VERSION "dbc-export 1 2026.26.6.5"

NS_ :

BS_:

BU_: APB APP APS DAS DPB EPAS3S EPASTS ESP GTW IBST IDB PARK RADC RCM RCM2 RCM3 RCU TPMS TRCM USM

BO_ 1470 IDB_alertLog: 8 IDB
 SG_ IDB_alertID M : 0|8@1+ (1,0) [0|255] "" Vector__XXX
 SG_ IDB_alertState : 15|1@1+ (1,0) [0|1] "" Vector__XXX
 SG_ IDB_a014_wheelSpeedSensorFreq m14 : 16|1@1+ (1,0) [0|1] "" Vector__XXX
 SG_ IDB_a014_wheelSpeedSensorPhase m14 : 17|1@1+ (1,0) [0|1] "" Vector__XXX
 SG_ IDB_a014_wheelSpeedSensorMisinst m14 : 18|1@1+ (1,0) [0|1] "" Vector__XXX
 SG_ IDB_a014_wheelSpeedSensorWrongEx m14 : 19|1@1+ (1,0) [0|1] "" Vector__XXX
 SG_ IDB_a014_wheelSpeedSensorSpeedJu m14 : 20|1@1+ (1,0) [0|1] "" Vector__XXX
 SG_ IDB_a014_wheelSpeedSensorSp_0001 m14 : 21|1@1+ (1,0) [0|1] "" Vector__XXX
 SG_ IDB_a014_wheelSpeedSensorAirGap m14 : 22|1@1+ (1,0) [0|1] "" Vector__XXX
 SG_ IDB_a014_wheelSpeedSensorBIST m14 : 23|1@1+ (1,0) [0|1] "" Vector__XXX
 SG_ IDB_a014_wheelSpeedSensorLeakage m14 : 24|1@1+ (1,0) [0|1] "" Vector__XXX
 SG_ IDB_a014_wheelSpeedSensorOverTem m14 : 25|1@1+ (1,0) [0|1] "" Vector__XXX
 SG_ IDB_a014_wheelSpeedSensorSh_0001 m14 : 26|1@1+ (1,0) [0|1] "" Vector__XXX
 SG_ IDB_a014_wheelSpeedSensorShortTo m14 : 27|1@1+ (1,0) [0|1] "" Vector__XXX
 SG_ IDB_a014_wheelSpeedSensorOpen m14 : 28|1@1+ (1,0) [0|1] "" Vector__XXX
 SG_ IDB_a015_wheelSpeedSensorFreq m15 : 16|1@1+ (1,0) [0|1] "" Vector__XXX
 SG_ IDB_a015_wheelSpeedSensorPhase m15 : 17|1@1+ (1,0) [0|1] "" Vector__XXX
 SG_ IDB_a015_wheelSpeedSensorMisinst m15 : 18|1@1+ (1,0) [0|1] "" Vector__XXX
 SG_ IDB_a015_wheelSpeedSensorWrongEx m15 : 19|1@1+ (1,0) [0|1] "" Vector__XXX
 SG_ IDB_a015_wheelSpeedSensorSpeedJu m15 : 20|1@1+ (1,0) [0|1] "" Vector__XXX
 SG_ IDB_a015_wheelSpeedSensorSp_0001 m15 : 21|1@1+ (1,0) [0|1] "" Vector__XXX
 SG_ IDB_a015_wheelSpeedSensorAirGap m15 : 22|1@1+ (1,0) [0|1] "" Vector__XXX
 SG_ IDB_a015_wheelSpeedSensorBIST m15 : 23|1@1+ (1,0) [0|1] "" Vector__XXX
 SG_ IDB_a015_wheelSpeedSensorLeakage m15 : 24|1@1+ (1,0) [0|1] "" Vector__XXX
 SG_ IDB_a015_wheelSpeedSensorOverTem m15 : 25|1@1+ (1,0) [0|1] "" Vector__XXX
 SG_ IDB_a015_wheelSpeedSensorSh_0001 m15 : 26|1@1+ (1,0) [0|1] "" Vector__XXX
 SG_ IDB_a015_wheelSpeedSensorShortTo m15 : 27|1@1+ (1,0) [0|1] "" Vector__XXX
 SG_ IDB_a015_wheelSpeedSensorOpen m15 : 28|1@1+ (1,0) [0|1] "" Vector__XXX
 SG_ IDB_a016_wheelSpeedSensorFreq m16 : 16|1@1+ (1,0) [0|1] "" Vector__XXX
 SG_ IDB_a016_wheelSpeedSensorPhase m16 : 17|1@1+ (1,0) [0|1] "" Vector__XXX
 SG_ IDB_a016_wheelSpeedSensorMisinst m16 : 18|1@1+ (1,0) [0|1] "" Vector__XXX
 SG_ IDB_a016_wheelSpeedSensorWrongEx m16 : 19|1@1+ (1,0) [0|1] "" Vector__XXX
 SG_ IDB_a016_wheelSpeedSensorSpeedJu m16 : 20|1@1+ (1,0) [0|1] "" Vector__XXX
 SG_ IDB_a016_wheelSpeedSensorSp_0001 m16 : 21|1@1+ (1,0) [0|1] "" Vector__XXX
 SG_ IDB_a016_wheelSpeedSensorAirGap m16 : 22|1@1+ (1,0) [0|1] "" Vector__XXX
 SG_ IDB_a016_wheelSpeedSensorBIST m16 : 23|1@1+ (1,0) [0|1] "" Vector__XXX
 SG_ IDB_a016_wheelSpeedSensorLeakage m16 : 24|1@1+ (1,0) [0|1] "" Vector__XXX
 SG_ IDB_a016_wheelSpeedSensorOverTem m16 : 25|1@1+ (1,0) [0|1] "" Vector__XXX
 SG_ IDB_a016_wheelSpeedSensorSh_0001 m16 : 26|1@1+ (1,0) [0|1] "" Vector__XXX
 SG_ IDB_a016_wheelSpeedSensorShortTo m16 : 27|1@1+ (1,0) [0|1] "" Vector__XXX
 SG_ IDB_a016_wheelSpeedSensorOpen m16 : 28|1@1+ (1,0) [0|1] "" Vector__XXX
 SG_ IDB_a017_wheelSpeedSensorFreq m17 : 16|1@1+ (1,0) [0|1] "" Vector__XXX
 SG_ IDB_a017_wheelSpeedSensorPhase m17 : 17|1@1+ (1,0) [0|1] "" Vector__XXX
 SG_ IDB_a017_wheelSpeedSensorMisinst m17 : 18|1@1+ (1,0) [0|1] "" Vector__XXX
 SG_ IDB_a017_wheelSpeedSensorWrongEx m17 : 19|1@1+ (1,0) [0|1] "" Vector__XXX
 SG_ IDB_a017_wheelSpeedSensorSpeedJu m17 : 20|1@1+ (1,0) [0|1] "" Vector__XXX
 SG_ IDB_a017_wheelSpeedSensorSp_0001 m17 : 21|1@1+ (1,0) [0|1] "" Vector__XXX
 SG_ IDB_a017_wheelSpeedSensorAirGap m17 : 22|1@1+ (1,0) [0|1] "" Vector__XXX
 SG_ IDB_a017_wheelSpeedSensorBIST m17 : 23|1@1+ (1,0) [0|1] "" Vector__XXX
 SG_ IDB_a017_wheelSpeedSensorLeakage m17 : 24|1@1+ (1,0) [0|1] "" Vector__XXX
 SG_ IDB_a017_wheelSpeedSensorOverTem m17 : 25|1@1+ (1,0) [0|1] "" Vector__XXX
 SG_ IDB_a017_wheelSpeedSensorSh_0001 m17 : 26|1@1+ (1,0) [0|1] "" Vector__XXX
 SG_ IDB_a017_wheelSpeedSensorShortTo m17 : 27|1@1+ (1,0) [0|1] "" Vector__XXX
 SG_ IDB_a017_wheelSpeedSensorOpen m17 : 28|1@1+ (1,0) [0|1] "" Vector__XXX
 SG_ IDB_a020_canSignalValidity m20 : 16|1@1+ (1,0) [0|1] "" Vector__XXX
 SG_ IDB_a020_signalValueCrosscheck m20 : 17|1@1+ (1,0) [0|1] "" Vector__XXX
 SG_ IDB_a030_primaryExternalCircuitL m30 : 16|1@1+ (1,0) [0|1] "" Vector__XXX
 SG_ IDB_a030_secondaryExternalCircui m30 : 17|1@1+ (1,0) [0|1] "" Vector__XXX
 SG_ IDB_a030_primaryChamberInternalL m30 : 18|1@1+ (1,0) [0|1] "" Vector__XXX
 SG_ IDB_a030_syncModeInternalLeakage m30 : 19|1@1+ (1,0) [0|1] "" Vector__XXX
 SG_ IDB_a030_secondaryChamberInterna m30 : 20|1@1+ (1,0) [0|1] "" Vector__XXX
 SG_ IDB_a030_masterCylinderInternalL m30 : 21|1@1+ (1,0) [0|1] "" Vector__XXX
 SG_ IDB_a060_validityOnChassisBus m60 : 16|1@1+ (1,0) [0|1] "" Vector__XXX
 SG_ IDB_a060_validityOnPartyBus m60 : 17|1@1+ (1,0) [0|1] "" Vector__XXX
 SG_ IDB_a061_validityOnChassisBus m61 : 16|1@1+ (1,0) [0|1] "" Vector__XXX
 SG_ IDB_a061_validityOnPartyBus m61 : 17|1@1+ (1,0) [0|1] "" Vector__XXX
 SG_ IDB_a063_validityOnChassisBus m63 : 16|1@1+ (1,0) [0|1] "" Vector__XXX
 SG_ IDB_a063_validityOnPartyBus m63 : 17|1@1+ (1,0) [0|1] "" Vector__XXX
 SG_ IDB_a064_validityOnChassisBus m64 : 16|1@1+ (1,0) [0|1] "" Vector__XXX
 SG_ IDB_a064_validityOnPartyBus m64 : 17|1@1+ (1,0) [0|1] "" Vector__XXX
 SG_ IDB_a065_validityOnChassisBus m65 : 16|1@1+ (1,0) [0|1] "" Vector__XXX
 SG_ IDB_a065_validityOnPartyBus m65 : 17|1@1+ (1,0) [0|1] "" Vector__XXX
 SG_ IDB_a106_qualifierValidity m106 : 16|1@1+ (1,0) [0|1] "" Vector__XXX
 SG_ IDB_a106_signalNotAvailable m106 : 17|1@1+ (1,0) [0|1] "" Vector__XXX
 SG_ IDB_a107_qualifierValidity m107 : 16|1@1+ (1,0) [0|1] "" Vector__XXX
 SG_ IDB_a107_signalNotAvailable m107 : 17|1@1+ (1,0) [0|1] "" Vector__XXX
 SG_ IDB_a112_qualifierValidity m112 : 16|1@1+ (1,0) [0|1] "" Vector__XXX
 SG_ IDB_a112_signalNotAvailable m112 : 17|1@1+ (1,0) [0|1] "" Vector__XXX
 SG_ IDB_a113_qualifierValidity m113 : 16|1@1+ (1,0) [0|1] "" Vector__XXX
 SG_ IDB_a113_signalNotAvailable m113 : 17|1@1+ (1,0) [0|1] "" Vector__XXX
 SG_ IDB_a114_qualifierValidity m114 : 16|1@1+ (1,0) [0|1] "" Vector__XXX
 SG_ IDB_a114_signalNotAvailable m114 : 17|1@1+ (1,0) [0|1] "" Vector__XXX
 SG_ IDB_a126_PMebrCmdStateValidity m126 : 16|1@1+ (1,0) [0|1] "" Vector__XXX
 SG_ IDB_a126_PMstate2Validity m126 : 17|1@1+ (1,0) [0|1] "" Vector__XXX
 SG_ IDB_a126_PMstate2Missing m126 : 18|1@1+ (1,0) [0|1] "" Vector__XXX
 SG_ IDB_a126_DIchassisControlValidit m126 : 19|1@1+ (1,0) [0|1] "" Vector__XXX
 SG_ IDB_a126_DIchassisControlMissing m126 : 20|1@1+ (1,0) [0|1] "" Vector__XXX
 SG_ IDB_a126_DIrequestActiveValidity m126 : 21|1@1+ (1,0) [0|1] "" Vector__XXX
 SG_ IDB_a129_validityOnChassisBus m129 : 16|1@1+ (1,0) [0|1] "" Vector__XXX
 SG_ IDB_a129_validityOnPartyBus m129 : 17|1@1+ (1,0) [0|1] "" Vector__XXX
 SG_ IDB_a130_PMbrakePedalCmdQFValidi m130 : 16|1@1+ (1,0) [0|1] "" Vector__XXX
 SG_ IDB_a130_PMstate2Validity m130 : 17|1@1+ (1,0) [0|1] "" Vector__XXX
 SG_ IDB_a130_PMstate2Missing m130 : 18|1@1+ (1,0) [0|1] "" Vector__XXX
 SG_ IDB_a130_DIbrakeCommandValidity m130 : 19|1@1+ (1,0) [0|1] "" Vector__XXX
 SG_ IDB_a130_DIbrakeCommandMissing m130 : 20|1@1+ (1,0) [0|1] "" Vector__XXX
 SG_ IDB_a130_DIbrakeTorqueCommandFul m130 : 21|1@1+ (1,0) [0|1] "" Vector__XXX
 SG_ IDB_a130_DIbrakeTorqueComma_0001 m130 : 22|1@1+ (1,0) [0|1] "" Vector__XXX
 SG_ IDB_a132_validityOnChassisBus m132 : 16|1@1+ (1,0) [0|1] "" Vector__XXX
 SG_ IDB_a132_validityOnPartyBus m132 : 17|1@1+ (1,0) [0|1] "" Vector__XXX

BO_ 983 IDB_alertMatrix: 8 IDB
 SG_ IDB_matrixIndex M : 0|4@1+ (1,0) [0|15] "" Vector__XXX
 SG_ IDB_a001_mcuGenericFault m0 : 4|1@1+ (1,0) [0|1] "" Vector__XXX
 SG_ IDB_a002_supplyOvervoltage m0 : 5|1@1+ (1,0) [0|1] "" Vector__XXX
 SG_ IDB_a003_supplyHardOvervoltage m0 : 6|1@1+ (1,0) [0|1] "" Vector__XXX
 SG_ IDB_a004_supplyUndervoltage m0 : 7|1@1+ (1,0) [0|1] "" Vector__XXX
 SG_ IDB_a005_supplyMidUndervoltage m0 : 8|1@1+ (1,0) [0|1] "" Vector__XXX
 SG_ IDB_a006_supplyHardUndervoltage m0 : 9|1@1+ (1,0) [0|1] "" Vector__XXX
 SG_ IDB_a007_wakeLineOpen m0 : 10|1@1+ (1,0) [0|1] "" Vector__XXX
 SG_ IDB_a008_motorPowerOpen m0 : 11|1@1+ (1,0) [0|1] "" Vector__XXX
 SG_ IDB_a009_asicBoostFault m0 : 12|1@1+ (1,0) [0|1] "" Vector__XXX
 SG_ IDB_a010_asicGenericFault m0 : 13|1@1+ (1,0) [0|1] "" Vector__XXX
 SG_ IDB_a011_solenoidValveFault m0 : 14|1@1+ (1,0) [0|1] "" Vector__XXX
 SG_ IDB_a012_motorGenericFault m0 : 15|1@1+ (1,0) [0|1] "" Vector__XXX
 SG_ IDB_a013_motorPosSensorFault m0 : 16|1@1+ (1,0) [0|1] "" Vector__XXX
 SG_ IDB_a014_FrLWSSFault m0 : 17|1@1+ (1,0) [0|1] "" Vector__XXX
 SG_ IDB_a015_FrRWSSFault m0 : 18|1@1+ (1,0) [0|1] "" Vector__XXX
 SG_ IDB_a016_ReLWSSFault m0 : 19|1@1+ (1,0) [0|1] "" Vector__XXX
 SG_ IDB_a017_ReRWSSFault m0 : 20|1@1+ (1,0) [0|1] "" Vector__XXX
 SG_ IDB_a018_WSSGenericFault m0 : 21|1@1+ (1,0) [0|1] "" Vector__XXX
 SG_ IDB_a019_pedalSensorFault m0 : 22|1@1+ (1,0) [0|1] "" Vector__XXX
 SG_ IDB_a020_RCUpedalTravelMismatch m0 : 23|1@1+ (1,0) [0|1] "" Vector__XXX
 SG_ IDB_a021_pedalSensorNotCal m0 : 24|1@1+ (1,0) [0|1] "" Vector__XXX
 SG_ IDB_a022_brakeFluidLow m0 : 25|1@1+ (1,0) [0|1] "" Vector__XXX
 SG_ IDB_a023_steeringImplausible m0 : 26|1@1+ (1,0) [0|1] "" Vector__XXX
 SG_ IDB_a024_yawImplausible m0 : 27|1@1+ (1,0) [0|1] "" Vector__XXX
 SG_ IDB_a025_ayImplausible m0 : 28|1@1+ (1,0) [0|1] "" Vector__XXX
 SG_ IDB_a026_axImplausible m0 : 29|1@1+ (1,0) [0|1] "" Vector__XXX
 SG_ IDB_a027_circuitPresSensorFault m0 : 30|1@1+ (1,0) [0|1] "" Vector__XXX
 SG_ IDB_a028_simPresSensorFault m0 : 31|1@1+ (1,0) [0|1] "" Vector__XXX
 SG_ IDB_a029_pressureSensNotCal m0 : 32|1@1+ (1,0) [0|1] "" Vector__XXX
 SG_ IDB_a030_fluidLeakDetected m0 : 33|1@1+ (1,0) [0|1] "" Vector__XXX
 SG_ IDB_a031_solenoidValveStuck m0 : 34|1@1+ (1,0) [0|1] "" Vector__XXX
 SG_ IDB_a032_motorSoftOverheat m0 : 35|1@1+ (1,0) [0|1] "" Vector__XXX
 SG_ IDB_a033_motorHardOverheat m0 : 36|1@1+ (1,0) [0|1] "" Vector__XXX
 SG_ IDB_a034_motorPositionSetFault m0 : 37|1@1+ (1,0) [0|1] "" Vector__XXX
 SG_ IDB_a035_motorStuck m0 : 38|1@1+ (1,0) [0|1] "" Vector__XXX
 SG_ IDB_a036_partyBusOff m0 : 39|1@1+ (1,0) [0|1] "" Vector__XXX
 SG_ IDB_a037_chassisBusOff m0 : 40|1@1+ (1,0) [0|1] "" Vector__XXX
 SG_ IDB_a038_motorInitFault m0 : 41|1@1+ (1,0) [0|1] "" Vector__XXX
 SG_ IDB_a039_absActive m0 : 42|1@1+ (1,0) [0|1] "" Vector__XXX
 SG_ IDB_a040_ebdActive m0 : 43|1@1+ (1,0) [0|1] "" Vector__XXX
 SG_ IDB_a041_vdcActive m0 : 44|1@1+ (1,0) [0|1] "" Vector__XXX
 SG_ IDB_a042_btcActive m0 : 45|1@1+ (1,0) [0|1] "" Vector__XXX
 SG_ IDB_a043_cbcActive m0 : 46|1@1+ (1,0) [0|1] "" Vector__XXX
 SG_ IDB_a044_standstillSkidDetected m0 : 47|1@1+ (1,0) [0|1] "" Vector__XXX
 SG_ IDB_a045_panicBrakeAssistActive m0 : 48|1@1+ (1,0) [0|1] "" Vector__XXX
 SG_ IDB_a046_fadeCompensationActive m0 : 49|1@1+ (1,0) [0|1] "" Vector__XXX
 SG_ IDB_a047_brakeDiscWipeActive m0 : 50|1@1+ (1,0) [0|1] "" Vector__XXX
 SG_ IDB_a048_scmActive m0 : 51|1@1+ (1,0) [0|1] "" Vector__XXX
 SG_ IDB_a049_cdpActive m0 : 52|1@1+ (1,0) [0|1] "" Vector__XXX
 SG_ IDB_a050_absFaulted m0 : 53|1@1+ (1,0) [0|1] "" Vector__XXX
 SG_ IDB_a051_ebdFaulted m0 : 54|1@1+ (1,0) [0|1] "" Vector__XXX
 SG_ IDB_a052_vdcFaulted m0 : 55|1@1+ (1,0) [0|1] "" Vector__XXX
 SG_ IDB_a053_DItorquePathFaulted m0 : 56|1@1+ (1,0) [0|1] "" Vector__XXX
 SG_ IDB_a054_skidDetectionFaulted m0 : 57|1@1+ (1,0) [0|1] "" Vector__XXX
 SG_ IDB_a055_panicBrakeAssistFaulted m0 : 58|1@1+ (1,0) [0|1] "" Vector__XXX
 SG_ IDB_a056_fadeCompensationFaulted m0 : 59|1@1+ (1,0) [0|1] "" Vector__XXX
 SG_ IDB_a057_bdwRequestInvalid m0 : 60|1@1+ (1,0) [0|1] "" Vector__XXX
 SG_ IDB_a058_scmFaulted m0 : 61|1@1+ (1,0) [0|1] "" Vector__XXX
 SG_ IDB_a059_cdpFaulted m0 : 62|1@1+ (1,0) [0|1] "" Vector__XXX
 SG_ IDB_a060_RCUstatusDLC m0 : 63|1@1+ (1,0) [0|1] "" Vector__XXX
 SG_ IDB_a061_RCUstatusChecksum m1 : 4|1@1+ (1,0) [0|1] "" Vector__XXX
 SG_ IDB_a062_RCUstatusCounter m1 : 5|1@1+ (1,0) [0|1] "" Vector__XXX
 SG_ IDB_a063_RCUactuationDLC m1 : 6|1@1+ (1,0) [0|1] "" Vector__XXX
 SG_ IDB_a064_RCUactuationChecksum m1 : 7|1@1+ (1,0) [0|1] "" Vector__XXX
 SG_ IDB_a065_RCUactuationCounter m1 : 8|1@1+ (1,0) [0|1] "" Vector__XXX
 SG_ IDB_a066_DIFtorqueDLC m1 : 9|1@1+ (1,0) [0|1] "" Vector__XXX
 SG_ IDB_a067_DIFtorqueChecksum m1 : 10|1@1+ (1,0) [0|1] "" Vector__XXX
 SG_ IDB_a068_DIFtorqueCounter m1 : 11|1@1+ (1,0) [0|1] "" Vector__XXX
 SG_ IDB_a069_DIchassisControlDLC m1 : 12|1@1+ (1,0) [0|1] "" Vector__XXX
 SG_ IDB_a070_DIchassisControlChecksu m1 : 13|1@1+ (1,0) [0|1] "" Vector__XXX
 SG_ IDB_a071_DIchassisControlCounter m1 : 14|1@1+ (1,0) [0|1] "" Vector__XXX
 SG_ IDB_a072_DIsystemStatusDLC m1 : 15|1@1+ (1,0) [0|1] "" Vector__XXX
 SG_ IDB_a073_DIsystemStatusChecksum m1 : 16|1@1+ (1,0) [0|1] "" Vector__XXX
 SG_ IDB_a074_DIsystemStatusCounter m1 : 17|1@1+ (1,0) [0|1] "" Vector__XXX
 SG_ IDB_a075_DIRtorqueDLC m1 : 18|1@1+ (1,0) [0|1] "" Vector__XXX
 SG_ IDB_a076_DIRtorqueChecksum m1 : 19|1@1+ (1,0) [0|1] "" Vector__XXX
 SG_ IDB_a077_DIRtorqueCounter m1 : 20|1@1+ (1,0) [0|1] "" Vector__XXX
 SG_ IDB_a078_DIvdcLeftDLC m1 : 21|1@1+ (1,0) [0|1] "" Vector__XXX
 SG_ IDB_a079_DIvdcLeftChecksum m1 : 22|1@1+ (1,0) [0|1] "" Vector__XXX
 SG_ IDB_a080_DIvdcLeftCounter m1 : 23|1@1+ (1,0) [0|1] "" Vector__XXX
 SG_ IDB_a081_DIvdcRightDLC m1 : 24|1@1+ (1,0) [0|1] "" Vector__XXX
 SG_ IDB_a082_DIvdcRightChecksum m1 : 25|1@1+ (1,0) [0|1] "" Vector__XXX
 SG_ IDB_a083_DIvdcRightCounter m1 : 26|1@1+ (1,0) [0|1] "" Vector__XXX
 SG_ IDB_a084_EPAS3PsysStatusDLC m1 : 27|1@1+ (1,0) [0|1] "" Vector__XXX
 SG_ IDB_a085_EPAS3PsysStatusChecksum m1 : 28|1@1+ (1,0) [0|1] "" Vector__XXX
 SG_ IDB_a086_EPAS3PsysStatusCounter m1 : 29|1@1+ (1,0) [0|1] "" Vector__XXX
 SG_ IDB_a087_PMstate2DLC m1 : 30|1@1+ (1,0) [0|1] "" Vector__XXX
 SG_ IDB_a088_PMstate2Checksum m1 : 31|1@1+ (1,0) [0|1] "" Vector__XXX
 SG_ IDB_a089_PMstate2Counter m1 : 32|1@1+ (1,0) [0|1] "" Vector__XXX
 SG_ IDB_a090_RCMinertial1DLC m1 : 33|1@1+ (1,0) [0|1] "" Vector__XXX
 SG_ IDB_a091_RCMinertial1Checksum m1 : 34|1@1+ (1,0) [0|1] "" Vector__XXX
 SG_ IDB_a092_RCMinertial1Counter m1 : 35|1@1+ (1,0) [0|1] "" Vector__XXX
 SG_ IDB_a093_RCMinertial2DLC m1 : 36|1@1+ (1,0) [0|1] "" Vector__XXX
 SG_ IDB_a094_RCMinertial2Checksum m1 : 37|1@1+ (1,0) [0|1] "" Vector__XXX
 SG_ IDB_a095_RCMinertial2Counter m1 : 38|1@1+ (1,0) [0|1] "" Vector__XXX
 SG_ IDB_a096_VCFRONTLVPowerStateDLC m1 : 39|1@1+ (1,0) [0|1] "" Vector__XXX
 SG_ IDB_a097_VCFRONTLVPwrStChecksum m1 : 40|1@1+ (1,0) [0|1] "" Vector__XXX
 SG_ IDB_a098_VCFRONTLVPwrStCounter m1 : 41|1@1+ (1,0) [0|1] "" Vector__XXX
 SG_ IDB_a099_RCMcollisionDLC m1 : 42|1@1+ (1,0) [0|1] "" Vector__XXX
 SG_ IDB_a100_RCMcollisionChecksum m1 : 43|1@1+ (1,0) [0|1] "" Vector__XXX
 SG_ IDB_a101_RCMcollisionCounter m1 : 44|1@1+ (1,0) [0|1] "" Vector__XXX
 SG_ IDB_a102_bdwRequestActiveInvalid m1 : 45|1@1+ (1,0) [0|1] "" Vector__XXX
 SG_ IDB_a103_DIfullTorquePathFaulted m1 : 46|1@1+ (1,0) [0|1] "" Vector__XXX
 SG_ IDB_a104_DIaccelPosInvalid m1 : 47|1@1+ (1,0) [0|1] "" Vector__XXX
 SG_ IDB_a105_DIgearInvalid m1 : 48|1@1+ (1,0) [0|1] "" Vector__XXX
 SG_ IDB_a106_DIFtorqueInvalid m1 : 49|1@1+ (1,0) [0|1] "" Vector__XXX
 SG_ IDB_a107_DIRtorqueInvalid m1 : 50|1@1+ (1,0) [0|1] "" Vector__XXX
 SG_ IDB_a108_EPBstatusDLC m1 : 51|1@1+ (1,0) [0|1] "" Vector__XXX
 SG_ IDB_a109_BDWsignalInvalid m1 : 52|1@1+ (1,0) [0|1] "" Vector__XXX
 SG_ IDB_a110_EPBstatusCounter m1 : 53|1@1+ (1,0) [0|1] "" Vector__XXX
 SG_ IDB_a111_EPBstatusChecksum m1 : 54|1@1+ (1,0) [0|1] "" Vector__XXX
 SG_ IDB_a112_yawRateInvalid m1 : 55|1@1+ (1,0) [0|1] "" Vector__XXX
 SG_ IDB_a113_latAccelInvalid m1 : 56|1@1+ (1,0) [0|1] "" Vector__XXX
 SG_ IDB_a114_longAccelInvalid m1 : 57|1@1+ (1,0) [0|1] "" Vector__XXX
 SG_ IDB_a115_VCFRONTespLvStInvalid m1 : 58|1@1+ (1,0) [0|1] "" Vector__XXX
 SG_ IDB_a116_VCFRONTsensorsDLC m1 : 59|1@1+ (1,0) [0|1] "" Vector__XXX
 SG_ IDB_a117_VCLEFTepbmStatusDLC m1 : 60|1@1+ (1,0) [0|1] "" Vector__XXX
 SG_ IDB_a118_VCLEFTepbmStatusCounter m1 : 61|1@1+ (1,0) [0|1] "" Vector__XXX
 SG_ IDB_a119_VCLEFTepbmStatusChecksu m1 : 62|1@1+ (1,0) [0|1] "" Vector__XXX
 SG_ IDB_a120_EPAS3Pinvalid m1 : 63|1@1+ (1,0) [0|1] "" Vector__XXX
 SG_ IDB_a121_dynoModeActive m2 : 4|1@1+ (1,0) [0|1] "" Vector__XXX
 SG_ IDB_a122_DIFtorqueCommandInvalid m2 : 5|1@1+ (1,0) [0|1] "" Vector__XXX
 SG_ IDB_a123_DIRtorqueCommandInvalid m2 : 6|1@1+ (1,0) [0|1] "" Vector__XXX
 SG_ IDB_a124_VCFRONTtempInvalid m2 : 7|1@1+ (1,0) [0|1] "" Vector__XXX
 SG_ IDB_a125_PMvdcCmdStateInvalid m2 : 8|1@1+ (1,0) [0|1] "" Vector__XXX
 SG_ IDB_a126_DItorqueRequestInvalid m2 : 9|1@1+ (1,0) [0|1] "" Vector__XXX
 SG_ IDB_a127_brakeFluidLevelInvalid m2 : 10|1@1+ (1,0) [0|1] "" Vector__XXX
 SG_ IDB_a128_largeAirVolume m2 : 11|1@1+ (1,0) [0|1] "" Vector__XXX
 SG_ IDB_a129_RCUinputRodStrokeInvali m2 : 12|1@1+ (1,0) [0|1] "" Vector__XXX
 SG_ IDB_a130_DIfullTorqueRequestInva m2 : 13|1@1+ (1,0) [0|1] "" Vector__XXX
 SG_ IDB_a131_cbcFaulted m2 : 14|1@1+ (1,0) [0|1] "" Vector__XXX
 SG_ IDB_a132_RCUinputRodStrokeQFInva m2 : 15|1@1+ (1,0) [0|1] "" Vector__XXX
 SG_ IDB_a133_DIbrakeCommandDLC m2 : 16|1@1+ (1,0) [0|1] "" Vector__XXX
 SG_ IDB_a134_DIbrakeCommandCounter m2 : 17|1@1+ (1,0) [0|1] "" Vector__XXX
 SG_ IDB_a135_DIbrakeCommandChecksum m2 : 18|1@1+ (1,0) [0|1] "" Vector__XXX
 SG_ IDB_a136_RCUptsCalMissing m2 : 19|1@1+ (1,0) [0|1] "" Vector__XXX
 SG_ IDB_a137_VCLEFTcdpRequestInvalid m2 : 20|1@1+ (1,0) [0|1] "" Vector__XXX
 SG_ IDB_a138_DIbrakeTorqueCommandAnd m2 : 21|1@1+ (1,0) [0|1] "" Vector__XXX
 SG_ IDB_a139_DIbrakeTorqueCommandFul m2 : 22|1@1+ (1,0) [0|1] "" Vector__XXX
 SG_ IDB_a140_PMbrakePedalCmdQFInvali m2 : 23|1@1+ (1,0) [0|1] "" Vector__XXX
 SG_ IDB_a141_DIbrakeTorqueCommandFul m2 : 24|1@1+ (1,0) [0|1] "" Vector__XXX
 SG_ IDB_a142_PMebrCmdStateInvalid m2 : 25|1@1+ (1,0) [0|1] "" Vector__XXX
 SG_ IDB_a143_factoryModeActive m2 : 26|1@1+ (1,0) [0|1] "" Vector__XXX
 SG_ IDB_a144_hydraulicPushthroughAct m2 : 27|1@1+ (1,0) [0|1] "" Vector__XXX
 SG_ IDB_a145_DASredundantBrakingCont m2 : 28|1@1+ (1,0) [0|1] "" Vector__XXX
 SG_ IDB_a146_DASredundantBrakingCont m2 : 29|1@1+ (1,0) [0|1] "" Vector__XXX
 SG_ IDB_a147_DASredundantBrakingCont m2 : 30|1@1+ (1,0) [0|1] "" Vector__XXX
 SG_ IDB_a148_DASbrakeTorqueCommandIn m2 : 31|1@1+ (1,0) [0|1] "" Vector__XXX
 SG_ IDB_a149_DASmiaBrakeTorqueComman m2 : 32|1@1+ (1,0) [0|1] "" Vector__XXX
 SG_ IDB_a150_DIlocStatus2DLC m2 : 33|1@1+ (1,0) [0|1] "" Vector__XXX
 SG_ IDB_a151_DIlocStatus2Counter m2 : 34|1@1+ (1,0) [0|1] "" Vector__XXX
 SG_ IDB_a152_DIlocStatus2Checksum m2 : 35|1@1+ (1,0) [0|1] "" Vector__XXX
 SG_ IDB_a155_PMlocStateDLC m2 : 38|1@1+ (1,0) [0|1] "" Vector__XXX
 SG_ IDB_a156_PMlocStateChecksum m2 : 39|1@1+ (1,0) [0|1] "" Vector__XXX
 SG_ IDB_a157_PMlocStateCounter m2 : 40|1@1+ (1,0) [0|1] "" Vector__XXX

BO_ 828 IDB_info: 8 IDB
 SG_ IDB_infoIndex M : 0|8@1+ (1,0) [0|255] "" Vector__XXX
 SG_ IDB_infoPcbaID m11 : 16|8@1+ (1,0) [0|255] "" Vector__XXX
 SG_ IDB_infoAssemblyID m11 : 24|8@1+ (1,0) [0|255] "" Vector__XXX
 SG_ IDB_infoUsageID m11 : 32|16@1+ (1,0) [0|65535] "" Vector__XXX
 SG_ IDB_infoSubUsageID m11 : 48|16@1+ (1,0) [0|65535] "" Vector__XXX

BO_ 1486 PARK_alertLog: 8 PARK
 SG_ PARK_alertID M : 0|7@1+ (1,0) [0|127] "" Vector__XXX
 SG_ PARK_alertState : 15|1@1+ (1,0) [0|1] "" Vector__XXX
 SG_ PARK_sw001_sensorTemperature m1 : 16|16@1+ (0.1,-40) [-40|6513.5] "deg" Vector__XXX
 SG_ PARK_sw002_membraneDisconct m2 : 16|1@1+ (1,0) [0|1] "" Vector__XXX
 SG_ PARK_sw002_dampResistorFail m2 : 17|1@1+ (1,0) [0|1] "" Vector__XXX
 SG_ PARK_sw002_resonanceDrift m2 : 18|1@1+ (1,0) [0|1] "" Vector__XXX
 SG_ PARK_sw002_sensorCRC m2 : 19|1@1+ (1,0) [0|1] "" Vector__XXX
 SG_ PARK_sw002_recieveFailure m2 : 20|1@1+ (1,0) [0|1] "" Vector__XXX
 SG_ PARK_sw002_diagnosticTransferErr m2 : 21|1@1+ (1,0) [0|1] "" Vector__XXX
 SG_ PARK_sw003_linError m3 : 16|1@1+ (1,0) [0|1] "" Vector__XXX
 SG_ PARK_sw003_linBusError m3 : 17|1@1+ (1,0) [0|1] "" Vector__XXX
 SG_ PARK_sw003_linFrameCountError m3 : 18|1@1+ (1,0) [0|1] "" Vector__XXX
 SG_ PARK_sw004_reverbPeriod m4 : 16|16@1+ (1,0) [0|65535] "microseconds" Vector__XXX
 SG_ PARK_sw004_reverbTime m4 : 32|16@1+ (1,0) [0|65535] "microseconds" Vector__XXX
 SG_ PARK_sw004_highAttenTime m4 : 48|1@1+ (1,0) [0|1] "" Vector__XXX
 SG_ PARK_sw004_closeConstEcho m4 : 49|1@1+ (1,0) [0|1] "" Vector__XXX
 SG_ PARK_sw004_lowAttenTime m4 : 50|1@1+ (1,0) [0|1] "" Vector__XXX
 SG_ PARK_sw004_attenTimeJitter m4 : 51|1@1+ (1,0) [0|1] "" Vector__XXX
 SG_ PARK_sw004_reverbFreqJitter m4 : 52|1@1+ (1,0) [0|1] "" Vector__XXX
 SG_ PARK_sw006_sensorTemperature m6 : 16|16@1+ (0.1,-40) [-40|6513.5] "deg" Vector__XXX
 SG_ PARK_sw007_membraneDisconct m7 : 16|1@1+ (1,0) [0|1] "" Vector__XXX
 SG_ PARK_sw007_dampResistorFail m7 : 17|1@1+ (1,0) [0|1] "" Vector__XXX
 SG_ PARK_sw007_resonanceDrift m7 : 18|1@1+ (1,0) [0|1] "" Vector__XXX
 SG_ PARK_sw007_sensorCRC m7 : 19|1@1+ (1,0) [0|1] "" Vector__XXX
 SG_ PARK_sw007_recieveFailure m7 : 20|1@1+ (1,0) [0|1] "" Vector__XXX
 SG_ PARK_sw007_diagnosticTransferErr m7 : 21|1@1+ (1,0) [0|1] "" Vector__XXX
 SG_ PARK_sw008_linError m8 : 16|1@1+ (1,0) [0|1] "" Vector__XXX
 SG_ PARK_sw008_linBusError m8 : 17|1@1+ (1,0) [0|1] "" Vector__XXX
 SG_ PARK_sw008_linFrameCountError m8 : 18|1@1+ (1,0) [0|1] "" Vector__XXX
 SG_ PARK_sw009_reverbPeriod m9 : 16|16@1+ (1,0) [0|65535] "microseconds" Vector__XXX
 SG_ PARK_sw009_reverbTime m9 : 32|16@1+ (1,0) [0|65535] "microseconds" Vector__XXX
 SG_ PARK_sw009_highAttenTime m9 : 48|1@1+ (1,0) [0|1] "" Vector__XXX
 SG_ PARK_sw009_closeConstEcho m9 : 49|1@1+ (1,0) [0|1] "" Vector__XXX
 SG_ PARK_sw009_lowAttenTime m9 : 50|1@1+ (1,0) [0|1] "" Vector__XXX
 SG_ PARK_sw009_attenTimeJitter m9 : 51|1@1+ (1,0) [0|1] "" Vector__XXX
 SG_ PARK_sw009_reverbFreqJitter m9 : 52|1@1+ (1,0) [0|1] "" Vector__XXX
 SG_ PARK_sw011_sensorTemperature m11 : 16|16@1+ (0.1,-40) [-40|6513.5] "deg" Vector__XXX
 SG_ PARK_sw012_membraneDisconct m12 : 16|1@1+ (1,0) [0|1] "" Vector__XXX
 SG_ PARK_sw012_dampResistorFail m12 : 17|1@1+ (1,0) [0|1] "" Vector__XXX
 SG_ PARK_sw012_resonanceDrift m12 : 18|1@1+ (1,0) [0|1] "" Vector__XXX
 SG_ PARK_sw012_sensorCRC m12 : 19|1@1+ (1,0) [0|1] "" Vector__XXX
 SG_ PARK_sw012_recieveFailure m12 : 20|1@1+ (1,0) [0|1] "" Vector__XXX
 SG_ PARK_sw012_diagnosticTransferErr m12 : 21|1@1+ (1,0) [0|1] "" Vector__XXX
 SG_ PARK_sw013_linError m13 : 16|1@1+ (1,0) [0|1] "" Vector__XXX
 SG_ PARK_sw013_linBusError m13 : 17|1@1+ (1,0) [0|1] "" Vector__XXX
 SG_ PARK_sw013_linFrameCountError m13 : 18|1@1+ (1,0) [0|1] "" Vector__XXX
 SG_ PARK_sw014_reverbPeriod m14 : 16|16@1+ (1,0) [0|65535] "microseconds" Vector__XXX
 SG_ PARK_sw014_reverbTime m14 : 32|16@1+ (1,0) [0|65535] "microseconds" Vector__XXX
 SG_ PARK_sw014_highAttenTime m14 : 48|1@1+ (1,0) [0|1] "" Vector__XXX
 SG_ PARK_sw014_closeConstEcho m14 : 49|1@1+ (1,0) [0|1] "" Vector__XXX
 SG_ PARK_sw014_lowAttenTime m14 : 50|1@1+ (1,0) [0|1] "" Vector__XXX
 SG_ PARK_sw014_attenTimeJitter m14 : 51|1@1+ (1,0) [0|1] "" Vector__XXX
 SG_ PARK_sw014_reverbFreqJitter m14 : 52|1@1+ (1,0) [0|1] "" Vector__XXX
 SG_ PARK_sw016_sensorTemperature m16 : 16|16@1+ (0.1,-40) [-40|6513.5] "deg" Vector__XXX
 SG_ PARK_sw017_membraneDisconct m17 : 16|1@1+ (1,0) [0|1] "" Vector__XXX
 SG_ PARK_sw017_dampResistorFail m17 : 17|1@1+ (1,0) [0|1] "" Vector__XXX
 SG_ PARK_sw017_resonanceDrift m17 : 18|1@1+ (1,0) [0|1] "" Vector__XXX
 SG_ PARK_sw017_sensorCRC m17 : 19|1@1+ (1,0) [0|1] "" Vector__XXX
 SG_ PARK_sw017_recieveFailure m17 : 20|1@1+ (1,0) [0|1] "" Vector__XXX
 SG_ PARK_sw017_diagnosticTransferErr m17 : 21|1@1+ (1,0) [0|1] "" Vector__XXX
 SG_ PARK_sw018_linError m18 : 16|1@1+ (1,0) [0|1] "" Vector__XXX
 SG_ PARK_sw018_linBusError m18 : 17|1@1+ (1,0) [0|1] "" Vector__XXX
 SG_ PARK_sw018_linFrameCountError m18 : 18|1@1+ (1,0) [0|1] "" Vector__XXX
 SG_ PARK_sw019_reverbPeriod m19 : 16|16@1+ (1,0) [0|65535] "microseconds" Vector__XXX
 SG_ PARK_sw019_reverbTime m19 : 32|16@1+ (1,0) [0|65535] "microseconds" Vector__XXX
 SG_ PARK_sw019_highAttenTime m19 : 48|1@1+ (1,0) [0|1] "" Vector__XXX
 SG_ PARK_sw019_closeConstEcho m19 : 49|1@1+ (1,0) [0|1] "" Vector__XXX
 SG_ PARK_sw019_lowAttenTime m19 : 50|1@1+ (1,0) [0|1] "" Vector__XXX
 SG_ PARK_sw019_attenTimeJitter m19 : 51|1@1+ (1,0) [0|1] "" Vector__XXX
 SG_ PARK_sw019_reverbFreqJitter m19 : 52|1@1+ (1,0) [0|1] "" Vector__XXX
 SG_ PARK_sw021_sensorTemperature m21 : 16|16@1+ (0.1,-40) [-40|6513.5] "deg" Vector__XXX
 SG_ PARK_sw022_membraneDisconct m22 : 16|1@1+ (1,0) [0|1] "" Vector__XXX
 SG_ PARK_sw022_dampResistorFail m22 : 17|1@1+ (1,0) [0|1] "" Vector__XXX
 SG_ PARK_sw022_resonanceDrift m22 : 18|1@1+ (1,0) [0|1] "" Vector__XXX
 SG_ PARK_sw022_sensorCRC m22 : 19|1@1+ (1,0) [0|1] "" Vector__XXX
 SG_ PARK_sw022_recieveFailure m22 : 20|1@1+ (1,0) [0|1] "" Vector__XXX
 SG_ PARK_sw022_diagnosticTransferErr m22 : 21|1@1+ (1,0) [0|1] "" Vector__XXX
 SG_ PARK_sw023_linError m23 : 16|1@1+ (1,0) [0|1] "" Vector__XXX
 SG_ PARK_sw023_linBusError m23 : 17|1@1+ (1,0) [0|1] "" Vector__XXX
 SG_ PARK_sw023_linFrameCountError m23 : 18|1@1+ (1,0) [0|1] "" Vector__XXX
 SG_ PARK_sw024_reverbPeriod m24 : 16|16@1+ (1,0) [0|65535] "microseconds" Vector__XXX
 SG_ PARK_sw024_reverbTime m24 : 32|16@1+ (1,0) [0|65535] "microseconds" Vector__XXX
 SG_ PARK_sw024_highAttenTime m24 : 48|1@1+ (1,0) [0|1] "" Vector__XXX
 SG_ PARK_sw024_closeConstEcho m24 : 49|1@1+ (1,0) [0|1] "" Vector__XXX
 SG_ PARK_sw024_lowAttenTime m24 : 50|1@1+ (1,0) [0|1] "" Vector__XXX
 SG_ PARK_sw024_attenTimeJitter m24 : 51|1@1+ (1,0) [0|1] "" Vector__XXX
 SG_ PARK_sw024_reverbFreqJitter m24 : 52|1@1+ (1,0) [0|1] "" Vector__XXX
 SG_ PARK_sw026_sensorTemperature m26 : 16|16@1+ (0.1,-40) [-40|6513.5] "deg" Vector__XXX
 SG_ PARK_sw027_membraneDisconct m27 : 16|1@1+ (1,0) [0|1] "" Vector__XXX
 SG_ PARK_sw027_dampResistorFail m27 : 17|1@1+ (1,0) [0|1] "" Vector__XXX
 SG_ PARK_sw027_resonanceDrift m27 : 18|1@1+ (1,0) [0|1] "" Vector__XXX
 SG_ PARK_sw027_sensorCRC m27 : 19|1@1+ (1,0) [0|1] "" Vector__XXX
 SG_ PARK_sw027_recieveFailure m27 : 20|1@1+ (1,0) [0|1] "" Vector__XXX
 SG_ PARK_sw027_diagnosticTransferErr m27 : 21|1@1+ (1,0) [0|1] "" Vector__XXX
 SG_ PARK_sw028_linError m28 : 16|1@1+ (1,0) [0|1] "" Vector__XXX
 SG_ PARK_sw028_linBusError m28 : 17|1@1+ (1,0) [0|1] "" Vector__XXX
 SG_ PARK_sw028_linFrameCountError m28 : 18|1@1+ (1,0) [0|1] "" Vector__XXX
 SG_ PARK_sw029_reverbPeriod m29 : 16|16@1+ (1,0) [0|65535] "microseconds" Vector__XXX
 SG_ PARK_sw029_reverbTime m29 : 32|16@1+ (1,0) [0|65535] "microseconds" Vector__XXX
 SG_ PARK_sw029_highAttenTime m29 : 48|1@1+ (1,0) [0|1] "" Vector__XXX
 SG_ PARK_sw029_closeConstEcho m29 : 49|1@1+ (1,0) [0|1] "" Vector__XXX
 SG_ PARK_sw029_lowAttenTime m29 : 50|1@1+ (1,0) [0|1] "" Vector__XXX
 SG_ PARK_sw029_attenTimeJitter m29 : 51|1@1+ (1,0) [0|1] "" Vector__XXX
 SG_ PARK_sw029_reverbFreqJitter m29 : 52|1@1+ (1,0) [0|1] "" Vector__XXX
 SG_ PARK_sw031_sensorTemperature m31 : 16|16@1+ (0.1,-40) [-40|6513.5] "deg" Vector__XXX
 SG_ PARK_sw032_membraneDisconct m32 : 16|1@1+ (1,0) [0|1] "" Vector__XXX
 SG_ PARK_sw032_dampResistorFail m32 : 17|1@1+ (1,0) [0|1] "" Vector__XXX
 SG_ PARK_sw032_resonanceDrift m32 : 18|1@1+ (1,0) [0|1] "" Vector__XXX
 SG_ PARK_sw032_sensorCRC m32 : 19|1@1+ (1,0) [0|1] "" Vector__XXX
 SG_ PARK_sw032_recieveFailure m32 : 20|1@1+ (1,0) [0|1] "" Vector__XXX
 SG_ PARK_sw032_diagnosticTransferErr m32 : 21|1@1+ (1,0) [0|1] "" Vector__XXX
 SG_ PARK_sw033_linError m33 : 16|1@1+ (1,0) [0|1] "" Vector__XXX
 SG_ PARK_sw033_linBusError m33 : 17|1@1+ (1,0) [0|1] "" Vector__XXX
 SG_ PARK_sw033_linFrameCountError m33 : 18|1@1+ (1,0) [0|1] "" Vector__XXX
 SG_ PARK_sw034_reverbPeriod m34 : 16|16@1+ (1,0) [0|65535] "microseconds" Vector__XXX
 SG_ PARK_sw034_reverbTime m34 : 32|16@1+ (1,0) [0|65535] "microseconds" Vector__XXX
 SG_ PARK_sw034_highAttenTime m34 : 48|1@1+ (1,0) [0|1] "" Vector__XXX
 SG_ PARK_sw034_closeConstEcho m34 : 49|1@1+ (1,0) [0|1] "" Vector__XXX
 SG_ PARK_sw034_lowAttenTime m34 : 50|1@1+ (1,0) [0|1] "" Vector__XXX
 SG_ PARK_sw034_attenTimeJitter m34 : 51|1@1+ (1,0) [0|1] "" Vector__XXX
 SG_ PARK_sw034_reverbFreqJitter m34 : 52|1@1+ (1,0) [0|1] "" Vector__XXX
 SG_ PARK_sw036_sensorTemperature m36 : 16|16@1+ (0.1,-40) [-40|6513.5] "deg" Vector__XXX
 SG_ PARK_sw037_membraneDisconct m37 : 16|1@1+ (1,0) [0|1] "" Vector__XXX
 SG_ PARK_sw037_dampResistorFail m37 : 17|1@1+ (1,0) [0|1] "" Vector__XXX
 SG_ PARK_sw037_resonanceDrift m37 : 18|1@1+ (1,0) [0|1] "" Vector__XXX
 SG_ PARK_sw037_sensorCRC m37 : 19|1@1+ (1,0) [0|1] "" Vector__XXX
 SG_ PARK_sw037_recieveFailure m37 : 20|1@1+ (1,0) [0|1] "" Vector__XXX
 SG_ PARK_sw037_diagnosticTransferErr m37 : 21|1@1+ (1,0) [0|1] "" Vector__XXX
 SG_ PARK_sw038_linError m38 : 16|1@1+ (1,0) [0|1] "" Vector__XXX
 SG_ PARK_sw038_linBusError m38 : 17|1@1+ (1,0) [0|1] "" Vector__XXX
 SG_ PARK_sw038_linFrameCountError m38 : 18|1@1+ (1,0) [0|1] "" Vector__XXX
 SG_ PARK_sw039_reverbPeriod m39 : 16|16@1+ (1,0) [0|65535] "microseconds" Vector__XXX
 SG_ PARK_sw039_reverbTime m39 : 32|16@1+ (1,0) [0|65535] "microseconds" Vector__XXX
 SG_ PARK_sw039_highAttenTime m39 : 48|1@1+ (1,0) [0|1] "" Vector__XXX
 SG_ PARK_sw039_closeConstEcho m39 : 49|1@1+ (1,0) [0|1] "" Vector__XXX
 SG_ PARK_sw039_lowAttenTime m39 : 50|1@1+ (1,0) [0|1] "" Vector__XXX
 SG_ PARK_sw039_attenTimeJitter m39 : 51|1@1+ (1,0) [0|1] "" Vector__XXX
 SG_ PARK_sw039_reverbFreqJitter m39 : 52|1@1+ (1,0) [0|1] "" Vector__XXX
 SG_ PARK_sw041_sensorTemperature m41 : 16|16@1+ (0.1,-40) [-40|6513.5] "deg" Vector__XXX
 SG_ PARK_sw042_membraneDisconct m42 : 16|1@1+ (1,0) [0|1] "" Vector__XXX
 SG_ PARK_sw042_dampResistorFail m42 : 17|1@1+ (1,0) [0|1] "" Vector__XXX
 SG_ PARK_sw042_resonanceDrift m42 : 18|1@1+ (1,0) [0|1] "" Vector__XXX
 SG_ PARK_sw042_sensorCRC m42 : 19|1@1+ (1,0) [0|1] "" Vector__XXX
 SG_ PARK_sw042_recieveFailure m42 : 20|1@1+ (1,0) [0|1] "" Vector__XXX
 SG_ PARK_sw042_diagnosticTransferErr m42 : 21|1@1+ (1,0) [0|1] "" Vector__XXX
 SG_ PARK_sw043_linError m43 : 16|1@1+ (1,0) [0|1] "" Vector__XXX
 SG_ PARK_sw043_linBusError m43 : 17|1@1+ (1,0) [0|1] "" Vector__XXX
 SG_ PARK_sw043_linFrameCountError m43 : 18|1@1+ (1,0) [0|1] "" Vector__XXX
 SG_ PARK_sw044_reverbPeriod m44 : 16|16@1+ (1,0) [0|65535] "microseconds" Vector__XXX
 SG_ PARK_sw044_reverbTime m44 : 32|16@1+ (1,0) [0|65535] "microseconds" Vector__XXX
 SG_ PARK_sw044_highAttenTime m44 : 48|1@1+ (1,0) [0|1] "" Vector__XXX
 SG_ PARK_sw044_closeConstEcho m44 : 49|1@1+ (1,0) [0|1] "" Vector__XXX
 SG_ PARK_sw044_lowAttenTime m44 : 50|1@1+ (1,0) [0|1] "" Vector__XXX
 SG_ PARK_sw044_attenTimeJitter m44 : 51|1@1+ (1,0) [0|1] "" Vector__XXX
 SG_ PARK_sw044_reverbFreqJitter m44 : 52|1@1+ (1,0) [0|1] "" Vector__XXX
 SG_ PARK_sw046_sensorTemperature m46 : 16|16@1+ (0.1,-40) [-40|6513.5] "deg" Vector__XXX
 SG_ PARK_sw047_membraneDisconct m47 : 16|1@1+ (1,0) [0|1] "" Vector__XXX
 SG_ PARK_sw047_dampResistorFail m47 : 17|1@1+ (1,0) [0|1] "" Vector__XXX
 SG_ PARK_sw047_resonanceDrift m47 : 18|1@1+ (1,0) [0|1] "" Vector__XXX
 SG_ PARK_sw047_sensorCRC m47 : 19|1@1+ (1,0) [0|1] "" Vector__XXX
 SG_ PARK_sw047_recieveFailure m47 : 20|1@1+ (1,0) [0|1] "" Vector__XXX
 SG_ PARK_sw047_diagnosticTransferErr m47 : 21|1@1+ (1,0) [0|1] "" Vector__XXX
 SG_ PARK_sw048_linError m48 : 16|1@1+ (1,0) [0|1] "" Vector__XXX
 SG_ PARK_sw048_linBusError m48 : 17|1@1+ (1,0) [0|1] "" Vector__XXX
 SG_ PARK_sw048_linFrameCountError m48 : 18|1@1+ (1,0) [0|1] "" Vector__XXX
 SG_ PARK_sw049_reverbPeriod m49 : 16|16@1+ (1,0) [0|65535] "microseconds" Vector__XXX
 SG_ PARK_sw049_reverbTime m49 : 32|16@1+ (1,0) [0|65535] "microseconds" Vector__XXX
 SG_ PARK_sw049_highAttenTime m49 : 48|1@1+ (1,0) [0|1] "" Vector__XXX
 SG_ PARK_sw049_closeConstEcho m49 : 49|1@1+ (1,0) [0|1] "" Vector__XXX
 SG_ PARK_sw049_lowAttenTime m49 : 50|1@1+ (1,0) [0|1] "" Vector__XXX
 SG_ PARK_sw049_attenTimeJitter m49 : 51|1@1+ (1,0) [0|1] "" Vector__XXX
 SG_ PARK_sw049_reverbFreqJitter m49 : 52|1@1+ (1,0) [0|1] "" Vector__XXX
 SG_ PARK_sw051_sensorTemperature m51 : 16|16@1+ (0.1,-40) [-40|6513.5] "deg" Vector__XXX
 SG_ PARK_sw052_membraneDisconct m52 : 16|1@1+ (1,0) [0|1] "" Vector__XXX
 SG_ PARK_sw052_dampResistorFail m52 : 17|1@1+ (1,0) [0|1] "" Vector__XXX
 SG_ PARK_sw052_resonanceDrift m52 : 18|1@1+ (1,0) [0|1] "" Vector__XXX
 SG_ PARK_sw052_sensorCRC m52 : 19|1@1+ (1,0) [0|1] "" Vector__XXX
 SG_ PARK_sw052_recieveFailure m52 : 20|1@1+ (1,0) [0|1] "" Vector__XXX
 SG_ PARK_sw052_diagnosticTransferErr m52 : 21|1@1+ (1,0) [0|1] "" Vector__XXX
 SG_ PARK_sw053_linError m53 : 16|1@1+ (1,0) [0|1] "" Vector__XXX
 SG_ PARK_sw053_linBusError m53 : 17|1@1+ (1,0) [0|1] "" Vector__XXX
 SG_ PARK_sw053_linFrameCountError m53 : 18|1@1+ (1,0) [0|1] "" Vector__XXX
 SG_ PARK_sw054_reverbPeriod m54 : 16|16@1+ (1,0) [0|65535] "microseconds" Vector__XXX
 SG_ PARK_sw054_reverbTime m54 : 32|16@1+ (1,0) [0|65535] "microseconds" Vector__XXX
 SG_ PARK_sw054_highAttenTime m54 : 48|1@1+ (1,0) [0|1] "" Vector__XXX
 SG_ PARK_sw054_closeConstEcho m54 : 49|1@1+ (1,0) [0|1] "" Vector__XXX
 SG_ PARK_sw054_lowAttenTime m54 : 50|1@1+ (1,0) [0|1] "" Vector__XXX
 SG_ PARK_sw054_attenTimeJitter m54 : 51|1@1+ (1,0) [0|1] "" Vector__XXX
 SG_ PARK_sw054_reverbFreqJitter m54 : 52|1@1+ (1,0) [0|1] "" Vector__XXX
 SG_ PARK_sw056_sensorTemperature m56 : 16|16@1+ (0.1,-40) [-40|6513.5] "deg" Vector__XXX
 SG_ PARK_sw057_membraneDisconct m57 : 16|1@1+ (1,0) [0|1] "" Vector__XXX
 SG_ PARK_sw057_dampResistorFail m57 : 17|1@1+ (1,0) [0|1] "" Vector__XXX
 SG_ PARK_sw057_resonanceDrift m57 : 18|1@1+ (1,0) [0|1] "" Vector__XXX
 SG_ PARK_sw057_sensorCRC m57 : 19|1@1+ (1,0) [0|1] "" Vector__XXX
 SG_ PARK_sw057_recieveFailure m57 : 20|1@1+ (1,0) [0|1] "" Vector__XXX
 SG_ PARK_sw057_diagnosticTransferErr m57 : 21|1@1+ (1,0) [0|1] "" Vector__XXX
 SG_ PARK_sw058_linError m58 : 16|1@1+ (1,0) [0|1] "" Vector__XXX
 SG_ PARK_sw058_linBusError m58 : 17|1@1+ (1,0) [0|1] "" Vector__XXX
 SG_ PARK_sw058_linFrameCountError m58 : 18|1@1+ (1,0) [0|1] "" Vector__XXX
 SG_ PARK_sw059_reverbPeriod m59 : 16|16@1+ (1,0) [0|65535] "microseconds" Vector__XXX
 SG_ PARK_sw059_reverbTime m59 : 32|16@1+ (1,0) [0|65535] "microseconds" Vector__XXX
 SG_ PARK_sw059_highAttenTime m59 : 48|1@1+ (1,0) [0|1] "" Vector__XXX
 SG_ PARK_sw059_closeConstEcho m59 : 49|1@1+ (1,0) [0|1] "" Vector__XXX
 SG_ PARK_sw059_lowAttenTime m59 : 50|1@1+ (1,0) [0|1] "" Vector__XXX
 SG_ PARK_sw059_attenTimeJitter m59 : 51|1@1+ (1,0) [0|1] "" Vector__XXX
 SG_ PARK_sw059_reverbFreqJitter m59 : 52|1@1+ (1,0) [0|1] "" Vector__XXX
 SG_ PARK_sw061_voltage m61 : 16|16@1+ (0.1,0) [0|6553.5] "volts" Vector__XXX
 SG_ PARK_sw063_voltage m63 : 16|16@1+ (0.1,0) [0|6553.5] "volts" Vector__XXX
 SG_ PARK_sw064_faultCode m64 : 16|8@1+ (1,0) [0|255] "" Vector__XXX
 SG_ PARK_sw065_expectedCRC m65 : 16|16@1+ (1,0) [0|65535] "" Vector__XXX
 SG_ PARK_sw065_calculatedCRC m65 : 32|16@1+ (1,0) [0|65535] "" Vector__XXX
 SG_ PARK_sw066_placeHolder m66 : 16|1@1+ (1,0) [0|1] "" Vector__XXX
 SG_ PARK_sw068_placeHolder m68 : 16|1@1+ (1,0) [0|1] "" Vector__XXX
 SG_ PARK_sw069_messageID m69 : 16|16@1+ (1,0) [0|65535] "" Vector__XXX
 SG_ PARK_sw070_messageID m70 : 16|16@1+ (1,0) [0|65535] "" Vector__XXX
 SG_ PARK_sw071_messageID m71 : 16|16@1+ (1,0) [0|65535] "" Vector__XXX
 SG_ PARK_sw072_messageID m72 : 16|16@1+ (1,0) [0|65535] "" Vector__XXX
 SG_ PARK_sw073_messageID m73 : 16|16@1+ (1,0) [0|65535] "" Vector__XXX
 SG_ PARK_sw074_messageID m74 : 16|16@1+ (1,0) [0|65535] "" Vector__XXX
 SG_ PARK_sw075_messageID m75 : 16|16@1+ (1,0) [0|65535] "" Vector__XXX
 SG_ PARK_sw076_messageID m76 : 16|16@1+ (1,0) [0|65535] "" Vector__XXX
 SG_ PARK_sw077_errorExp m77 : 16|8@1+ (1,0) [0|255] "" Vector__XXX
 SG_ PARK_sw077_errorRx m77 : 24|8@1+ (1,0) [0|255] "" Vector__XXX
 SG_ PARK_sw077_messageID m77 : 32|12@1+ (1,0) [0|4095] "" Vector__XXX
 SG_ PARK_sw077_errorType m77 : 44|3@1+ (1,0) [0|7] "" Vector__XXX
 SG_ PARK_sw078_errorExp m78 : 16|8@1+ (1,0) [0|255] "" Vector__XXX
 SG_ PARK_sw078_errorRx m78 : 24|8@1+ (1,0) [0|255] "" Vector__XXX
 SG_ PARK_sw078_messageID m78 : 32|12@1+ (1,0) [0|4095] "" Vector__XXX
 SG_ PARK_sw078_errorType m78 : 44|3@1+ (1,0) [0|7] "" Vector__XXX
 SG_ PARK_sw079_errorExp m79 : 16|8@1+ (1,0) [0|255] "" Vector__XXX
 SG_ PARK_sw079_errorRx m79 : 24|8@1+ (1,0) [0|255] "" Vector__XXX
 SG_ PARK_sw079_messageID m79 : 32|12@1+ (1,0) [0|4095] "" Vector__XXX
 SG_ PARK_sw079_errorType m79 : 44|3@1+ (1,0) [0|7] "" Vector__XXX
 SG_ PARK_sw080_errorExp m80 : 16|8@1+ (1,0) [0|255] "" Vector__XXX
 SG_ PARK_sw080_errorRx m80 : 24|8@1+ (1,0) [0|255] "" Vector__XXX
 SG_ PARK_sw080_messageID m80 : 32|12@1+ (1,0) [0|4095] "" Vector__XXX
 SG_ PARK_sw080_errorType m80 : 44|3@1+ (1,0) [0|7] "" Vector__XXX
 SG_ PARK_sw081_errorExp m81 : 16|8@1+ (1,0) [0|255] "" Vector__XXX
 SG_ PARK_sw081_errorRx m81 : 24|8@1+ (1,0) [0|255] "" Vector__XXX
 SG_ PARK_sw081_messageID m81 : 32|12@1+ (1,0) [0|4095] "" Vector__XXX
 SG_ PARK_sw081_errorType m81 : 44|3@1+ (1,0) [0|7] "" Vector__XXX
 SG_ PARK_sw082_errorExp m82 : 16|8@1+ (1,0) [0|255] "" Vector__XXX
 SG_ PARK_sw082_errorRx m82 : 24|8@1+ (1,0) [0|255] "" Vector__XXX
 SG_ PARK_sw082_messageID m82 : 32|12@1+ (1,0) [0|4095] "" Vector__XXX
 SG_ PARK_sw082_errorType m82 : 44|3@1+ (1,0) [0|7] "" Vector__XXX
 SG_ PARK_sw083_errorExp m83 : 16|8@1+ (1,0) [0|255] "" Vector__XXX
 SG_ PARK_sw083_errorRx m83 : 24|8@1+ (1,0) [0|255] "" Vector__XXX
 SG_ PARK_sw083_messageID m83 : 32|12@1+ (1,0) [0|4095] "" Vector__XXX
 SG_ PARK_sw083_errorType m83 : 44|3@1+ (1,0) [0|7] "" Vector__XXX
 SG_ PARK_sw084_errorExp m84 : 16|8@1+ (1,0) [0|255] "" Vector__XXX
 SG_ PARK_sw084_errorRx m84 : 24|8@1+ (1,0) [0|255] "" Vector__XXX
 SG_ PARK_sw084_messageID m84 : 32|12@1+ (1,0) [0|4095] "" Vector__XXX
 SG_ PARK_sw084_errorType m84 : 44|3@1+ (1,0) [0|7] "" Vector__XXX
 SG_ PARK_sw086_writeRetryCounter m86 : 16|8@1+ (1,0) [0|255] "" Vector__XXX
 SG_ PARK_sw086_readRetryCounter m86 : 24|8@1+ (1,0) [0|255] "" Vector__XXX
 SG_ PARK_sw086_currentErrorCode m86 : 32|8@1+ (1,0) [0|255] "" Vector__XXX
 SG_ PARK_sw087_s1_sensorType m87 : 16|2@1+ (1,0) [0|2] "" Vector__XXX
 SG_ PARK_sw087_s2_sensorType m87 : 18|2@1+ (1,0) [0|2] "" Vector__XXX
 SG_ PARK_sw087_s3_sensorType m87 : 20|2@1+ (1,0) [0|2] "" Vector__XXX
 SG_ PARK_sw087_s4_sensorType m87 : 22|2@1+ (1,0) [0|2] "" Vector__XXX
 SG_ PARK_sw087_s5_sensorType m87 : 24|2@1+ (1,0) [0|2] "" Vector__XXX
 SG_ PARK_sw087_s6_sensorType m87 : 26|2@1+ (1,0) [0|2] "" Vector__XXX
 SG_ PARK_sw087_s7_sensorType m87 : 28|2@1+ (1,0) [0|2] "" Vector__XXX
 SG_ PARK_sw087_s8_sensorType m87 : 30|2@1+ (1,0) [0|2] "" Vector__XXX
 SG_ PARK_sw087_s9_sensorType m87 : 32|2@1+ (1,0) [0|2] "" Vector__XXX
 SG_ PARK_sw087_s10_sensorType m87 : 34|2@1+ (1,0) [0|2] "" Vector__XXX
 SG_ PARK_sw087_s11_sensorType m87 : 36|2@1+ (1,0) [0|2] "" Vector__XXX
 SG_ PARK_sw087_s12_sensorType m87 : 38|2@1+ (1,0) [0|2] "" Vector__XXX

BO_ 806 PARK_info: 8 PARK
 SG_ PARK_infoIndex M : 0|8@1+ (1,0) [0|255] "" Vector__XXX
 SG_ PARK_infoBuildType m10 : 8|8@1+ (1,0) [0|255] "" Vector__XXX
 SG_ PARK_infoComponentID m10 : 48|16@1+ (1,0) [0|65535] "" Vector__XXX
 SG_ PARK_infoPcbaID m11 : 16|8@1+ (1,0) [0|255] "" Vector__XXX
 SG_ PARK_infoAssemblyID m11 : 24|8@1+ (1,0) [0|255] "" Vector__XXX
 SG_ PARK_infoUsageID m11 : 32|16@1+ (1,0) [0|65535] "" Vector__XXX
 SG_ PARK_infoApplicationCRC m13 : 32|32@1+ (1,0) [0|4294967295] "" Vector__XXX
 SG_ PARK_infoBootUdsProtoVersion m20 : 8|8@1+ (1,0) [0|255] "" Vector__XXX
 SG_ PARK_infoBootloaderCRC m20 : 32|32@1+ (1,0) [0|4294967295] "" Vector__XXX

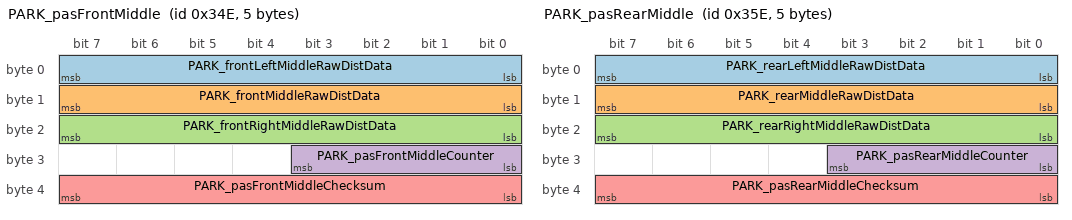
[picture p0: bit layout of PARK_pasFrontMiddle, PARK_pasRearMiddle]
BO_ 846 PARK_pasFrontMiddle: 5 PARK
 SG_ PARK_frontLeftMiddleRawDistData : 0|8@1+ (1,0) [0|254] "cm" Vector__XXX
 SG_ PARK_frontMiddleRawDistData : 8|8@1+ (1,0) [0|254] "cm" Vector__XXX
 SG_ PARK_frontRightMiddleRawDistData : 16|8@1+ (1,0) [0|254] "cm" Vector__XXX
 SG_ PARK_pasFrontMiddleCounter : 24|4@1+ (1,0) [0|15] "" Vector__XXX
 SG_ PARK_pasFrontMiddleChecksum : 32|8@1+ (1,0) [0|255] "" Vector__XXX

BO_ 862 PARK_pasRearMiddle: 5 PARK
 SG_ PARK_rearLeftMiddleRawDistData : 0|8@1+ (1,0) [0|254] "cm" Vector__XXX
 SG_ PARK_rearMiddleRawDistData : 8|8@1+ (1,0) [0|254] "cm" Vector__XXX
 SG_ PARK_rearRightMiddleRawDistData : 16|8@1+ (1,0) [0|254] "cm" Vector__XXX
 SG_ PARK_pasRearMiddleCounter : 24|4@1+ (1,0) [0|15] "" Vector__XXX
 SG_ PARK_pasRearMiddleChecksum : 32|8@1+ (1,0) [0|255] "" Vector__XXX

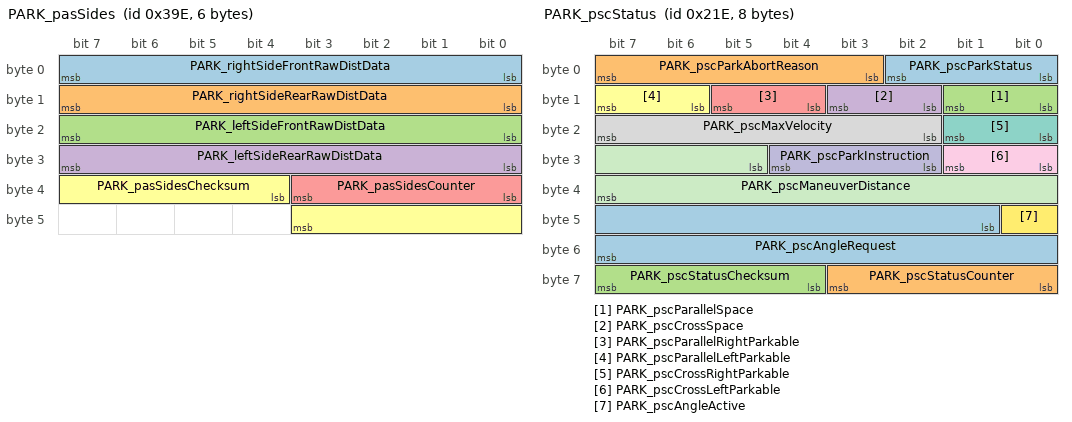
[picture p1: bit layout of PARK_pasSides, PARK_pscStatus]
BO_ 926 PARK_pasSides: 6 PARK
 SG_ PARK_rightSideFrontRawDistData : 0|8@1+ (1,0) [0|254] "cm" Vector__XXX
 SG_ PARK_rightSideRearRawDistData : 8|8@1+ (1,0) [0|254] "cm" Vector__XXX
 SG_ PARK_leftSideFrontRawDistData : 16|8@1+ (1,0) [0|254] "cm" Vector__XXX
 SG_ PARK_leftSideRearRawDistData : 24|8@1+ (1,0) [0|254] "cm" Vector__XXX
 SG_ PARK_pasSidesCounter : 32|4@1+ (1,0) [0|15] "" Vector__XXX
 SG_ PARK_pasSidesChecksum : 36|8@1+ (1,0) [0|255] "" Vector__XXX

BO_ 606 PARK_pscEnvSlot: 8 PARK
 SG_ PARK_pscEnvSlotType M : 0|2@1+ (1,0) [0|3] "" Vector__XXX
 SG_ PARK_pscLeftParallelObj1X m0 : 3|11@1+ (2,-2048) [-2048|2044] "cm" Vector__XXX
 SG_ PARK_pscLeftParallelObj1Y m0 : 14|11@1+ (2,-2048) [-2048|2044] "cm" Vector__XXX
 SG_ PARK_pscLeftParallelObj1Alpha m0 : 25|7@1+ (2,-128) [-128|124] "deg" Vector__XXX
 SG_ PARK_pscLeftParallelObj2Y m0 : 35|11@1+ (2,-2048) [-2048|2044] "cm" Vector__XXX
 SG_ PARK_pscLeftParallelObj2X m0 : 46|11@1+ (2,-2048) [-2048|2044] "cm" Vector__XXX
 SG_ PARK_pscLeftParallelObj2Alpha m0 : 57|7@1+ (2,-128) [-128|124] "deg" Vector__XXX
 SG_ PARK_pscLeftCrossObj1X m1 : 3|11@1+ (2,-2048) [-2048|2044] "cm" Vector__XXX
 SG_ PARK_pscLeftCrossObj1Y m1 : 14|11@1+ (2,-2048) [-2048|2044] "cm" Vector__XXX
 SG_ PARK_pscLeftCrossObj1Alpha m1 : 25|7@1+ (2,-128) [-128|124] "deg" Vector__XXX
 SG_ PARK_pscLeftCrossObj2Y m1 : 35|11@1+ (2,-2048) [-2048|2044] "cm" Vector__XXX
 SG_ PARK_pscLeftCrossObj2X m1 : 46|11@1+ (2,-2048) [-2048|2044] "cm" Vector__XXX
 SG_ PARK_pscLeftCrossObj2Alpha m1 : 57|7@1+ (2,-128) [-128|124] "deg" Vector__XXX
 SG_ PARK_pscRightParallelObj1X m2 : 3|11@1+ (2,-2048) [-2048|2044] "cm" Vector__XXX
 SG_ PARK_pscRightParallelObj1Y m2 : 14|11@1+ (2,-2048) [-2048|2044] "cm" Vector__XXX
 SG_ PARK_pscRightParallelObj1Alpha m2 : 25|7@1+ (2,-128) [-128|124] "deg" Vector__XXX
 SG_ PARK_pscRightParallelObj2Y m2 : 35|11@1+ (2,-2048) [-2048|2044] "cm" Vector__XXX
 SG_ PARK_pscRightParallelObj2X m2 : 46|11@1+ (2,-2048) [-2048|2044] "cm" Vector__XXX
 SG_ PARK_pscRightParallelObj2Alpha m2 : 57|7@1+ (2,-128) [-128|124] "deg" Vector__XXX
 SG_ PARK_pscRightCrossObj1X m3 : 3|11@1+ (2,-2048) [-2048|2044] "cm" Vector__XXX
 SG_ PARK_pscRightCrossObj1Y m3 : 14|11@1+ (2,-2048) [-2048|2044] "cm" Vector__XXX
 SG_ PARK_pscRightCrossObj1Alpha m3 : 25|7@1+ (2,-128) [-128|124] "deg" Vector__XXX
 SG_ PARK_pscRightCrossObj2Y m3 : 35|11@1+ (2,-2048) [-2048|2044] "cm" Vector__XXX
 SG_ PARK_pscRightCrossObj2X m3 : 46|11@1+ (2,-2048) [-2048|2044] "cm" Vector__XXX
 SG_ PARK_pscRightCrossObj2Alpha m3 : 57|7@1+ (2,-128) [-128|124] "deg" Vector__XXX

BO_ 542 PARK_pscStatus: 8 PARK
 SG_ PARK_pscParkStatus : 0|3@1+ (1,0) [0|6] "" Vector__XXX
 SG_ PARK_pscParkAbortReason : 3|5@1+ (1,0) [0|30] "" Vector__XXX
 SG_ PARK_pscParallelSpace : 8|2@1+ (1,0) [0|3] "" Vector__XXX
 SG_ PARK_pscCrossSpace : 10|2@1+ (1,0) [0|3] "" Vector__XXX
 SG_ PARK_pscParallelRightParkable : 12|2@1+ (1,0) [0|2] "" Vector__XXX
 SG_ PARK_pscParallelLeftParkable : 14|2@1+ (1,0) [0|2] "" Vector__XXX
 SG_ PARK_pscCrossRightParkable : 16|2@1+ (1,0) [0|2] "" Vector__XXX
 SG_ PARK_pscMaxVelocity : 18|6@1+ (0.1,0) [0|6.2] "kph" Vector__XXX
 SG_ PARK_pscCrossLeftParkable : 24|2@1+ (1,0) [0|2] "" Vector__XXX
 SG_ PARK_pscParkInstruction : 26|3@1+ (1,0) [0|6] "" Vector__XXX
 SG_ PARK_pscManeuverDistance : 29|11@1+ (1,0) [0|2046] "cm" Vector__XXX
 SG_ PARK_pscAngleActive : 40|1@1+ (1,0) [0|1] "" Vector__XXX
 SG_ PARK_pscAngleRequest : 41|15@1+ (0.1,-1638.4) [-1638.4|1638.3] "deg" Vector__XXX
 SG_ PARK_pscStatusCounter : 56|4@1+ (1,0) [0|15] "" Vector__XXX
 SG_ PARK_pscStatusChecksum : 60|4@1+ (1,0) [0|15] "" Vector__XXX

BO_ 590 PARK_pscVehSlot: 8 PARK
 SG_ PARK_pscVehSlotType M : 0|2@1+ (1,0) [0|3] "" Vector__XXX
 SG_ PARK_pscLeftParallelVehX m0 : 5|11@1+ (2,-2048) [-2048|2044] "cm" Vector__XXX
 SG_ PARK_pscLeftParallelVehY m0 : 16|11@1+ (2,-2048) [-2048|2044] "cm" Vector__XXX
 SG_ PARK_pscLeftParallelPsi m0 : 32|13@1+ (0.0009765625,0) [0|7.998046875] "radians" Vector__XXX
 SG_ PARK_pscLeftParallelSizeX m0 : 48|8@1+ (4,0) [0|1016] "cm" Vector__XXX
 SG_ PARK_pscLeftParallelSizeY m0 : 56|8@1+ (4,0) [0|1016] "cm" Vector__XXX
 SG_ PARK_pscLeftCrossVehX m1 : 5|11@1+ (2,-2048) [-2048|2044] "cm" Vector__XXX
 SG_ PARK_pscLeftCrossVehY m1 : 16|11@1+ (2,-2048) [-2048|2044] "cm" Vector__XXX
 SG_ PARK_pscLeftCrossPsi m1 : 32|13@1+ (0.0009765625,0) [0|7.998046875] "radians" Vector__XXX
 SG_ PARK_pscLeftCrossSizeX m1 : 48|8@1+ (4,0) [0|1016] "cm" Vector__XXX
 SG_ PARK_pscLeftCrossSizeY m1 : 56|8@1+ (4,0) [0|1016] "cm" Vector__XXX
 SG_ PARK_pscRightParallelVehX m2 : 5|11@1+ (2,-2048) [-2048|2044] "cm" Vector__XXX
 SG_ PARK_pscRightParallelVehY m2 : 16|11@1+ (2,-2048) [-2048|2044] "cm" Vector__XXX
 SG_ PARK_pscRightParallelPsi m2 : 32|13@1+ (0.0009765625,0) [0|7.998046875] "radians" Vector__XXX
 SG_ PARK_pscRightParallelSizeX m2 : 48|8@1+ (4,0) [0|1016] "cm" Vector__XXX
 SG_ PARK_pscRightParallelSizeY m2 : 56|8@1+ (4,0) [0|1016] "cm" Vector__XXX
 SG_ PARK_pscRightCrossVehX m3 : 5|11@1+ (2,-2048) [-2048|2044] "cm" Vector__XXX
 SG_ PARK_pscRightCrossVehY m3 : 16|11@1+ (2,-2048) [-2048|2044] "cm" Vector__XXX
 SG_ PARK_pscRightCrossPsi m3 : 32|13@1+ (0.0009765625,0) [0|7.998046875] "radians" Vector__XXX
 SG_ PARK_pscRightCrossSizeX m3 : 48|8@1+ (4,0) [0|1016] "cm" Vector__XXX
 SG_ PARK_pscRightCrossSizeY m3 : 56|8@1+ (4,0) [0|1016] "cm" Vector__XXX

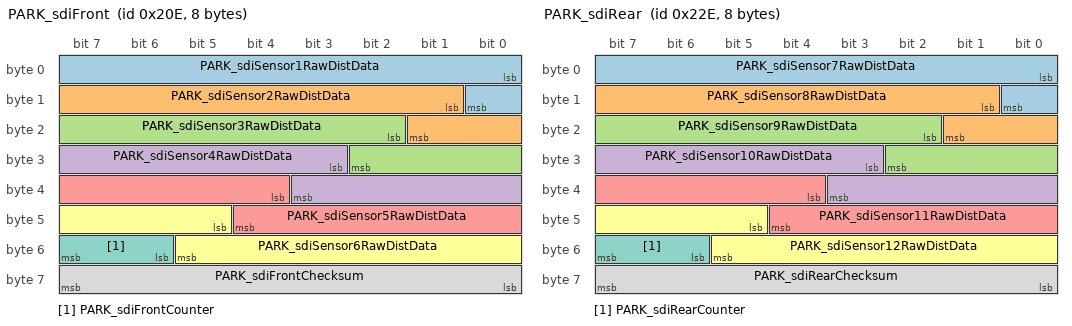
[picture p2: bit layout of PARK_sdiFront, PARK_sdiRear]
BO_ 526 PARK_sdiFront: 8 PARK
 SG_ PARK_sdiSensor1RawDistData : 0|9@1+ (1,0) [0|510] "cm" Vector__XXX
 SG_ PARK_sdiSensor2RawDistData : 9|9@1+ (1,0) [0|510] "cm" Vector__XXX
 SG_ PARK_sdiSensor3RawDistData : 18|9@1+ (1,0) [0|510] "cm" Vector__XXX
 SG_ PARK_sdiSensor4RawDistData : 27|9@1+ (1,0) [0|510] "cm" Vector__XXX
 SG_ PARK_sdiSensor5RawDistData : 36|9@1+ (1,0) [0|510] "cm" Vector__XXX
 SG_ PARK_sdiSensor6RawDistData : 45|9@1+ (1,0) [0|510] "cm" Vector__XXX
 SG_ PARK_sdiFrontCounter : 54|2@1+ (1,0) [0|3] "" Vector__XXX
 SG_ PARK_sdiFrontChecksum : 56|8@1+ (1,0) [0|255] "" Vector__XXX

BO_ 558 PARK_sdiRear: 8 PARK
 SG_ PARK_sdiSensor7RawDistData : 0|9@1+ (1,0) [0|510] "cm" Vector__XXX
 SG_ PARK_sdiSensor8RawDistData : 9|9@1+ (1,0) [0|510] "cm" Vector__XXX
 SG_ PARK_sdiSensor9RawDistData : 18|9@1+ (1,0) [0|510] "cm" Vector__XXX
 SG_ PARK_sdiSensor10RawDistData : 27|9@1+ (1,0) [0|510] "cm" Vector__XXX
 SG_ PARK_sdiSensor11RawDistData : 36|9@1+ (1,0) [0|510] "cm" Vector__XXX
 SG_ PARK_sdiSensor12RawDistData : 45|9@1+ (1,0) [0|510] "cm" Vector__XXX
 SG_ PARK_sdiRearCounter : 54|2@1+ (1,0) [0|3] "" Vector__XXX
 SG_ PARK_sdiRearChecksum : 56|8@1+ (1,0) [0|255] "" Vector__XXX

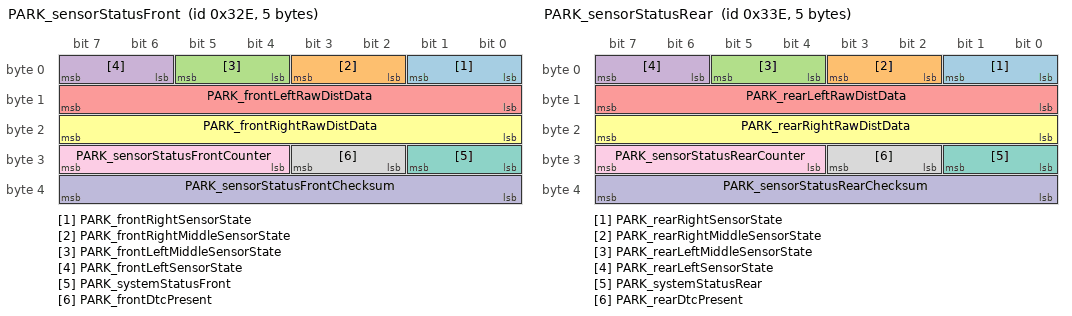
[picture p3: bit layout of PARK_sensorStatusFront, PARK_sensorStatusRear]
BO_ 814 PARK_sensorStatusFront: 5 PARK
 SG_ PARK_frontRightSensorState : 0|2@1+ (1,0) [0|2] "" Vector__XXX
 SG_ PARK_frontRightMiddleSensorState : 2|2@1+ (1,0) [0|2] "" Vector__XXX
 SG_ PARK_frontLeftMiddleSensorState : 4|2@1+ (1,0) [0|2] "" Vector__XXX
 SG_ PARK_frontLeftSensorState : 6|2@1+ (1,0) [0|2] "" Vector__XXX
 SG_ PARK_frontLeftRawDistData : 8|8@1+ (1,0) [0|254] "cm" Vector__XXX
 SG_ PARK_frontRightRawDistData : 16|8@1+ (1,0) [0|254] "cm" Vector__XXX
 SG_ PARK_systemStatusFront : 24|2@1+ (1,0) [0|2] "" Vector__XXX
 SG_ PARK_frontDtcPresent : 26|2@1+ (1,0) [0|2] "" Vector__XXX
 SG_ PARK_sensorStatusFrontCounter : 28|4@1+ (1,0) [0|15] "" Vector__XXX
 SG_ PARK_sensorStatusFrontChecksum : 32|8@1+ (1,0) [0|255] "" Vector__XXX

BO_ 830 PARK_sensorStatusRear: 5 PARK
 SG_ PARK_rearRightSensorState : 0|2@1+ (1,0) [0|2] "" Vector__XXX
 SG_ PARK_rearRightMiddleSensorState : 2|2@1+ (1,0) [0|2] "" Vector__XXX
 SG_ PARK_rearLeftMiddleSensorState : 4|2@1+ (1,0) [0|2] "" Vector__XXX
 SG_ PARK_rearLeftSensorState : 6|2@1+ (1,0) [0|2] "" Vector__XXX
 SG_ PARK_rearLeftRawDistData : 8|8@1+ (1,0) [0|254] "cm" Vector__XXX
 SG_ PARK_rearRightRawDistData : 16|8@1+ (1,0) [0|254] "cm" Vector__XXX
 SG_ PARK_systemStatusRear : 24|2@1+ (1,0) [0|2] "" Vector__XXX
 SG_ PARK_rearDtcPresent : 26|2@1+ (1,0) [0|2] "" Vector__XXX
 SG_ PARK_sensorStatusRearCounter : 28|4@1+ (1,0) [0|15] "" Vector__XXX
 SG_ PARK_sensorStatusRearChecksum : 32|8@1+ (1,0) [0|255] "" Vector__XXX

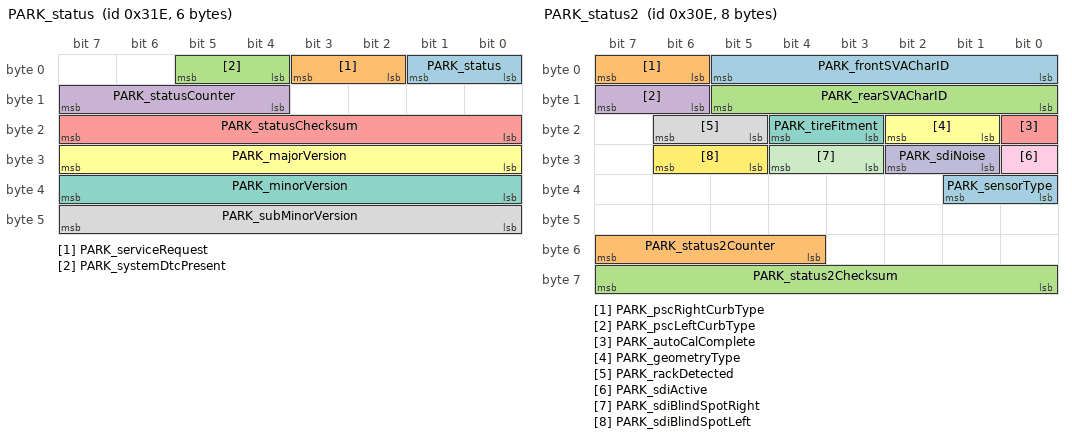
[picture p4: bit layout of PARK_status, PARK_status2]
BO_ 798 PARK_status: 6 PARK
 SG_ PARK_status : 0|2@1+ (1,0) [0|2] "" Vector__XXX
 SG_ PARK_serviceRequest : 2|2@1+ (1,0) [0|2] "" Vector__XXX
 SG_ PARK_systemDtcPresent : 4|2@1+ (1,0) [0|2] "" Vector__XXX
 SG_ PARK_statusCounter : 12|4@1+ (1,0) [0|15] "" Vector__XXX
 SG_ PARK_statusChecksum : 16|8@1+ (1,0) [0|255] "" Vector__XXX
 SG_ PARK_majorVersion : 24|8@1+ (1,0) [0|254] "" Vector__XXX
 SG_ PARK_minorVersion : 32|8@1+ (1,0) [0|254] "" Vector__XXX
 SG_ PARK_subMinorVersion : 40|8@1+ (1,0) [0|254] "" Vector__XXX

BO_ 782 PARK_status2: 8 PARK
 SG_ PARK_frontSVACharID : 0|6@1+ (1,0) [0|63] "" Vector__XXX
 SG_ PARK_pscRightCurbType : 6|2@1+ (1,0) [0|3] "" Vector__XXX
 SG_ PARK_rearSVACharID : 8|6@1+ (1,0) [0|63] "" Vector__XXX
 SG_ PARK_pscLeftCurbType : 14|2@1+ (1,0) [0|3] "" Vector__XXX
 SG_ PARK_autoCalComplete : 16|1@1+ (1,0) [0|1] "" Vector__XXX
 SG_ PARK_geometryType : 17|2@1+ (1,0) [0|3] "" Vector__XXX
 SG_ PARK_tireFitment : 19|2@1+ (1,0) [0|2] "" Vector__XXX
 SG_ PARK_rackDetected : 21|2@1+ (1,0) [0|2] "" Vector__XXX
 SG_ PARK_sdiActive : 24|1@1+ (1,0) [0|1] "" Vector__XXX
 SG_ PARK_sdiNoise : 25|2@1+ (1,0) [0|2] "" Vector__XXX
 SG_ PARK_sdiBlindSpotRight : 27|2@1+ (1,0) [0|2] "" Vector__XXX
 SG_ PARK_sdiBlindSpotLeft : 29|2@1+ (1,0) [0|2] "" Vector__XXX
 SG_ PARK_sensorType : 32|2@1+ (1,0) [0|2] "" Vector__XXX
 SG_ PARK_status2Counter : 52|4@1+ (1,0) [0|15] "" Vector__XXX
 SG_ PARK_status2Checksum : 56|8@1+ (1,0) [0|255] "" Vector__XXX

BO_ 1630 PARK_udsResponse: 8 PARK
 SG_ PARK_udsResponseData : 0|64@1+ (1,0) [0|1.84467440737e+19] "" Vector__XXX

BO_ 894 PARK_warningMatrix: 8 PARK
 SG_ PARK_matrixIndex M : 0|4@1+ (1,0) [0|15] "" Vector__XXX
 SG_ PARK_a001_s1_overTemp m0 : 4|1@1+ (1,0) [0|1] "" Vector__XXX
 SG_ PARK_a002_s1_internalFail m0 : 5|1@1+ (1,0) [0|1] "" Vector__XXX
 SG_ PARK_a003_s1_linCommError m0 : 6|1@1+ (1,0) [0|1] "" Vector__XXX
 SG_ PARK_a004_s1_blocked m0 : 7|1@1+ (1,0) [0|1] "" Vector__XXX
 SG_ PARK_a005_s1_crossTalk m0 : 8|1@1+ (1,0) [0|1] "" Vector__XXX
 SG_ PARK_a006_s2_overTemp m0 : 9|1@1+ (1,0) [0|1] "" Vector__XXX
 SG_ PARK_a007_s2_internalFail m0 : 10|1@1+ (1,0) [0|1] "" Vector__XXX
 SG_ PARK_a008_s2_linCommError m0 : 11|1@1+ (1,0) [0|1] "" Vector__XXX
 SG_ PARK_a009_s2_blocked m0 : 12|1@1+ (1,0) [0|1] "" Vector__XXX
 SG_ PARK_a010_s2_crossTalk m0 : 13|1@1+ (1,0) [0|1] "" Vector__XXX
 SG_ PARK_a011_s3_overTemp m0 : 14|1@1+ (1,0) [0|1] "" Vector__XXX
 SG_ PARK_a012_s3_internalFail m0 : 15|1@1+ (1,0) [0|1] "" Vector__XXX
 SG_ PARK_a013_s3_linCommError m0 : 16|1@1+ (1,0) [0|1] "" Vector__XXX
 SG_ PARK_a014_s3_blocked m0 : 17|1@1+ (1,0) [0|1] "" Vector__XXX
 SG_ PARK_a015_s3_crossTalk m0 : 18|1@1+ (1,0) [0|1] "" Vector__XXX
 SG_ PARK_a016_s4_overTemp m0 : 19|1@1+ (1,0) [0|1] "" Vector__XXX
 SG_ PARK_a017_s4_internalFail m0 : 20|1@1+ (1,0) [0|1] "" Vector__XXX
 SG_ PARK_a018_s4_linCommError m0 : 21|1@1+ (1,0) [0|1] "" Vector__XXX
 SG_ PARK_a019_s4_blocked m0 : 22|1@1+ (1,0) [0|1] "" Vector__XXX
 SG_ PARK_a020_s4_crossTalk m0 : 23|1@1+ (1,0) [0|1] "" Vector__XXX
 SG_ PARK_a021_s5_overTemp m0 : 24|1@1+ (1,0) [0|1] "" Vector__XXX
 SG_ PARK_a022_s5_internalFail m0 : 25|1@1+ (1,0) [0|1] "" Vector__XXX
 SG_ PARK_a023_s5_linCommError m0 : 26|1@1+ (1,0) [0|1] "" Vector__XXX
 SG_ PARK_a024_s5_blocked m0 : 27|1@1+ (1,0) [0|1] "" Vector__XXX
 SG_ PARK_a025_s5_crossTalk m0 : 28|1@1+ (1,0) [0|1] "" Vector__XXX
 SG_ PARK_a026_s6_overTemp m0 : 29|1@1+ (1,0) [0|1] "" Vector__XXX
 SG_ PARK_a027_s6_internalFail m0 : 30|1@1+ (1,0) [0|1] "" Vector__XXX
 SG_ PARK_a028_s6_linCommError m0 : 31|1@1+ (1,0) [0|1] "" Vector__XXX
 SG_ PARK_a029_s6_blocked m0 : 32|1@1+ (1,0) [0|1] "" Vector__XXX
 SG_ PARK_a030_s6_crossTalk m0 : 33|1@1+ (1,0) [0|1] "" Vector__XXX
 SG_ PARK_a031_s7_overTemp m0 : 34|1@1+ (1,0) [0|1] "" Vector__XXX
 SG_ PARK_a032_s7_internalFail m0 : 35|1@1+ (1,0) [0|1] "" Vector__XXX
 SG_ PARK_a033_s7_linCommError m0 : 36|1@1+ (1,0) [0|1] "" Vector__XXX
 SG_ PARK_a034_s7_blocked m0 : 37|1@1+ (1,0) [0|1] "" Vector__XXX
 SG_ PARK_a035_s7_crossTalk m0 : 38|1@1+ (1,0) [0|1] "" Vector__XXX
 SG_ PARK_a036_s8_overTemp m0 : 39|1@1+ (1,0) [0|1] "" Vector__XXX
 SG_ PARK_a037_s8_internalFail m0 : 40|1@1+ (1,0) [0|1] "" Vector__XXX
 SG_ PARK_a038_s8_linCommError m0 : 41|1@1+ (1,0) [0|1] "" Vector__XXX
 SG_ PARK_a039_s8_blocked m0 : 42|1@1+ (1,0) [0|1] "" Vector__XXX
 SG_ PARK_a040_s8_crossTalk m0 : 43|1@1+ (1,0) [0|1] "" Vector__XXX
 SG_ PARK_a041_s9_overTemp m0 : 44|1@1+ (1,0) [0|1] "" Vector__XXX
 SG_ PARK_a042_s9_internalFail m0 : 45|1@1+ (1,0) [0|1] "" Vector__XXX
 SG_ PARK_a043_s9_linCommError m0 : 46|1@1+ (1,0) [0|1] "" Vector__XXX
 SG_ PARK_a044_s9_blocked m0 : 47|1@1+ (1,0) [0|1] "" Vector__XXX
 SG_ PARK_a045_s9_crossTalk m0 : 48|1@1+ (1,0) [0|1] "" Vector__XXX
 SG_ PARK_a046_s10_overTemp m0 : 49|1@1+ (1,0) [0|1] "" Vector__XXX
 SG_ PARK_a047_s10_internalFail m0 : 50|1@1+ (1,0) [0|1] "" Vector__XXX
 SG_ PARK_a048_s10_linCommError m0 : 51|1@1+ (1,0) [0|1] "" Vector__XXX
 SG_ PARK_a049_s10_blocked m0 : 52|1@1+ (1,0) [0|1] "" Vector__XXX
 SG_ PARK_a050_s10_crossTalk m0 : 53|1@1+ (1,0) [0|1] "" Vector__XXX
 SG_ PARK_a051_s11_overTemp m0 : 54|1@1+ (1,0) [0|1] "" Vector__XXX
 SG_ PARK_a052_s11_internalFail m0 : 55|1@1+ (1,0) [0|1] "" Vector__XXX
 SG_ PARK_a053_s11_linCommError m0 : 56|1@1+ (1,0) [0|1] "" Vector__XXX
 SG_ PARK_a054_s11_blocked m0 : 57|1@1+ (1,0) [0|1] "" Vector__XXX
 SG_ PARK_a055_s11_crossTalk m0 : 58|1@1+ (1,0) [0|1] "" Vector__XXX
 SG_ PARK_a056_s12_overTemp m0 : 59|1@1+ (1,0) [0|1] "" Vector__XXX
 SG_ PARK_a057_s12_internalFail m0 : 60|1@1+ (1,0) [0|1] "" Vector__XXX
 SG_ PARK_a058_s12_linCommError m0 : 61|1@1+ (1,0) [0|1] "" Vector__XXX
 SG_ PARK_a059_s12_blocked m0 : 62|1@1+ (1,0) [0|1] "" Vector__XXX
 SG_ PARK_a060_s12_crossTalk m0 : 63|1@1+ (1,0) [0|1] "" Vector__XXX
 SG_ PARK_a061_ecuUnderVoltage m1 : 4|1@1+ (1,0) [0|1] "" Vector__XXX
 SG_ PARK_a062_ecuOverVoltage m1 : 5|1@1+ (1,0) [0|1] "" Vector__XXX
 SG_ PARK_a063_sensorVoltage m1 : 6|1@1+ (1,0) [0|1] "" Vector__XXX
 SG_ PARK_a064_ecuFault m1 : 7|1@1+ (1,0) [0|1] "" Vector__XXX
 SG_ PARK_a065_crcFault m1 : 8|1@1+ (1,0) [0|1] "" Vector__XXX
 SG_ PARK_a066_calibrationMissing m1 : 9|1@1+ (1,0) [0|1] "" Vector__XXX
 SG_ PARK_a067_privateCANBusOff m1 : 10|1@1+ (1,0) [0|1] "" Vector__XXX
 SG_ PARK_a068_hardwareWatchDog m1 : 11|1@1+ (1,0) [0|1] "" Vector__XXX
 SG_ PARK_a069_dasMia m1 : 12|1@1+ (1,0) [0|1] "" Vector__XXX
 SG_ PARK_a070_sccmMia m1 : 13|1@1+ (1,0) [0|1] "" Vector__XXX
 SG_ PARK_a071_diMia m1 : 14|1@1+ (1,0) [0|1] "" Vector__XXX
 SG_ PARK_a072_epasMia m1 : 15|1@1+ (1,0) [0|1] "" Vector__XXX
 SG_ PARK_a073_epbMia m1 : 16|1@1+ (1,0) [0|1] "" Vector__XXX
 SG_ PARK_a074_espMia m1 : 17|1@1+ (1,0) [0|1] "" Vector__XXX
 SG_ PARK_a075_rcmMia m1 : 18|1@1+ (1,0) [0|1] "" Vector__XXX
 SG_ PARK_a076_vcFrontMia m1 : 19|1@1+ (1,0) [0|1] "" Vector__XXX
 SG_ PARK_a077_dasError m1 : 20|1@1+ (1,0) [0|1] "" Vector__XXX
 SG_ PARK_a078_diError m1 : 21|1@1+ (1,0) [0|1] "" Vector__XXX
 SG_ PARK_a079_epasError m1 : 22|1@1+ (1,0) [0|1] "" Vector__XXX
 SG_ PARK_a080_epbError m1 : 23|1@1+ (1,0) [0|1] "" Vector__XXX
 SG_ PARK_a081_espError m1 : 24|1@1+ (1,0) [0|1] "" Vector__XXX
 SG_ PARK_a082_rcmError m1 : 25|1@1+ (1,0) [0|1] "" Vector__XXX
 SG_ PARK_a083_vcFrontError m1 : 26|1@1+ (1,0) [0|1] "" Vector__XXX
 SG_ PARK_a084_sccmError m1 : 27|1@1+ (1,0) [0|1] "" Vector__XXX
 SG_ PARK_a085_watchdogReset m1 : 28|1@1+ (1,0) [0|1] "" Vector__XXX
 SG_ PARK_a086_nvmFault m1 : 29|1@1+ (1,0) [0|1] "" Vector__XXX
 SG_ PARK_a087_sensorMismatchError m1 : 30|1@1+ (1,0) [0|1] "" Vector__XXX

BO_TX_BU_ 1470 : IDB;
BO_TX_BU_ 983 : IDB;
BO_TX_BU_ 828 : IDB;
BO_TX_BU_ 1486 : PARK;
BO_TX_BU_ 806 : PARK;
BO_TX_BU_ 846 : PARK;
BO_TX_BU_ 862 : PARK;
BO_TX_BU_ 926 : PARK;
BO_TX_BU_ 606 : PARK;
BO_TX_BU_ 542 : PARK;
BO_TX_BU_ 590 : PARK;
BO_TX_BU_ 526 : PARK;
BO_TX_BU_ 558 : PARK;
BO_TX_BU_ 814 : PARK;
BO_TX_BU_ 830 : PARK;
BO_TX_BU_ 798 : PARK;
BO_TX_BU_ 782 : PARK;
BO_TX_BU_ 1630 : PARK;
BO_TX_BU_ 894 : PARK;
CM_ BO_ 1470 "IDB ECU message: alert log; frame length from the layout, not yet observed on a vehicle bus";
CM_ SG_ 1470 IDB_alertID "IDB ECU: alert ID";
CM_ SG_ 1470 IDB_alertState "IDB ECU: alert state";
CM_ SG_ 1470 IDB_a014_wheelSpeedSensorFreq "IDB ECU: a014 wheel speed sensor freq";
CM_ SG_ 1470 IDB_a014_wheelSpeedSensorPhase "IDB ECU: a014 wheel speed sensor phase";
CM_ SG_ 1470 IDB_a014_wheelSpeedSensorMisinst "IDB ECU: a014 wheel speed sensor misinstallation";
CM_ SG_ 1470 IDB_a014_wheelSpeedSensorWrongEx "IDB ECU: a014 wheel speed sensor wrong exciter";
CM_ SG_ 1470 IDB_a014_wheelSpeedSensorSpeedJu "IDB ECU: a014 wheel speed sensor speed jump minus";
CM_ SG_ 1470 IDB_a014_wheelSpeedSensorSp_0001 "IDB ECU: a014 wheel speed sensor speed jump plus";
CM_ SG_ 1470 IDB_a014_wheelSpeedSensorAirGap "IDB ECU: a014 wheel speed sensor air gap";
CM_ SG_ 1470 IDB_a014_wheelSpeedSensorBIST "IDB ECU: a014 wheel speed sensor BIST";
CM_ SG_ 1470 IDB_a014_wheelSpeedSensorLeakage "IDB ECU: a014 wheel speed sensor leakage cur";
CM_ SG_ 1470 IDB_a014_wheelSpeedSensorOverTem "IDB ECU: a014 wheel speed sensor over temp";
CM_ SG_ 1470 IDB_a014_wheelSpeedSensorSh_0001 "IDB ECU: a014 wheel speed sensor short to gnd";
CM_ SG_ 1470 IDB_a014_wheelSpeedSensorShortTo "IDB ECU: a014 wheel speed sensor short to bat";
CM_ SG_ 1470 IDB_a014_wheelSpeedSensorOpen "IDB ECU: a014 wheel speed sensor open";
CM_ SG_ 1470 IDB_a015_wheelSpeedSensorFreq "IDB ECU: a015 wheel speed sensor freq";
CM_ SG_ 1470 IDB_a015_wheelSpeedSensorPhase "IDB ECU: a015 wheel speed sensor phase";
CM_ SG_ 1470 IDB_a015_wheelSpeedSensorMisinst "IDB ECU: a015 wheel speed sensor misinstallation";
CM_ SG_ 1470 IDB_a015_wheelSpeedSensorWrongEx "IDB ECU: a015 wheel speed sensor wrong exciter";
CM_ SG_ 1470 IDB_a015_wheelSpeedSensorSpeedJu "IDB ECU: a015 wheel speed sensor speed jump minus";
CM_ SG_ 1470 IDB_a015_wheelSpeedSensorSp_0001 "IDB ECU: a015 wheel speed sensor speed jump plus";
CM_ SG_ 1470 IDB_a015_wheelSpeedSensorAirGap "IDB ECU: a015 wheel speed sensor air gap";
CM_ SG_ 1470 IDB_a015_wheelSpeedSensorBIST "IDB ECU: a015 wheel speed sensor BIST";
CM_ SG_ 1470 IDB_a015_wheelSpeedSensorLeakage "IDB ECU: a015 wheel speed sensor leakage cur";
CM_ SG_ 1470 IDB_a015_wheelSpeedSensorOverTem "IDB ECU: a015 wheel speed sensor over temp";
CM_ SG_ 1470 IDB_a015_wheelSpeedSensorSh_0001 "IDB ECU: a015 wheel speed sensor short to gnd";
CM_ SG_ 1470 IDB_a015_wheelSpeedSensorShortTo "IDB ECU: a015 wheel speed sensor short to bat";
CM_ SG_ 1470 IDB_a015_wheelSpeedSensorOpen "IDB ECU: a015 wheel speed sensor open";
CM_ SG_ 1470 IDB_a016_wheelSpeedSensorFreq "IDB ECU: a016 wheel speed sensor freq";
CM_ SG_ 1470 IDB_a016_wheelSpeedSensorPhase "IDB ECU: a016 wheel speed sensor phase";
CM_ SG_ 1470 IDB_a016_wheelSpeedSensorMisinst "IDB ECU: a016 wheel speed sensor misinstallation";
CM_ SG_ 1470 IDB_a016_wheelSpeedSensorWrongEx "IDB ECU: a016 wheel speed sensor wrong exciter";
CM_ SG_ 1470 IDB_a016_wheelSpeedSensorSpeedJu "IDB ECU: a016 wheel speed sensor speed jump minus";
CM_ SG_ 1470 IDB_a016_wheelSpeedSensorSp_0001 "IDB ECU: a016 wheel speed sensor speed jump plus";
CM_ SG_ 1470 IDB_a016_wheelSpeedSensorAirGap "IDB ECU: a016 wheel speed sensor air gap";
CM_ SG_ 1470 IDB_a016_wheelSpeedSensorBIST "IDB ECU: a016 wheel speed sensor BIST";
CM_ SG_ 1470 IDB_a016_wheelSpeedSensorLeakage "IDB ECU: a016 wheel speed sensor leakage cur";
CM_ SG_ 1470 IDB_a016_wheelSpeedSensorOverTem "IDB ECU: a016 wheel speed sensor over temp";
CM_ SG_ 1470 IDB_a016_wheelSpeedSensorSh_0001 "IDB ECU: a016 wheel speed sensor short to gnd";
CM_ SG_ 1470 IDB_a016_wheelSpeedSensorShortTo "IDB ECU: a016 wheel speed sensor short to bat";
CM_ SG_ 1470 IDB_a016_wheelSpeedSensorOpen "IDB ECU: a016 wheel speed sensor open";
CM_ SG_ 1470 IDB_a017_wheelSpeedSensorFreq "IDB ECU: a017 wheel speed sensor freq";
CM_ SG_ 1470 IDB_a017_wheelSpeedSensorPhase "IDB ECU: a017 wheel speed sensor phase";
CM_ SG_ 1470 IDB_a017_wheelSpeedSensorMisinst "IDB ECU: a017 wheel speed sensor misinstallation";
CM_ SG_ 1470 IDB_a017_wheelSpeedSensorWrongEx "IDB ECU: a017 wheel speed sensor wrong exciter";
CM_ SG_ 1470 IDB_a017_wheelSpeedSensorSpeedJu "IDB ECU: a017 wheel speed sensor speed jump minus";
CM_ SG_ 1470 IDB_a017_wheelSpeedSensorSp_0001 "IDB ECU: a017 wheel speed sensor speed jump plus";
CM_ SG_ 1470 IDB_a017_wheelSpeedSensorAirGap "IDB ECU: a017 wheel speed sensor air gap";
CM_ SG_ 1470 IDB_a017_wheelSpeedSensorBIST "IDB ECU: a017 wheel speed sensor BIST";
CM_ SG_ 1470 IDB_a017_wheelSpeedSensorLeakage "IDB ECU: a017 wheel speed sensor leakage cur";
CM_ SG_ 1470 IDB_a017_wheelSpeedSensorOverTem "IDB ECU: a017 wheel speed sensor over temp";
CM_ SG_ 1470 IDB_a017_wheelSpeedSensorSh_0001 "IDB ECU: a017 wheel speed sensor short to gnd";
CM_ SG_ 1470 IDB_a017_wheelSpeedSensorShortTo "IDB ECU: a017 wheel speed sensor short to bat";
CM_ SG_ 1470 IDB_a017_wheelSpeedSensorOpen "IDB ECU: a017 wheel speed sensor open";
CM_ SG_ 1470 IDB_a020_canSignalValidity "IDB ECU: a020 can signal validity";
CM_ SG_ 1470 IDB_a020_signalValueCrosscheck "IDB ECU: a020 signal value crosscheck";
CM_ SG_ 1470 IDB_a030_primaryExternalCircuitL "IDB ECU: a030 primary external circuit leakage";
CM_ SG_ 1470 IDB_a030_secondaryExternalCircui "IDB ECU: a030 secondary external circuit leakage";
CM_ SG_ 1470 IDB_a030_primaryChamberInternalL "IDB ECU: a030 primary chamber internal leakage";
CM_ SG_ 1470 IDB_a030_syncModeInternalLeakage "IDB ECU: a030 sync mode internal leakage";
CM_ SG_ 1470 IDB_a030_secondaryChamberInterna "IDB ECU: a030 secondary chamber internal leakage";
CM_ SG_ 1470 IDB_a030_masterCylinderInternalL "IDB ECU: a030 master cylinder internal leakage";
CM_ SG_ 1470 IDB_a060_validityOnChassisBus "IDB ECU: a060 validity on chassis bus";
CM_ SG_ 1470 IDB_a060_validityOnPartyBus "IDB ECU: a060 validity on party bus";
CM_ SG_ 1470 IDB_a061_validityOnChassisBus "IDB ECU: a061 validity on chassis bus";
CM_ SG_ 1470 IDB_a061_validityOnPartyBus "IDB ECU: a061 validity on party bus";
CM_ SG_ 1470 IDB_a063_validityOnChassisBus "IDB ECU: a063 validity on chassis bus";
CM_ SG_ 1470 IDB_a063_validityOnPartyBus "IDB ECU: a063 validity on party bus";
CM_ SG_ 1470 IDB_a064_validityOnChassisBus "IDB ECU: a064 validity on chassis bus";
CM_ SG_ 1470 IDB_a064_validityOnPartyBus "IDB ECU: a064 validity on party bus";
CM_ SG_ 1470 IDB_a065_validityOnChassisBus "IDB ECU: a065 validity on chassis bus";
CM_ SG_ 1470 IDB_a065_validityOnPartyBus "IDB ECU: a065 validity on party bus";
CM_ SG_ 1470 IDB_a106_qualifierValidity "IDB ECU: a106 qualifier validity";
CM_ SG_ 1470 IDB_a106_signalNotAvailable "IDB ECU: a106 signal not available";
CM_ SG_ 1470 IDB_a107_qualifierValidity "IDB ECU: a107 qualifier validity";
CM_ SG_ 1470 IDB_a107_signalNotAvailable "IDB ECU: a107 signal not available";
CM_ SG_ 1470 IDB_a112_qualifierValidity "IDB ECU: a112 qualifier validity";
CM_ SG_ 1470 IDB_a112_signalNotAvailable "IDB ECU: a112 signal not available";
CM_ SG_ 1470 IDB_a113_qualifierValidity "IDB ECU: a113 qualifier validity";
CM_ SG_ 1470 IDB_a113_signalNotAvailable "IDB ECU: a113 signal not available";
CM_ SG_ 1470 IDB_a114_qualifierValidity "IDB ECU: a114 qualifier validity";
CM_ SG_ 1470 IDB_a114_signalNotAvailable "IDB ECU: a114 signal not available";
CM_ SG_ 1470 IDB_a126_PMebrCmdStateValidity "IDB ECU: a126 p mebr cmd state validity";
CM_ SG_ 1470 IDB_a126_PMstate2Validity "IDB ECU: a126 p mstate2 validity";
CM_ SG_ 1470 IDB_a126_PMstate2Missing "IDB ECU: a126 p mstate2 missing";
CM_ SG_ 1470 IDB_a126_DIchassisControlValidit "IDB ECU: a126 d ichassis control validity";
CM_ SG_ 1470 IDB_a126_DIchassisControlMissing "IDB ECU: a126 d ichassis control missing";
CM_ SG_ 1470 IDB_a126_DIrequestActiveValidity "IDB ECU: a126 d irequest active validity";
CM_ SG_ 1470 IDB_a129_validityOnChassisBus "IDB ECU: a129 validity on chassis bus";
CM_ SG_ 1470 IDB_a129_validityOnPartyBus "IDB ECU: a129 validity on party bus";
CM_ SG_ 1470 IDB_a130_PMbrakePedalCmdQFValidi "IDB ECU: a130 p mbrake pedal cmd QF validity";
CM_ SG_ 1470 IDB_a130_PMstate2Validity "IDB ECU: a130 p mstate2 validity";
CM_ SG_ 1470 IDB_a130_PMstate2Missing "IDB ECU: a130 p mstate2 missing";
CM_ SG_ 1470 IDB_a130_DIbrakeCommandValidity "IDB ECU: a130 d ibrake command validity";
CM_ SG_ 1470 IDB_a130_DIbrakeCommandMissing "IDB ECU: a130 d ibrake command missing";
CM_ SG_ 1470 IDB_a130_DIbrakeTorqueCommandFul "IDB ECU: a130 d ibrake torque command full SNA";
CM_ SG_ 1470 IDB_a130_DIbrakeTorqueComma_0001 "IDB ECU: a130 d ibrake torque command full too low";
CM_ SG_ 1470 IDB_a132_validityOnChassisBus "IDB ECU: a132 validity on chassis bus";
CM_ SG_ 1470 IDB_a132_validityOnPartyBus "IDB ECU: a132 validity on party bus";
CM_ BO_ 983 "IDB ECU message: alert matrix; frame length from the layout, not yet observed on a vehicle bus";
CM_ SG_ 983 IDB_matrixIndex "IDB ECU: matrix index";
CM_ SG_ 983 IDB_a001_mcuGenericFault "IDB ECU: a001 mcu generic fault";
CM_ SG_ 983 IDB_a002_supplyOvervoltage "IDB ECU: a002 supply overvoltage";
CM_ SG_ 983 IDB_a003_supplyHardOvervoltage "IDB ECU: a003 supply hard overvoltage";
CM_ SG_ 983 IDB_a004_supplyUndervoltage "IDB ECU: a004 supply undervoltage";
CM_ SG_ 983 IDB_a005_supplyMidUndervoltage "IDB ECU: a005 supply mid undervoltage";
CM_ SG_ 983 IDB_a006_supplyHardUndervoltage "IDB ECU: a006 supply hard undervoltage";
CM_ SG_ 983 IDB_a007_wakeLineOpen "IDB ECU: a007 wake line open";
CM_ SG_ 983 IDB_a008_motorPowerOpen "IDB ECU: a008 motor power open";
CM_ SG_ 983 IDB_a009_asicBoostFault "IDB ECU: a009 asic boost fault";
CM_ SG_ 983 IDB_a010_asicGenericFault "IDB ECU: a010 asic generic fault";
CM_ SG_ 983 IDB_a011_solenoidValveFault "IDB ECU: a011 solenoid valve fault";
CM_ SG_ 983 IDB_a012_motorGenericFault "IDB ECU: a012 motor generic fault";
CM_ SG_ 983 IDB_a013_motorPosSensorFault "IDB ECU: a013 motor pos sensor fault";
CM_ SG_ 983 IDB_a014_FrLWSSFault "IDB ECU: a014 fr LWSS fault";
CM_ SG_ 983 IDB_a015_FrRWSSFault "IDB ECU: a015 fr RWSS fault";
CM_ SG_ 983 IDB_a016_ReLWSSFault "IDB ECU: a016 re LWSS fault";
CM_ SG_ 983 IDB_a017_ReRWSSFault "IDB ECU: a017 re RWSS fault";
CM_ SG_ 983 IDB_a018_WSSGenericFault "IDB ECU: a018 WSS generic fault";
CM_ SG_ 983 IDB_a019_pedalSensorFault "IDB ECU: a019 pedal sensor fault";
CM_ SG_ 983 IDB_a020_RCUpedalTravelMismatch "IDB ECU: a020 RC upedal travel mismatch";
CM_ SG_ 983 IDB_a021_pedalSensorNotCal "IDB ECU: a021 pedal sensor not cal";
CM_ SG_ 983 IDB_a022_brakeFluidLow "IDB ECU: a022 brake fluid low";
CM_ SG_ 983 IDB_a023_steeringImplausible "IDB ECU: a023 steering implausible";
CM_ SG_ 983 IDB_a024_yawImplausible "IDB ECU: a024 yaw implausible";
CM_ SG_ 983 IDB_a025_ayImplausible "IDB ECU: a025 ay implausible";
CM_ SG_ 983 IDB_a026_axImplausible "IDB ECU: a026 ax implausible";
CM_ SG_ 983 IDB_a027_circuitPresSensorFault "IDB ECU: a027 circuit pres sensor fault";
CM_ SG_ 983 IDB_a028_simPresSensorFault "IDB ECU: a028 sim pres sensor fault";
CM_ SG_ 983 IDB_a029_pressureSensNotCal "IDB ECU: a029 pressure sens not cal";
CM_ SG_ 983 IDB_a030_fluidLeakDetected "IDB ECU: a030 fluid leak detected";
CM_ SG_ 983 IDB_a031_solenoidValveStuck "IDB ECU: a031 solenoid valve stuck";
CM_ SG_ 983 IDB_a032_motorSoftOverheat "IDB ECU: a032 motor soft overheat";
CM_ SG_ 983 IDB_a033_motorHardOverheat "IDB ECU: a033 motor hard overheat";
CM_ SG_ 983 IDB_a034_motorPositionSetFault "IDB ECU: a034 motor position set fault";
CM_ SG_ 983 IDB_a035_motorStuck "IDB ECU: a035 motor stuck";
CM_ SG_ 983 IDB_a036_partyBusOff "IDB ECU: a036 party bus off";
CM_ SG_ 983 IDB_a037_chassisBusOff "IDB ECU: a037 chassis bus off";
CM_ SG_ 983 IDB_a038_motorInitFault "IDB ECU: a038 motor init fault";
CM_ SG_ 983 IDB_a039_absActive "IDB ECU: a039 abs active";
CM_ SG_ 983 IDB_a040_ebdActive "IDB ECU: a040 ebd active";
CM_ SG_ 983 IDB_a041_vdcActive "IDB ECU: a041 vdc active";
CM_ SG_ 983 IDB_a042_btcActive "IDB ECU: a042 btc active";
CM_ SG_ 983 IDB_a043_cbcActive "IDB ECU: a043 cbc active";
CM_ SG_ 983 IDB_a044_standstillSkidDetected "IDB ECU: a044 standstill skid detected";
CM_ SG_ 983 IDB_a045_panicBrakeAssistActive "IDB ECU: a045 panic brake assist active";
CM_ SG_ 983 IDB_a046_fadeCompensationActive "IDB ECU: a046 fade compensation active";
CM_ SG_ 983 IDB_a047_brakeDiscWipeActive "IDB ECU: a047 brake disc wipe active";
CM_ SG_ 983 IDB_a048_scmActive "IDB ECU: a048 scm active";
CM_ SG_ 983 IDB_a049_cdpActive "IDB ECU: a049 cdp active";
CM_ SG_ 983 IDB_a050_absFaulted "IDB ECU: a050 abs faulted";
CM_ SG_ 983 IDB_a051_ebdFaulted "IDB ECU: a051 ebd faulted";
CM_ SG_ 983 IDB_a052_vdcFaulted "IDB ECU: a052 vdc faulted";
CM_ SG_ 983 IDB_a053_DItorquePathFaulted "IDB ECU: a053 d itorque path faulted";
CM_ SG_ 983 IDB_a054_skidDetectionFaulted "IDB ECU: a054 skid detection faulted";
CM_ SG_ 983 IDB_a055_panicBrakeAssistFaulted "IDB ECU: a055 panic brake assist faulted";
CM_ SG_ 983 IDB_a056_fadeCompensationFaulted "IDB ECU: a056 fade compensation faulted";
CM_ SG_ 983 IDB_a057_bdwRequestInvalid "IDB ECU: a057 bdw request invalid";
CM_ SG_ 983 IDB_a058_scmFaulted "IDB ECU: a058 scm faulted";
CM_ SG_ 983 IDB_a059_cdpFaulted "IDB ECU: a059 cdp faulted";
CM_ SG_ 983 IDB_a060_RCUstatusDLC "IDB ECU: a060 RC ustatus DLC";
CM_ SG_ 983 IDB_a061_RCUstatusChecksum "IDB ECU: a061 RC ustatus checksum";
CM_ SG_ 983 IDB_a062_RCUstatusCounter "IDB ECU: a062 RC ustatus counter";
CM_ SG_ 983 IDB_a063_RCUactuationDLC "IDB ECU: a063 RC uactuation DLC";
CM_ SG_ 983 IDB_a064_RCUactuationChecksum "IDB ECU: a064 RC uactuation checksum";
CM_ SG_ 983 IDB_a065_RCUactuationCounter "IDB ECU: a065 RC uactuation counter";
CM_ SG_ 983 IDB_a066_DIFtorqueDLC "IDB ECU: a066 DI ftorque DLC";
CM_ SG_ 983 IDB_a067_DIFtorqueChecksum "IDB ECU: a067 DI ftorque checksum";
CM_ SG_ 983 IDB_a068_DIFtorqueCounter "IDB ECU: a068 DI ftorque counter";
CM_ SG_ 983 IDB_a069_DIchassisControlDLC "IDB ECU: a069 d ichassis control DLC";
CM_ SG_ 983 IDB_a070_DIchassisControlChecksu "IDB ECU: a070 d ichassis control checksum";
CM_ SG_ 983 IDB_a071_DIchassisControlCounter "IDB ECU: a071 d ichassis control counter";
CM_ SG_ 983 IDB_a072_DIsystemStatusDLC "IDB ECU: a072 d isystem status DLC";
CM_ SG_ 983 IDB_a073_DIsystemStatusChecksum "IDB ECU: a073 d isystem status checksum";
CM_ SG_ 983 IDB_a074_DIsystemStatusCounter "IDB ECU: a074 d isystem status counter";
CM_ SG_ 983 IDB_a075_DIRtorqueDLC "IDB ECU: a075 DI rtorque DLC";
CM_ SG_ 983 IDB_a076_DIRtorqueChecksum "IDB ECU: a076 DI rtorque checksum";
CM_ SG_ 983 IDB_a077_DIRtorqueCounter "IDB ECU: a077 DI rtorque counter";
CM_ SG_ 983 IDB_a078_DIvdcLeftDLC "IDB ECU: a078 d ivdc left DLC";
CM_ SG_ 983 IDB_a079_DIvdcLeftChecksum "IDB ECU: a079 d ivdc left checksum";
CM_ SG_ 983 IDB_a080_DIvdcLeftCounter "IDB ECU: a080 d ivdc left counter";
CM_ SG_ 983 IDB_a081_DIvdcRightDLC "IDB ECU: a081 d ivdc right DLC";
CM_ SG_ 983 IDB_a082_DIvdcRightChecksum "IDB ECU: a082 d ivdc right checksum";
CM_ SG_ 983 IDB_a083_DIvdcRightCounter "IDB ECU: a083 d ivdc right counter";
CM_ SG_ 983 IDB_a084_EPAS3PsysStatusDLC "IDB ECU: a084 EPAS3 psys status DLC";
CM_ SG_ 983 IDB_a085_EPAS3PsysStatusChecksum "IDB ECU: a085 EPAS3 psys status checksum";
CM_ SG_ 983 IDB_a086_EPAS3PsysStatusCounter "IDB ECU: a086 EPAS3 psys status counter";
CM_ SG_ 983 IDB_a087_PMstate2DLC "IDB ECU: a087 p mstate2 DLC";
CM_ SG_ 983 IDB_a088_PMstate2Checksum "IDB ECU: a088 p mstate2 checksum";
CM_ SG_ 983 IDB_a089_PMstate2Counter "IDB ECU: a089 p mstate2 counter";
CM_ SG_ 983 IDB_a090_RCMinertial1DLC "IDB ECU: a090 RC minertial1 DLC";
CM_ SG_ 983 IDB_a091_RCMinertial1Checksum "IDB ECU: a091 RC minertial1 checksum";
CM_ SG_ 983 IDB_a092_RCMinertial1Counter "IDB ECU: a092 RC minertial1 counter";
CM_ SG_ 983 IDB_a093_RCMinertial2DLC "IDB ECU: a093 RC minertial2 DLC";
CM_ SG_ 983 IDB_a094_RCMinertial2Checksum "IDB ECU: a094 RC minertial2 checksum";
CM_ SG_ 983 IDB_a095_RCMinertial2Counter "IDB ECU: a095 RC minertial2 counter";
CM_ SG_ 983 IDB_a096_VCFRONTLVPowerStateDLC "IDB ECU: a096 VCFRONTLV power state DLC";
CM_ SG_ 983 IDB_a097_VCFRONTLVPwrStChecksum "IDB ECU: a097 VCFRONTLV pwr st checksum";
CM_ SG_ 983 IDB_a098_VCFRONTLVPwrStCounter "IDB ECU: a098 VCFRONTLV pwr st counter";
CM_ SG_ 983 IDB_a099_RCMcollisionDLC "IDB ECU: a099 RC mcollision DLC";
CM_ SG_ 983 IDB_a100_RCMcollisionChecksum "IDB ECU: a100 RC mcollision checksum";
CM_ SG_ 983 IDB_a101_RCMcollisionCounter "IDB ECU: a101 RC mcollision counter";
CM_ SG_ 983 IDB_a102_bdwRequestActiveInvalid "IDB ECU: a102 bdw request active invalid";
CM_ SG_ 983 IDB_a103_DIfullTorquePathFaulted "IDB ECU: a103 d ifull torque path faulted";
CM_ SG_ 983 IDB_a104_DIaccelPosInvalid "IDB ECU: a104 d iaccel pos invalid";
CM_ SG_ 983 IDB_a105_DIgearInvalid "IDB ECU: a105 d igear invalid";
CM_ SG_ 983 IDB_a106_DIFtorqueInvalid "IDB ECU: a106 DI ftorque invalid";
CM_ SG_ 983 IDB_a107_DIRtorqueInvalid "IDB ECU: a107 DI rtorque invalid";
CM_ SG_ 983 IDB_a108_EPBstatusDLC "IDB ECU: a108 EP bstatus DLC";
CM_ SG_ 983 IDB_a109_BDWsignalInvalid "IDB ECU: a109 BD wsignal invalid";
CM_ SG_ 983 IDB_a110_EPBstatusCounter "IDB ECU: a110 EP bstatus counter";
CM_ SG_ 983 IDB_a111_EPBstatusChecksum "IDB ECU: a111 EP bstatus checksum";
CM_ SG_ 983 IDB_a112_yawRateInvalid "IDB ECU: a112 yaw rate invalid";
CM_ SG_ 983 IDB_a113_latAccelInvalid "IDB ECU: a113 lat accel invalid";
CM_ SG_ 983 IDB_a114_longAccelInvalid "IDB ECU: a114 long accel invalid";
CM_ SG_ 983 IDB_a115_VCFRONTespLvStInvalid "IDB ECU: a115 VCFRON tesp lv st invalid";
CM_ SG_ 983 IDB_a116_VCFRONTsensorsDLC "IDB ECU: a116 VCFRON tsensors DLC";
CM_ SG_ 983 IDB_a117_VCLEFTepbmStatusDLC "IDB ECU: a117 VCLEF tepbm status DLC";
CM_ SG_ 983 IDB_a118_VCLEFTepbmStatusCounter "IDB ECU: a118 VCLEF tepbm status counter";
CM_ SG_ 983 IDB_a119_VCLEFTepbmStatusChecksu "IDB ECU: a119 VCLEF tepbm status checksum";
CM_ SG_ 983 IDB_a120_EPAS3Pinvalid "IDB ECU: a120 EPAS3 pinvalid";
CM_ SG_ 983 IDB_a121_dynoModeActive "IDB ECU: a121 dyno mode active";
CM_ SG_ 983 IDB_a122_DIFtorqueCommandInvalid "IDB ECU: a122 DI ftorque command invalid";
CM_ SG_ 983 IDB_a123_DIRtorqueCommandInvalid "IDB ECU: a123 DI rtorque command invalid";
CM_ SG_ 983 IDB_a124_VCFRONTtempInvalid "IDB ECU: a124 VCFRON ttemp invalid";
CM_ SG_ 983 IDB_a125_PMvdcCmdStateInvalid "IDB ECU: a125 p mvdc cmd state invalid";
CM_ SG_ 983 IDB_a126_DItorqueRequestInvalid "IDB ECU: a126 d itorque request invalid";
CM_ SG_ 983 IDB_a127_brakeFluidLevelInvalid "IDB ECU: a127 brake fluid level invalid";
CM_ SG_ 983 IDB_a128_largeAirVolume "IDB ECU: a128 large air volume";
CM_ SG_ 983 IDB_a129_RCUinputRodStrokeInvali "IDB ECU: a129 RC uinput rod stroke invalid";
CM_ SG_ 983 IDB_a130_DIfullTorqueRequestInva "IDB ECU: a130 d ifull torque request invalid";
CM_ SG_ 983 IDB_a131_cbcFaulted "IDB ECU: a131 cbc faulted";
CM_ SG_ 983 IDB_a132_RCUinputRodStrokeQFInva "IDB ECU: a132 RC uinput rod stroke QF invalid";
CM_ SG_ 983 IDB_a133_DIbrakeCommandDLC "IDB ECU: a133 d ibrake command DLC";
CM_ SG_ 983 IDB_a134_DIbrakeCommandCounter "IDB ECU: a134 d ibrake command counter";
CM_ SG_ 983 IDB_a135_DIbrakeCommandChecksum "IDB ECU: a135 d ibrake command checksum";
CM_ SG_ 983 IDB_a136_RCUptsCalMissing "IDB ECU: a136 RC upts cal missing";
CM_ SG_ 983 IDB_a137_VCLEFTcdpRequestInvalid "IDB ECU: a137 VCLEF tcdp request invalid";
CM_ SG_ 983 IDB_a138_DIbrakeTorqueCommandAnd "IDB ECU: a138 d ibrake torque command and flag mismatch";
CM_ SG_ 983 IDB_a139_DIbrakeTorqueCommandFul "IDB ECU: a139 d ibrake torque command full SNA";
CM_ SG_ 983 IDB_a140_PMbrakePedalCmdQFInvali "IDB ECU: a140 p mbrake pedal cmd QF invalid";
CM_ SG_ 983 IDB_a141_DIbrakeTorqueCommandFul "IDB ECU: a141 d ibrake torque command full too low";
CM_ SG_ 983 IDB_a142_PMebrCmdStateInvalid "IDB ECU: a142 p mebr cmd state invalid";
CM_ SG_ 983 IDB_a143_factoryModeActive "IDB ECU: a143 factory mode active";
CM_ SG_ 983 IDB_a144_hydraulicPushthroughAct "IDB ECU: a144 hydraulic pushthrough active";
CM_ SG_ 983 IDB_a145_DASredundantBrakingCont "IDB ECU: a145 DA sredundant braking control DLC";
CM_ SG_ 983 IDB_a146_DASredundantBrakingCont "IDB ECU: a146 DA sredundant braking control counter";
CM_ SG_ 983 IDB_a147_DASredundantBrakingCont "IDB ECU: a147 DA sredundant braking control checksum";
CM_ SG_ 983 IDB_a148_DASbrakeTorqueCommandIn "IDB ECU: a148 DA sbrake torque command invalid";
CM_ SG_ 983 IDB_a149_DASmiaBrakeTorqueComman "IDB ECU: a149 DA smia brake torque command invalid";
CM_ SG_ 983 IDB_a150_DIlocStatus2DLC "IDB ECU: a150 d iloc status2 DLC";
CM_ SG_ 983 IDB_a151_DIlocStatus2Counter "IDB ECU: a151 d iloc status2 counter";
CM_ SG_ 983 IDB_a152_DIlocStatus2Checksum "IDB ECU: a152 d iloc status2 checksum";
CM_ SG_ 983 IDB_a155_PMlocStateDLC "IDB ECU: a155 p mloc state DLC";
CM_ SG_ 983 IDB_a156_PMlocStateChecksum "IDB ECU: a156 p mloc state checksum";
CM_ SG_ 983 IDB_a157_PMlocStateCounter "IDB ECU: a157 p mloc state counter";
CM_ BO_ 828 "IDB ECU message: info; frame length from the layout, not yet observed on a vehicle bus";
CM_ SG_ 828 IDB_infoIndex "IDB ECU: info index";
CM_ SG_ 828 IDB_infoPcbaID "IDB ECU: info pcba ID";
CM_ SG_ 828 IDB_infoAssemblyID "IDB ECU: info assembly ID";
CM_ SG_ 828 IDB_infoUsageID "IDB ECU: info usage ID";
CM_ SG_ 828 IDB_infoSubUsageID "IDB ECU: info sub usage ID";
CM_ BO_ 1486 "Parking assist sensors message: alert log; frame length from the layout, not yet observed on a vehicle bus";
CM_ SG_ 1486 PARK_alertID "Parking assist sensors: alert ID";
CM_ SG_ 1486 PARK_alertState "Parking assist sensors: alert state";
CM_ SG_ 1486 PARK_sw001_sensorTemperature "Parking assist sensors: sw001 sensor temperature";
CM_ SG_ 1486 PARK_sw002_membraneDisconct "Parking assist sensors: sw002 membrane disconct";
CM_ SG_ 1486 PARK_sw002_dampResistorFail "Parking assist sensors: sw002 damp resistor fail";
CM_ SG_ 1486 PARK_sw002_resonanceDrift "Parking assist sensors: sw002 resonance drift";
CM_ SG_ 1486 PARK_sw002_sensorCRC "Parking assist sensors: sw002 sensor CRC";
CM_ SG_ 1486 PARK_sw002_recieveFailure "Parking assist sensors: sw002 recieve failure";
CM_ SG_ 1486 PARK_sw002_diagnosticTransferErr "Parking assist sensors: sw002 diagnostic transfer error";
CM_ SG_ 1486 PARK_sw003_linError "Parking assist sensors: sw003 lin error";
CM_ SG_ 1486 PARK_sw003_linBusError "Parking assist sensors: sw003 lin bus error";
CM_ SG_ 1486 PARK_sw003_linFrameCountError "Parking assist sensors: sw003 lin frame count error";
CM_ SG_ 1486 PARK_sw004_reverbPeriod "Parking assist sensors: sw004 reverb period";
CM_ SG_ 1486 PARK_sw004_reverbTime "Parking assist sensors: sw004 reverb time";
CM_ SG_ 1486 PARK_sw004_highAttenTime "Parking assist sensors: sw004 high atten time";
CM_ SG_ 1486 PARK_sw004_closeConstEcho "Parking assist sensors: sw004 close const echo";
CM_ SG_ 1486 PARK_sw004_lowAttenTime "Parking assist sensors: sw004 low atten time";
CM_ SG_ 1486 PARK_sw004_attenTimeJitter "Parking assist sensors: sw004 atten time jitter";
CM_ SG_ 1486 PARK_sw004_reverbFreqJitter "Parking assist sensors: sw004 reverb freq jitter";
CM_ SG_ 1486 PARK_sw006_sensorTemperature "Parking assist sensors: sw006 sensor temperature";
CM_ SG_ 1486 PARK_sw007_membraneDisconct "Parking assist sensors: sw007 membrane disconct";
CM_ SG_ 1486 PARK_sw007_dampResistorFail "Parking assist sensors: sw007 damp resistor fail";
CM_ SG_ 1486 PARK_sw007_resonanceDrift "Parking assist sensors: sw007 resonance drift";
CM_ SG_ 1486 PARK_sw007_sensorCRC "Parking assist sensors: sw007 sensor CRC";
CM_ SG_ 1486 PARK_sw007_recieveFailure "Parking assist sensors: sw007 recieve failure";
CM_ SG_ 1486 PARK_sw007_diagnosticTransferErr "Parking assist sensors: sw007 diagnostic transfer error";
CM_ SG_ 1486 PARK_sw008_linError "Parking assist sensors: sw008 lin error";
CM_ SG_ 1486 PARK_sw008_linBusError "Parking assist sensors: sw008 lin bus error";
CM_ SG_ 1486 PARK_sw008_linFrameCountError "Parking assist sensors: sw008 lin frame count error";
CM_ SG_ 1486 PARK_sw009_reverbPeriod "Parking assist sensors: sw009 reverb period";
CM_ SG_ 1486 PARK_sw009_reverbTime "Parking assist sensors: sw009 reverb time";
CM_ SG_ 1486 PARK_sw009_highAttenTime "Parking assist sensors: sw009 high atten time";
CM_ SG_ 1486 PARK_sw009_closeConstEcho "Parking assist sensors: sw009 close const echo";
CM_ SG_ 1486 PARK_sw009_lowAttenTime "Parking assist sensors: sw009 low atten time";
CM_ SG_ 1486 PARK_sw009_attenTimeJitter "Parking assist sensors: sw009 atten time jitter";
CM_ SG_ 1486 PARK_sw009_reverbFreqJitter "Parking assist sensors: sw009 reverb freq jitter";
CM_ SG_ 1486 PARK_sw011_sensorTemperature "Parking assist sensors: sw011 sensor temperature";
CM_ SG_ 1486 PARK_sw012_membraneDisconct "Parking assist sensors: sw012 membrane disconct";
CM_ SG_ 1486 PARK_sw012_dampResistorFail "Parking assist sensors: sw012 damp resistor fail";
CM_ SG_ 1486 PARK_sw012_resonanceDrift "Parking assist sensors: sw012 resonance drift";
CM_ SG_ 1486 PARK_sw012_sensorCRC "Parking assist sensors: sw012 sensor CRC";
CM_ SG_ 1486 PARK_sw012_recieveFailure "Parking assist sensors: sw012 recieve failure";
CM_ SG_ 1486 PARK_sw012_diagnosticTransferErr "Parking assist sensors: sw012 diagnostic transfer error";
CM_ SG_ 1486 PARK_sw013_linError "Parking assist sensors: sw013 lin error";
CM_ SG_ 1486 PARK_sw013_linBusError "Parking assist sensors: sw013 lin bus error";
CM_ SG_ 1486 PARK_sw013_linFrameCountError "Parking assist sensors: sw013 lin frame count error";
CM_ SG_ 1486 PARK_sw014_reverbPeriod "Parking assist sensors: sw014 reverb period";
CM_ SG_ 1486 PARK_sw014_reverbTime "Parking assist sensors: sw014 reverb time";
CM_ SG_ 1486 PARK_sw014_highAttenTime "Parking assist sensors: sw014 high atten time";
CM_ SG_ 1486 PARK_sw014_closeConstEcho "Parking assist sensors: sw014 close const echo";
CM_ SG_ 1486 PARK_sw014_lowAttenTime "Parking assist sensors: sw014 low atten time";
CM_ SG_ 1486 PARK_sw014_attenTimeJitter "Parking assist sensors: sw014 atten time jitter";
CM_ SG_ 1486 PARK_sw014_reverbFreqJitter "Parking assist sensors: sw014 reverb freq jitter";
CM_ SG_ 1486 PARK_sw016_sensorTemperature "Parking assist sensors: sw016 sensor temperature";
CM_ SG_ 1486 PARK_sw017_membraneDisconct "Parking assist sensors: sw017 membrane disconct";
CM_ SG_ 1486 PARK_sw017_dampResistorFail "Parking assist sensors: sw017 damp resistor fail";
CM_ SG_ 1486 PARK_sw017_resonanceDrift "Parking assist sensors: sw017 resonance drift";
CM_ SG_ 1486 PARK_sw017_sensorCRC "Parking assist sensors: sw017 sensor CRC";
CM_ SG_ 1486 PARK_sw017_recieveFailure "Parking assist sensors: sw017 recieve failure";
CM_ SG_ 1486 PARK_sw017_diagnosticTransferErr "Parking assist sensors: sw017 diagnostic transfer error";
CM_ SG_ 1486 PARK_sw018_linError "Parking assist sensors: sw018 lin error";
CM_ SG_ 1486 PARK_sw018_linBusError "Parking assist sensors: sw018 lin bus error";
CM_ SG_ 1486 PARK_sw018_linFrameCountError "Parking assist sensors: sw018 lin frame count error";
CM_ SG_ 1486 PARK_sw019_reverbPeriod "Parking assist sensors: sw019 reverb period";
CM_ SG_ 1486 PARK_sw019_reverbTime "Parking assist sensors: sw019 reverb time";
CM_ SG_ 1486 PARK_sw019_highAttenTime "Parking assist sensors: sw019 high atten time";
CM_ SG_ 1486 PARK_sw019_closeConstEcho "Parking assist sensors: sw019 close const echo";
CM_ SG_ 1486 PARK_sw019_lowAttenTime "Parking assist sensors: sw019 low atten time";
CM_ SG_ 1486 PARK_sw019_attenTimeJitter "Parking assist sensors: sw019 atten time jitter";
CM_ SG_ 1486 PARK_sw019_reverbFreqJitter "Parking assist sensors: sw019 reverb freq jitter";
CM_ SG_ 1486 PARK_sw021_sensorTemperature "Parking assist sensors: sw021 sensor temperature";
CM_ SG_ 1486 PARK_sw022_membraneDisconct "Parking assist sensors: sw022 membrane disconct";
CM_ SG_ 1486 PARK_sw022_dampResistorFail "Parking assist sensors: sw022 damp resistor fail";
CM_ SG_ 1486 PARK_sw022_resonanceDrift "Parking assist sensors: sw022 resonance drift";
CM_ SG_ 1486 PARK_sw022_sensorCRC "Parking assist sensors: sw022 sensor CRC";
CM_ SG_ 1486 PARK_sw022_recieveFailure "Parking assist sensors: sw022 recieve failure";
CM_ SG_ 1486 PARK_sw022_diagnosticTransferErr "Parking assist sensors: sw022 diagnostic transfer error";
CM_ SG_ 1486 PARK_sw023_linError "Parking assist sensors: sw023 lin error";
CM_ SG_ 1486 PARK_sw023_linBusError "Parking assist sensors: sw023 lin bus error";
CM_ SG_ 1486 PARK_sw023_linFrameCountError "Parking assist sensors: sw023 lin frame count error";
CM_ SG_ 1486 PARK_sw024_reverbPeriod "Parking assist sensors: sw024 reverb period";
CM_ SG_ 1486 PARK_sw024_reverbTime "Parking assist sensors: sw024 reverb time";
CM_ SG_ 1486 PARK_sw024_highAttenTime "Parking assist sensors: sw024 high atten time";
CM_ SG_ 1486 PARK_sw024_closeConstEcho "Parking assist sensors: sw024 close const echo";
CM_ SG_ 1486 PARK_sw024_lowAttenTime "Parking assist sensors: sw024 low atten time";
CM_ SG_ 1486 PARK_sw024_attenTimeJitter "Parking assist sensors: sw024 atten time jitter";
CM_ SG_ 1486 PARK_sw024_reverbFreqJitter "Parking assist sensors: sw024 reverb freq jitter";
CM_ SG_ 1486 PARK_sw026_sensorTemperature "Parking assist sensors: sw026 sensor temperature";
CM_ SG_ 1486 PARK_sw027_membraneDisconct "Parking assist sensors: sw027 membrane disconct";
CM_ SG_ 1486 PARK_sw027_dampResistorFail "Parking assist sensors: sw027 damp resistor fail";
CM_ SG_ 1486 PARK_sw027_resonanceDrift "Parking assist sensors: sw027 resonance drift";
CM_ SG_ 1486 PARK_sw027_sensorCRC "Parking assist sensors: sw027 sensor CRC";
CM_ SG_ 1486 PARK_sw027_recieveFailure "Parking assist sensors: sw027 recieve failure";
CM_ SG_ 1486 PARK_sw027_diagnosticTransferErr "Parking assist sensors: sw027 diagnostic transfer error";
CM_ SG_ 1486 PARK_sw028_linError "Parking assist sensors: sw028 lin error";
CM_ SG_ 1486 PARK_sw028_linBusError "Parking assist sensors: sw028 lin bus error";
CM_ SG_ 1486 PARK_sw028_linFrameCountError "Parking assist sensors: sw028 lin frame count error";
CM_ SG_ 1486 PARK_sw029_reverbPeriod "Parking assist sensors: sw029 reverb period";
CM_ SG_ 1486 PARK_sw029_reverbTime "Parking assist sensors: sw029 reverb time";
CM_ SG_ 1486 PARK_sw029_highAttenTime "Parking assist sensors: sw029 high atten time";
CM_ SG_ 1486 PARK_sw029_closeConstEcho "Parking assist sensors: sw029 close const echo";
CM_ SG_ 1486 PARK_sw029_lowAttenTime "Parking assist sensors: sw029 low atten time";
CM_ SG_ 1486 PARK_sw029_attenTimeJitter "Parking assist sensors: sw029 atten time jitter";
CM_ SG_ 1486 PARK_sw029_reverbFreqJitter "Parking assist sensors: sw029 reverb freq jitter";
CM_ SG_ 1486 PARK_sw031_sensorTemperature "Parking assist sensors: sw031 sensor temperature";
CM_ SG_ 1486 PARK_sw032_membraneDisconct "Parking assist sensors: sw032 membrane disconct";
CM_ SG_ 1486 PARK_sw032_dampResistorFail "Parking assist sensors: sw032 damp resistor fail";
CM_ SG_ 1486 PARK_sw032_resonanceDrift "Parking assist sensors: sw032 resonance drift";
CM_ SG_ 1486 PARK_sw032_sensorCRC "Parking assist sensors: sw032 sensor CRC";
CM_ SG_ 1486 PARK_sw032_recieveFailure "Parking assist sensors: sw032 recieve failure";
CM_ SG_ 1486 PARK_sw032_diagnosticTransferErr "Parking assist sensors: sw032 diagnostic transfer error";
CM_ SG_ 1486 PARK_sw033_linError "Parking assist sensors: sw033 lin error";
CM_ SG_ 1486 PARK_sw033_linBusError "Parking assist sensors: sw033 lin bus error";
CM_ SG_ 1486 PARK_sw033_linFrameCountError "Parking assist sensors: sw033 lin frame count error";
CM_ SG_ 1486 PARK_sw034_reverbPeriod "Parking assist sensors: sw034 reverb period";
CM_ SG_ 1486 PARK_sw034_reverbTime "Parking assist sensors: sw034 reverb time";
CM_ SG_ 1486 PARK_sw034_highAttenTime "Parking assist sensors: sw034 high atten time";
CM_ SG_ 1486 PARK_sw034_closeConstEcho "Parking assist sensors: sw034 close const echo";
CM_ SG_ 1486 PARK_sw034_lowAttenTime "Parking assist sensors: sw034 low atten time";
CM_ SG_ 1486 PARK_sw034_attenTimeJitter "Parking assist sensors: sw034 atten time jitter";
CM_ SG_ 1486 PARK_sw034_reverbFreqJitter "Parking assist sensors: sw034 reverb freq jitter";
CM_ SG_ 1486 PARK_sw036_sensorTemperature "Parking assist sensors: sw036 sensor temperature";
CM_ SG_ 1486 PARK_sw037_membraneDisconct "Parking assist sensors: sw037 membrane disconct";
CM_ SG_ 1486 PARK_sw037_dampResistorFail "Parking assist sensors: sw037 damp resistor fail";
CM_ SG_ 1486 PARK_sw037_resonanceDrift "Parking assist sensors: sw037 resonance drift";
CM_ SG_ 1486 PARK_sw037_sensorCRC "Parking assist sensors: sw037 sensor CRC";
CM_ SG_ 1486 PARK_sw037_recieveFailure "Parking assist sensors: sw037 recieve failure";
CM_ SG_ 1486 PARK_sw037_diagnosticTransferErr "Parking assist sensors: sw037 diagnostic transfer error";
CM_ SG_ 1486 PARK_sw038_linError "Parking assist sensors: sw038 lin error";
CM_ SG_ 1486 PARK_sw038_linBusError "Parking assist sensors: sw038 lin bus error";
CM_ SG_ 1486 PARK_sw038_linFrameCountError "Parking assist sensors: sw038 lin frame count error";
CM_ SG_ 1486 PARK_sw039_reverbPeriod "Parking assist sensors: sw039 reverb period";
CM_ SG_ 1486 PARK_sw039_reverbTime "Parking assist sensors: sw039 reverb time";
CM_ SG_ 1486 PARK_sw039_highAttenTime "Parking assist sensors: sw039 high atten time";
CM_ SG_ 1486 PARK_sw039_closeConstEcho "Parking assist sensors: sw039 close const echo";
CM_ SG_ 1486 PARK_sw039_lowAttenTime "Parking assist sensors: sw039 low atten time";
CM_ SG_ 1486 PARK_sw039_attenTimeJitter "Parking assist sensors: sw039 atten time jitter";
CM_ SG_ 1486 PARK_sw039_reverbFreqJitter "Parking assist sensors: sw039 reverb freq jitter";
CM_ SG_ 1486 PARK_sw041_sensorTemperature "Parking assist sensors: sw041 sensor temperature";
CM_ SG_ 1486 PARK_sw042_membraneDisconct "Parking assist sensors: sw042 membrane disconct";
CM_ SG_ 1486 PARK_sw042_dampResistorFail "Parking assist sensors: sw042 damp resistor fail";
CM_ SG_ 1486 PARK_sw042_resonanceDrift "Parking assist sensors: sw042 resonance drift";
CM_ SG_ 1486 PARK_sw042_sensorCRC "Parking assist sensors: sw042 sensor CRC";
CM_ SG_ 1486 PARK_sw042_recieveFailure "Parking assist sensors: sw042 recieve failure";
CM_ SG_ 1486 PARK_sw042_diagnosticTransferErr "Parking assist sensors: sw042 diagnostic transfer error";
CM_ SG_ 1486 PARK_sw043_linError "Parking assist sensors: sw043 lin error";
CM_ SG_ 1486 PARK_sw043_linBusError "Parking assist sensors: sw043 lin bus error";
CM_ SG_ 1486 PARK_sw043_linFrameCountError "Parking assist sensors: sw043 lin frame count error";
CM_ SG_ 1486 PARK_sw044_reverbPeriod "Parking assist sensors: sw044 reverb period";
CM_ SG_ 1486 PARK_sw044_reverbTime "Parking assist sensors: sw044 reverb time";
CM_ SG_ 1486 PARK_sw044_highAttenTime "Parking assist sensors: sw044 high atten time";
CM_ SG_ 1486 PARK_sw044_closeConstEcho "Parking assist sensors: sw044 close const echo";
CM_ SG_ 1486 PARK_sw044_lowAttenTime "Parking assist sensors: sw044 low atten time";
CM_ SG_ 1486 PARK_sw044_attenTimeJitter "Parking assist sensors: sw044 atten time jitter";
CM_ SG_ 1486 PARK_sw044_reverbFreqJitter "Parking assist sensors: sw044 reverb freq jitter";
CM_ SG_ 1486 PARK_sw046_sensorTemperature "Parking assist sensors: sw046 sensor temperature";
CM_ SG_ 1486 PARK_sw047_membraneDisconct "Parking assist sensors: sw047 membrane disconct";
CM_ SG_ 1486 PARK_sw047_dampResistorFail "Parking assist sensors: sw047 damp resistor fail";
CM_ SG_ 1486 PARK_sw047_resonanceDrift "Parking assist sensors: sw047 resonance drift";
CM_ SG_ 1486 PARK_sw047_sensorCRC "Parking assist sensors: sw047 sensor CRC";
CM_ SG_ 1486 PARK_sw047_recieveFailure "Parking assist sensors: sw047 recieve failure";
CM_ SG_ 1486 PARK_sw047_diagnosticTransferErr "Parking assist sensors: sw047 diagnostic transfer error";
CM_ SG_ 1486 PARK_sw048_linError "Parking assist sensors: sw048 lin error";
CM_ SG_ 1486 PARK_sw048_linBusError "Parking assist sensors: sw048 lin bus error";
CM_ SG_ 1486 PARK_sw048_linFrameCountError "Parking assist sensors: sw048 lin frame count error";
CM_ SG_ 1486 PARK_sw049_reverbPeriod "Parking assist sensors: sw049 reverb period";
CM_ SG_ 1486 PARK_sw049_reverbTime "Parking assist sensors: sw049 reverb time";
CM_ SG_ 1486 PARK_sw049_highAttenTime "Parking assist sensors: sw049 high atten time";
CM_ SG_ 1486 PARK_sw049_closeConstEcho "Parking assist sensors: sw049 close const echo";
CM_ SG_ 1486 PARK_sw049_lowAttenTime "Parking assist sensors: sw049 low atten time";
CM_ SG_ 1486 PARK_sw049_attenTimeJitter "Parking assist sensors: sw049 atten time jitter";
CM_ SG_ 1486 PARK_sw049_reverbFreqJitter "Parking assist sensors: sw049 reverb freq jitter";
CM_ SG_ 1486 PARK_sw051_sensorTemperature "Parking assist sensors: sw051 sensor temperature";
CM_ SG_ 1486 PARK_sw052_membraneDisconct "Parking assist sensors: sw052 membrane disconct";
CM_ SG_ 1486 PARK_sw052_dampResistorFail "Parking assist sensors: sw052 damp resistor fail";
CM_ SG_ 1486 PARK_sw052_resonanceDrift "Parking assist sensors: sw052 resonance drift";
CM_ SG_ 1486 PARK_sw052_sensorCRC "Parking assist sensors: sw052 sensor CRC";
CM_ SG_ 1486 PARK_sw052_recieveFailure "Parking assist sensors: sw052 recieve failure";
CM_ SG_ 1486 PARK_sw052_diagnosticTransferErr "Parking assist sensors: sw052 diagnostic transfer error";
CM_ SG_ 1486 PARK_sw053_linError "Parking assist sensors: sw053 lin error";
CM_ SG_ 1486 PARK_sw053_linBusError "Parking assist sensors: sw053 lin bus error";
CM_ SG_ 1486 PARK_sw053_linFrameCountError "Parking assist sensors: sw053 lin frame count error";
CM_ SG_ 1486 PARK_sw054_reverbPeriod "Parking assist sensors: sw054 reverb period";
CM_ SG_ 1486 PARK_sw054_reverbTime "Parking assist sensors: sw054 reverb time";
CM_ SG_ 1486 PARK_sw054_highAttenTime "Parking assist sensors: sw054 high atten time";
CM_ SG_ 1486 PARK_sw054_closeConstEcho "Parking assist sensors: sw054 close const echo";
CM_ SG_ 1486 PARK_sw054_lowAttenTime "Parking assist sensors: sw054 low atten time";
CM_ SG_ 1486 PARK_sw054_attenTimeJitter "Parking assist sensors: sw054 atten time jitter";
CM_ SG_ 1486 PARK_sw054_reverbFreqJitter "Parking assist sensors: sw054 reverb freq jitter";
CM_ SG_ 1486 PARK_sw056_sensorTemperature "Parking assist sensors: sw056 sensor temperature";
CM_ SG_ 1486 PARK_sw057_membraneDisconct "Parking assist sensors: sw057 membrane disconct";
CM_ SG_ 1486 PARK_sw057_dampResistorFail "Parking assist sensors: sw057 damp resistor fail";
CM_ SG_ 1486 PARK_sw057_resonanceDrift "Parking assist sensors: sw057 resonance drift";
CM_ SG_ 1486 PARK_sw057_sensorCRC "Parking assist sensors: sw057 sensor CRC";
CM_ SG_ 1486 PARK_sw057_recieveFailure "Parking assist sensors: sw057 recieve failure";
CM_ SG_ 1486 PARK_sw057_diagnosticTransferErr "Parking assist sensors: sw057 diagnostic transfer error";
CM_ SG_ 1486 PARK_sw058_linError "Parking assist sensors: sw058 lin error";
CM_ SG_ 1486 PARK_sw058_linBusError "Parking assist sensors: sw058 lin bus error";
CM_ SG_ 1486 PARK_sw058_linFrameCountError "Parking assist sensors: sw058 lin frame count error";
CM_ SG_ 1486 PARK_sw059_reverbPeriod "Parking assist sensors: sw059 reverb period";
CM_ SG_ 1486 PARK_sw059_reverbTime "Parking assist sensors: sw059 reverb time";
CM_ SG_ 1486 PARK_sw059_highAttenTime "Parking assist sensors: sw059 high atten time";
CM_ SG_ 1486 PARK_sw059_closeConstEcho "Parking assist sensors: sw059 close const echo";
CM_ SG_ 1486 PARK_sw059_lowAttenTime "Parking assist sensors: sw059 low atten time";
CM_ SG_ 1486 PARK_sw059_attenTimeJitter "Parking assist sensors: sw059 atten time jitter";
CM_ SG_ 1486 PARK_sw059_reverbFreqJitter "Parking assist sensors: sw059 reverb freq jitter";
CM_ SG_ 1486 PARK_sw061_voltage "Parking assist sensors: sw061 voltage";
CM_ SG_ 1486 PARK_sw063_voltage "Parking assist sensors: sw063 voltage";
CM_ SG_ 1486 PARK_sw064_faultCode "Parking assist sensors: sw064 fault code";
CM_ SG_ 1486 PARK_sw065_expectedCRC "Parking assist sensors: sw065 expected CRC";
CM_ SG_ 1486 PARK_sw065_calculatedCRC "Parking assist sensors: sw065 calculated CRC";
CM_ SG_ 1486 PARK_sw066_placeHolder "Parking assist sensors: sw066 place holder";
CM_ SG_ 1486 PARK_sw068_placeHolder "Parking assist sensors: sw068 place holder";
CM_ SG_ 1486 PARK_sw069_messageID "Parking assist sensors: sw069 message ID";
CM_ SG_ 1486 PARK_sw070_messageID "Parking assist sensors: sw070 message ID";
CM_ SG_ 1486 PARK_sw071_messageID "Parking assist sensors: sw071 message ID";
CM_ SG_ 1486 PARK_sw072_messageID "Parking assist sensors: sw072 message ID";
CM_ SG_ 1486 PARK_sw073_messageID "Parking assist sensors: sw073 message ID";
CM_ SG_ 1486 PARK_sw074_messageID "Parking assist sensors: sw074 message ID";
CM_ SG_ 1486 PARK_sw075_messageID "Parking assist sensors: sw075 message ID";
CM_ SG_ 1486 PARK_sw076_messageID "Parking assist sensors: sw076 message ID";
CM_ SG_ 1486 PARK_sw077_errorExp "Parking assist sensors: sw077 error exp";
CM_ SG_ 1486 PARK_sw077_errorRx "Parking assist sensors: sw077 error rx";
CM_ SG_ 1486 PARK_sw077_messageID "Parking assist sensors: sw077 message ID";
CM_ SG_ 1486 PARK_sw077_errorType "Parking assist sensors: sw077 error type";
CM_ SG_ 1486 PARK_sw078_errorExp "Parking assist sensors: sw078 error exp";
CM_ SG_ 1486 PARK_sw078_errorRx "Parking assist sensors: sw078 error rx";
CM_ SG_ 1486 PARK_sw078_messageID "Parking assist sensors: sw078 message ID";
CM_ SG_ 1486 PARK_sw078_errorType "Parking assist sensors: sw078 error type";
CM_ SG_ 1486 PARK_sw079_errorExp "Parking assist sensors: sw079 error exp";
CM_ SG_ 1486 PARK_sw079_errorRx "Parking assist sensors: sw079 error rx";
CM_ SG_ 1486 PARK_sw079_messageID "Parking assist sensors: sw079 message ID";
CM_ SG_ 1486 PARK_sw079_errorType "Parking assist sensors: sw079 error type";
CM_ SG_ 1486 PARK_sw080_errorExp "Parking assist sensors: sw080 error exp";
CM_ SG_ 1486 PARK_sw080_errorRx "Parking assist sensors: sw080 error rx";
CM_ SG_ 1486 PARK_sw080_messageID "Parking assist sensors: sw080 message ID";
CM_ SG_ 1486 PARK_sw080_errorType "Parking assist sensors: sw080 error type";
CM_ SG_ 1486 PARK_sw081_errorExp "Parking assist sensors: sw081 error exp";
CM_ SG_ 1486 PARK_sw081_errorRx "Parking assist sensors: sw081 error rx";
CM_ SG_ 1486 PARK_sw081_messageID "Parking assist sensors: sw081 message ID";
CM_ SG_ 1486 PARK_sw081_errorType "Parking assist sensors: sw081 error type";
CM_ SG_ 1486 PARK_sw082_errorExp "Parking assist sensors: sw082 error exp";
CM_ SG_ 1486 PARK_sw082_errorRx "Parking assist sensors: sw082 error rx";
CM_ SG_ 1486 PARK_sw082_messageID "Parking assist sensors: sw082 message ID";
CM_ SG_ 1486 PARK_sw082_errorType "Parking assist sensors: sw082 error type";
CM_ SG_ 1486 PARK_sw083_errorExp "Parking assist sensors: sw083 error exp";
CM_ SG_ 1486 PARK_sw083_errorRx "Parking assist sensors: sw083 error rx";
CM_ SG_ 1486 PARK_sw083_messageID "Parking assist sensors: sw083 message ID";
CM_ SG_ 1486 PARK_sw083_errorType "Parking assist sensors: sw083 error type";
CM_ SG_ 1486 PARK_sw084_errorExp "Parking assist sensors: sw084 error exp";
CM_ SG_ 1486 PARK_sw084_errorRx "Parking assist sensors: sw084 error rx";
CM_ SG_ 1486 PARK_sw084_messageID "Parking assist sensors: sw084 message ID";
CM_ SG_ 1486 PARK_sw084_errorType "Parking assist sensors: sw084 error type";
CM_ SG_ 1486 PARK_sw086_writeRetryCounter "Parking assist sensors: sw086 write retry counter";
CM_ SG_ 1486 PARK_sw086_readRetryCounter "Parking assist sensors: sw086 read retry counter";
CM_ SG_ 1486 PARK_sw086_currentErrorCode "Parking assist sensors: sw086 current error code";
CM_ SG_ 1486 PARK_sw087_s1_sensorType "Parking assist sensors: sw087 s1 sensor type; raw 3 = signal not available (SNA)";
CM_ SG_ 1486 PARK_sw087_s2_sensorType "Parking assist sensors: sw087 s2 sensor type; raw 3 = signal not available (SNA)";
CM_ SG_ 1486 PARK_sw087_s3_sensorType "Parking assist sensors: sw087 s3 sensor type; raw 3 = signal not available (SNA)";
CM_ SG_ 1486 PARK_sw087_s4_sensorType "Parking assist sensors: sw087 s4 sensor type; raw 3 = signal not available (SNA)";
CM_ SG_ 1486 PARK_sw087_s5_sensorType "Parking assist sensors: sw087 s5 sensor type; raw 3 = signal not available (SNA)";
CM_ SG_ 1486 PARK_sw087_s6_sensorType "Parking assist sensors: sw087 s6 sensor type; raw 3 = signal not available (SNA)";
CM_ SG_ 1486 PARK_sw087_s7_sensorType "Parking assist sensors: sw087 s7 sensor type; raw 3 = signal not available (SNA)";
CM_ SG_ 1486 PARK_sw087_s8_sensorType "Parking assist sensors: sw087 s8 sensor type; raw 3 = signal not available (SNA)";
CM_ SG_ 1486 PARK_sw087_s9_sensorType "Parking assist sensors: sw087 s9 sensor type; raw 3 = signal not available (SNA)";
CM_ SG_ 1486 PARK_sw087_s10_sensorType "Parking assist sensors: sw087 s10 sensor type; raw 3 = signal not available (SNA)";
CM_ SG_ 1486 PARK_sw087_s11_sensorType "Parking assist sensors: sw087 s11 sensor type; raw 3 = signal not available (SNA)";
CM_ SG_ 1486 PARK_sw087_s12_sensorType "Parking assist sensors: sw087 s12 sensor type; raw 3 = signal not available (SNA)";
CM_ BO_ 806 "Parking assist sensors message: info; frame length from the layout, not yet observed on a vehicle bus";
CM_ SG_ 806 PARK_infoIndex "Parking assist sensors: info index";
CM_ SG_ 806 PARK_infoBuildType "Parking assist sensors: info build type";
CM_ SG_ 806 PARK_infoComponentID "Parking assist sensors: info component ID";
CM_ SG_ 806 PARK_infoPcbaID "Parking assist sensors: info pcba ID";
CM_ SG_ 806 PARK_infoAssemblyID "Parking assist sensors: info assembly ID";
CM_ SG_ 806 PARK_infoUsageID "Parking assist sensors: info usage ID";
CM_ SG_ 806 PARK_infoApplicationCRC "Parking assist sensors: info application CRC";
CM_ SG_ 806 PARK_infoBootUdsProtoVersion "Parking assist sensors: info boot uds proto version";
CM_ SG_ 806 PARK_infoBootloaderCRC "Parking assist sensors: info bootloader CRC";
CM_ BO_ 846 "Parking assist sensors message: pas front middle; frame length from the layout, not yet observed on a vehicle bus";
CM_ SG_ 846 PARK_frontLeftMiddleRawDistData "Zone defined as -38 degrees -> +12 degrees, distance to object in units of centimeters; raw 255 = signal not available (SNA)";
CM_ SG_ 846 PARK_frontMiddleRawDistData "Zone defined as -12 degrees to +12 degrees, distance to object in units of centimeters; raw 255 = signal not available (SNA)";
CM_ SG_ 846 PARK_frontRightMiddleRawDistData "Zone defined +12 degrees to +38 degreees, distance to object in units of centimeters; raw 255 = signal not available (SNA)";
CM_ SG_ 846 PARK_pasFrontMiddleCounter "Parking assist sensors: pas front middle counter";
CM_ SG_ 846 PARK_pasFrontMiddleChecksum "Parking assist sensors: pas front middle checksum";
CM_ BO_ 862 "Parking assist sensors message: pas rear middle; frame length from the layout, not yet observed on a vehicle bus";
CM_ SG_ 862 PARK_rearLeftMiddleRawDistData "Zone defined as -124 degrees to -166 degrees, distance to object in units of centimeters; raw 255 = signal not available (SNA)";
CM_ SG_ 862 PARK_rearMiddleRawDistData "Zone defined as -166 degrees to +166 degrees, distance to object in units of centimeters; raw 255 = signal not available (SNA)";
CM_ SG_ 862 PARK_rearRightMiddleRawDistData "Zone defined as +166 degrees to +124 degrees, distance to object in units of centimeters; raw 255 = signal not available (SNA)";
CM_ SG_ 862 PARK_pasRearMiddleCounter "Parking assist sensors: pas rear middle counter";
CM_ SG_ 862 PARK_pasRearMiddleChecksum "Parking assist sensors: pas rear middle checksum";
CM_ BO_ 926 "Parking assist sensors message: pas sides; frame length from the layout, not yet observed on a vehicle bus";
CM_ SG_ 926 PARK_rightSideFrontRawDistData "Right side (from inside the car) towards the front of the car (split evenly between axles); raw 255 = signal not available (SNA)";
CM_ SG_ 926 PARK_rightSideRearRawDistData "Right side (from inside the car) towards the rear of the car (split evenly between axles); raw 255 = signal not available (SNA)";
CM_ SG_ 926 PARK_leftSideFrontRawDistData "Left side (from inside the car) towards the front of the car (split evenly between axles); raw 255 = signal not available (SNA)";
CM_ SG_ 926 PARK_leftSideRearRawDistData "Left side (from inside the car) towards the rear of the car (split evenly between axles); raw 255 = signal not available (SNA)";
CM_ SG_ 926 PARK_pasSidesCounter "Parking assist sensors: pas sides counter";
CM_ SG_ 926 PARK_pasSidesChecksum "Parking assist sensors: pas sides checksum";
CM_ BO_ 606 "Parking assist sensors message: psc env slot; frame length from the layout, not yet observed on a vehicle bus";
CM_ SG_ 606 PARK_pscEnvSlotType "Parking assist sensors: psc env slot type";
CM_ SG_ 606 PARK_pscLeftParallelObj1X "Parking assist sensors: psc left parallel obj1 x; raw 2047 = signal not available (SNA)";
CM_ SG_ 606 PARK_pscLeftParallelObj1Y "Parking assist sensors: psc left parallel obj1 y; raw 2047 = signal not available (SNA)";
CM_ SG_ 606 PARK_pscLeftParallelObj1Alpha "Parking assist sensors: psc left parallel obj1 alpha; raw 127 = signal not available (SNA)";
CM_ SG_ 606 PARK_pscLeftParallelObj2Y "Parking assist sensors: psc left parallel obj2 y; raw 2047 = signal not available (SNA)";
CM_ SG_ 606 PARK_pscLeftParallelObj2X "Parking assist sensors: psc left parallel obj2 x; raw 2047 = signal not available (SNA)";
CM_ SG_ 606 PARK_pscLeftParallelObj2Alpha "Parking assist sensors: psc left parallel obj2 alpha; raw 127 = signal not available (SNA)";
CM_ SG_ 606 PARK_pscLeftCrossObj1X "Parking assist sensors: psc left cross obj1 x; raw 2047 = signal not available (SNA)";
CM_ SG_ 606 PARK_pscLeftCrossObj1Y "Parking assist sensors: psc left cross obj1 y; raw 2047 = signal not available (SNA)";
CM_ SG_ 606 PARK_pscLeftCrossObj1Alpha "Parking assist sensors: psc left cross obj1 alpha; raw 127 = signal not available (SNA)";
CM_ SG_ 606 PARK_pscLeftCrossObj2Y "Parking assist sensors: psc left cross obj2 y; raw 2047 = signal not available (SNA)";
CM_ SG_ 606 PARK_pscLeftCrossObj2X "Parking assist sensors: psc left cross obj2 x; raw 2047 = signal not available (SNA)";
CM_ SG_ 606 PARK_pscLeftCrossObj2Alpha "Parking assist sensors: psc left cross obj2 alpha; raw 127 = signal not available (SNA)";
CM_ SG_ 606 PARK_pscRightParallelObj1X "Parking assist sensors: psc right parallel obj1 x; raw 2047 = signal not available (SNA)";
CM_ SG_ 606 PARK_pscRightParallelObj1Y "Parking assist sensors: psc right parallel obj1 y; raw 2047 = signal not available (SNA)";
CM_ SG_ 606 PARK_pscRightParallelObj1Alpha "Parking assist sensors: psc right parallel obj1 alpha; raw 127 = signal not available (SNA)";
CM_ SG_ 606 PARK_pscRightParallelObj2Y "Parking assist sensors: psc right parallel obj2 y; raw 2047 = signal not available (SNA)";
CM_ SG_ 606 PARK_pscRightParallelObj2X "Parking assist sensors: psc right parallel obj2 x; raw 2047 = signal not available (SNA)";
CM_ SG_ 606 PARK_pscRightParallelObj2Alpha "Parking assist sensors: psc right parallel obj2 alpha; raw 127 = signal not available (SNA)";
CM_ SG_ 606 PARK_pscRightCrossObj1X "Parking assist sensors: psc right cross obj1 x; raw 2047 = signal not available (SNA)";
CM_ SG_ 606 PARK_pscRightCrossObj1Y "Parking assist sensors: psc right cross obj1 y; raw 2047 = signal not available (SNA)";
CM_ SG_ 606 PARK_pscRightCrossObj1Alpha "Parking assist sensors: psc right cross obj1 alpha; raw 127 = signal not available (SNA)";
CM_ SG_ 606 PARK_pscRightCrossObj2Y "Parking assist sensors: psc right cross obj2 y; raw 2047 = signal not available (SNA)";
CM_ SG_ 606 PARK_pscRightCrossObj2X "Parking assist sensors: psc right cross obj2 x; raw 2047 = signal not available (SNA)";
CM_ SG_ 606 PARK_pscRightCrossObj2Alpha "Parking assist sensors: psc right cross obj2 alpha; raw 127 = signal not available (SNA)";
CM_ BO_ 542 "Parking assist sensors message: psc status; frame length from the layout, not yet observed on a vehicle bus";
CM_ SG_ 542 PARK_pscParkStatus "Parking assist sensors: psc park status; raw 7 = signal not available (SNA)";
CM_ SG_ 542 PARK_pscParkAbortReason "Parking assist sensors: psc park abort reason; raw 31 = signal not available (SNA)";
CM_ SG_ 542 PARK_pscParallelSpace "The existence and type of a parallel parking slot identified by the ultrasonics.";
CM_ SG_ 542 PARK_pscCrossSpace "The type and existence of perpendicular parking slot identified through the ultrasonics";
CM_ SG_ 542 PARK_pscParallelRightParkable "Whether or not there is a valid path into a parallel parking slot on the right; raw 3 = signal not available (SNA)";
CM_ SG_ 542 PARK_pscParallelLeftParkable "Whether or not there is a valid path into a parallel parking slot on the left; raw 3 = signal not available (SNA)";
CM_ SG_ 542 PARK_pscCrossRightParkable "Parking assist sensors: psc cross right parkable; raw 3 = signal not available (SNA)";
CM_ SG_ 542 PARK_pscMaxVelocity "Parking assist sensors: psc max velocity; raw 63 = signal not available (SNA)";
CM_ SG_ 542 PARK_pscCrossLeftParkable "Parking assist sensors: psc cross left parkable; raw 3 = signal not available (SNA)";
CM_ SG_ 542 PARK_pscParkInstruction "The control request from PARK ECU during autopark manuever; raw 7 = signal not available (SNA)";
CM_ SG_ 542 PARK_pscManeuverDistance "Real time updated path length from center of vehicle reference frame to desired center of vehicle at end of current parking manuever; raw 2047 = signal not available (SNA)";
CM_ SG_ 542 PARK_pscAngleActive "Parking assist sensors: psc angle active";
CM_ SG_ 542 PARK_pscAngleRequest "Parking assist sensors: psc angle request";
CM_ SG_ 542 PARK_pscStatusCounter "Parking assist sensors: psc status counter";
CM_ SG_ 542 PARK_pscStatusChecksum "Parking assist sensors: psc status checksum";
CM_ BO_ 590 "Parking assist sensors message: psc veh slot; frame length from the layout, not yet observed on a vehicle bus";
CM_ SG_ 590 PARK_pscVehSlotType "Parking assist sensors: psc veh slot type";
CM_ SG_ 590 PARK_pscLeftParallelVehX "Parking assist sensors: psc left parallel veh x; raw 2047 = signal not available (SNA)";
CM_ SG_ 590 PARK_pscLeftParallelVehY "Parking assist sensors: psc left parallel veh y; raw 2047 = signal not available (SNA)";
CM_ SG_ 590 PARK_pscLeftParallelPsi "Parking assist sensors: psc left parallel psi; raw 8191 = signal not available (SNA)";
CM_ SG_ 590 PARK_pscLeftParallelSizeX "Parking assist sensors: psc left parallel size x; raw 255 = signal not available (SNA)";
CM_ SG_ 590 PARK_pscLeftParallelSizeY "Parking assist sensors: psc left parallel size y; raw 255 = signal not available (SNA)";
CM_ SG_ 590 PARK_pscLeftCrossVehX "Parking assist sensors: psc left cross veh x; raw 2047 = signal not available (SNA)";
CM_ SG_ 590 PARK_pscLeftCrossVehY "Parking assist sensors: psc left cross veh y; raw 2047 = signal not available (SNA)";
CM_ SG_ 590 PARK_pscLeftCrossPsi "Parking assist sensors: psc left cross psi; raw 8191 = signal not available (SNA)";
CM_ SG_ 590 PARK_pscLeftCrossSizeX "Parking assist sensors: psc left cross size x; raw 255 = signal not available (SNA)";
CM_ SG_ 590 PARK_pscLeftCrossSizeY "Parking assist sensors: psc left cross size y; raw 255 = signal not available (SNA)";
CM_ SG_ 590 PARK_pscRightParallelVehX "Parking assist sensors: psc right parallel veh x; raw 2047 = signal not available (SNA)";
CM_ SG_ 590 PARK_pscRightParallelVehY "Parking assist sensors: psc right parallel veh y; raw 2047 = signal not available (SNA)";
CM_ SG_ 590 PARK_pscRightParallelPsi "Parking assist sensors: psc right parallel psi; raw 8191 = signal not available (SNA)";
CM_ SG_ 590 PARK_pscRightParallelSizeX "Parking assist sensors: psc right parallel size x; raw 255 = signal not available (SNA)";
CM_ SG_ 590 PARK_pscRightParallelSizeY "Parking assist sensors: psc right parallel size y; raw 255 = signal not available (SNA)";
CM_ SG_ 590 PARK_pscRightCrossVehX "Parking assist sensors: psc right cross veh x; raw 2047 = signal not available (SNA)";
CM_ SG_ 590 PARK_pscRightCrossVehY "Parking assist sensors: psc right cross veh y; raw 2047 = signal not available (SNA)";
CM_ SG_ 590 PARK_pscRightCrossPsi "Parking assist sensors: psc right cross psi; raw 8191 = signal not available (SNA)";
CM_ SG_ 590 PARK_pscRightCrossSizeX "Parking assist sensors: psc right cross size x; raw 255 = signal not available (SNA)";
CM_ SG_ 590 PARK_pscRightCrossSizeY "Parking assist sensors: psc right cross size y; raw 255 = signal not available (SNA)";
CM_ BO_ 526 "Parking assist sensors message: sdi front; frame length from the layout, not yet observed on a vehicle bus";
CM_ SG_ 526 PARK_sdiSensor1RawDistData "Parking assist sensors: sdi sensor1 raw dist data; raw 511 = signal not available (SNA)";
CM_ SG_ 526 PARK_sdiSensor2RawDistData "Parking assist sensors: sdi sensor2 raw dist data; raw 511 = signal not available (SNA)";
CM_ SG_ 526 PARK_sdiSensor3RawDistData "Parking assist sensors: sdi sensor3 raw dist data; raw 511 = signal not available (SNA)";
CM_ SG_ 526 PARK_sdiSensor4RawDistData "Parking assist sensors: sdi sensor4 raw dist data; raw 511 = signal not available (SNA)";
CM_ SG_ 526 PARK_sdiSensor5RawDistData "Parking assist sensors: sdi sensor5 raw dist data; raw 511 = signal not available (SNA)";
CM_ SG_ 526 PARK_sdiSensor6RawDistData "Parking assist sensors: sdi sensor6 raw dist data; raw 511 = signal not available (SNA)";
CM_ SG_ 526 PARK_sdiFrontCounter "Parking assist sensors: sdi front counter";
CM_ SG_ 526 PARK_sdiFrontChecksum "Parking assist sensors: sdi front checksum";
CM_ BO_ 558 "Parking assist sensors message: sdi rear; frame length from the layout, not yet observed on a vehicle bus";
CM_ SG_ 558 PARK_sdiSensor7RawDistData "Parking assist sensors: sdi sensor7 raw dist data; raw 511 = signal not available (SNA)";
CM_ SG_ 558 PARK_sdiSensor8RawDistData "Parking assist sensors: sdi sensor8 raw dist data; raw 511 = signal not available (SNA)";
CM_ SG_ 558 PARK_sdiSensor9RawDistData "Parking assist sensors: sdi sensor9 raw dist data; raw 511 = signal not available (SNA)";
CM_ SG_ 558 PARK_sdiSensor10RawDistData "Parking assist sensors: sdi sensor10 raw dist data; raw 511 = signal not available (SNA)";
CM_ SG_ 558 PARK_sdiSensor11RawDistData "Parking assist sensors: sdi sensor11 raw dist data; raw 511 = signal not available (SNA)";
CM_ SG_ 558 PARK_sdiSensor12RawDistData "Parking assist sensors: sdi sensor12 raw dist data; raw 511 = signal not available (SNA)";
CM_ SG_ 558 PARK_sdiRearCounter "Parking assist sensors: sdi rear counter";
CM_ SG_ 558 PARK_sdiRearChecksum "Parking assist sensors: sdi rear checksum";
CM_ BO_ 814 "Parking assist sensors message: sensor status front; frame length from the layout, not yet observed on a vehicle bus";
CM_ SG_ 814 PARK_frontRightSensorState "Reports the state of the front right ultrasonic sensor; raw 3 = signal not available (SNA)";
CM_ SG_ 814 PARK_frontRightMiddleSensorState "Reports the state of the front right middle ultrasonic sensor; raw 3 = signal not available (SNA)";
CM_ SG_ 814 PARK_frontLeftMiddleSensorState "Reports the state of the front left middle ultrasonic sensor; raw 3 = signal not available (SNA)";
CM_ SG_ 814 PARK_frontLeftSensorState "Reports the state of the front left ultrasonic sensor; raw 3 = signal not available (SNA)";
CM_ SG_ 814 PARK_frontLeftRawDistData "Zone defined as -90 degrees -> -38 degrees, distance to object in units of centimeters; raw 255 = signal not available (SNA)";
CM_ SG_ 814 PARK_frontRightRawDistData "Zone defined as +38 degrees -> +90 degrees, distance to object in units of centimeters; raw 255 = signal not available (SNA)";
CM_ SG_ 814 PARK_systemStatusFront "Parking assist sensors: system status front; raw 3 = signal not available (SNA)";
CM_ SG_ 814 PARK_frontDtcPresent "Parking assist sensors: front dtc present; raw 3 = signal not available (SNA)";
CM_ SG_ 814 PARK_sensorStatusFrontCounter "Parking assist sensors: sensor status front counter";
CM_ SG_ 814 PARK_sensorStatusFrontChecksum "Parking assist sensors: sensor status front checksum";
CM_ BO_ 830 "Parking assist sensors message: sensor status rear; frame length from the layout, not yet observed on a vehicle bus";
CM_ SG_ 830 PARK_rearRightSensorState "Reports the state of the rear right ultrasonic sensor; raw 3 = signal not available (SNA)";
CM_ SG_ 830 PARK_rearRightMiddleSensorState "Reports the state of the rear right middle ultrasonic sensor; raw 3 = signal not available (SNA)";
CM_ SG_ 830 PARK_rearLeftMiddleSensorState "Reports the state of the rear left middle ultrasonic sensor; raw 3 = signal not available (SNA)";
CM_ SG_ 830 PARK_rearLeftSensorState "Reports the state of the rear left ultrasonic sensor; raw 3 = signal not available (SNA)";
CM_ SG_ 830 PARK_rearLeftRawDistData "Zone defined as -90 degrees to -125 degrees, distance to object in units of centimeters; raw 255 = signal not available (SNA)";
CM_ SG_ 830 PARK_rearRightRawDistData "Zone defined as +125 degrees to +90 degrees, distance to object in units of centimeters; raw 255 = signal not available (SNA)";
CM_ SG_ 830 PARK_systemStatusRear "Parking assist sensors: system status rear; raw 3 = signal not available (SNA)";
CM_ SG_ 830 PARK_rearDtcPresent "Parking assist sensors: rear dtc present; raw 3 = signal not available (SNA)";
CM_ SG_ 830 PARK_sensorStatusRearCounter "Parking assist sensors: sensor status rear counter";
CM_ SG_ 830 PARK_sensorStatusRearChecksum "Parking assist sensors: sensor status rear checksum";
CM_ BO_ 798 "Parking assist sensors message: status; frame length from the layout, not yet observed on a vehicle bus";
CM_ SG_ 798 PARK_status "Indicates status of park assist function; raw 3 = signal not available (SNA)";
CM_ SG_ 798 PARK_serviceRequest "Indicates whether or not PARK sensors/ECU require service; raw 3 = signal not available (SNA)";
CM_ SG_ 798 PARK_systemDtcPresent "Boolean indicating whether or not there is a DTC present; raw 3 = signal not available (SNA)";
CM_ SG_ 798 PARK_statusCounter "Parking assist sensors: status counter";
CM_ SG_ 798 PARK_statusChecksum "Parking assist sensors: status checksum";
CM_ SG_ 798 PARK_majorVersion "Parking assist sensors: major version; raw 255 = signal not available (SNA)";
CM_ SG_ 798 PARK_minorVersion "Parking assist sensors: minor version; raw 255 = signal not available (SNA)";
CM_ SG_ 798 PARK_subMinorVersion "Parking assist sensors: sub minor version; raw 255 = signal not available (SNA)";
CM_ BO_ 782 "Parking assist sensors message: status2; frame length from the layout, not yet observed on a vehicle bus";
CM_ SG_ 782 PARK_frontSVACharID "Parking assist sensors: front SVA char ID";
CM_ SG_ 782 PARK_pscRightCurbType "The type of curb for the parallel parking slot on the right side.";
CM_ SG_ 782 PARK_rearSVACharID "Parking assist sensors: rear SVA char ID";
CM_ SG_ 782 PARK_pscLeftCurbType "The type of curb identified for a parallel parking space on the left.";
CM_ SG_ 782 PARK_autoCalComplete "Parking assist sensors: auto cal complete";
CM_ SG_ 782 PARK_geometryType "Parking assist sensors: geometry type";
CM_ SG_ 782 PARK_tireFitment "Parking assist sensors: tire fitment; raw 3 = signal not available (SNA)";
CM_ SG_ 782 PARK_rackDetected "Parking assist sensors: rack detected; raw 3 = signal not available (SNA)";
CM_ SG_ 782 PARK_sdiActive "Whether or not the raw sensor measurements from the ultrasonics are present and valid";
CM_ SG_ 782 PARK_sdiNoise "The output of the noise detection algorithm for raw sensor measurements, indicates if the measurements are degraded due to ambient noise; raw 3 = signal not available (SNA)";
CM_ SG_ 782 PARK_sdiBlindSpotRight "The output of the PARK ECU blindspot algorithm on the right side of the car, indicates the presence of a vehicle; raw 3 = signal not available (SNA)";
CM_ SG_ 782 PARK_sdiBlindSpotLeft "The output of the PARK ECU blindspot algorithm on the left side of the car, indicates the presence of a vehicle; raw 3 = signal not available (SNA)";
CM_ SG_ 782 PARK_sensorType "Parking assist sensors: sensor type; raw 3 = signal not available (SNA)";
CM_ SG_ 782 PARK_status2Counter "Parking assist sensors: status2 counter";
CM_ SG_ 782 PARK_status2Checksum "Parking assist sensors: status2 checksum";
CM_ BO_ 1630 "Parking assist sensors message: uds response; frame length from the layout, not yet observed on a vehicle bus";
CM_ SG_ 1630 PARK_udsResponseData "Parking assist sensors: uds response data";
CM_ BO_ 894 "Parking assist sensors message: warning matrix; frame length from the layout, not yet observed on a vehicle bus";
CM_ SG_ 894 PARK_matrixIndex "Parking assist sensors: matrix index";
CM_ SG_ 894 PARK_a001_s1_overTemp "Parking assist sensors: a001 s1 over temp";
CM_ SG_ 894 PARK_a002_s1_internalFail "Parking assist sensors: a002 s1 internal fail";
CM_ SG_ 894 PARK_a003_s1_linCommError "Parking assist sensors: a003 s1 lin comm error";
CM_ SG_ 894 PARK_a004_s1_blocked "Parking assist sensors: a004 s1 blocked";
CM_ SG_ 894 PARK_a005_s1_crossTalk "Parking assist sensors: a005 s1 cross talk";
CM_ SG_ 894 PARK_a006_s2_overTemp "Parking assist sensors: a006 s2 over temp";
CM_ SG_ 894 PARK_a007_s2_internalFail "Parking assist sensors: a007 s2 internal fail";
CM_ SG_ 894 PARK_a008_s2_linCommError "Parking assist sensors: a008 s2 lin comm error";
CM_ SG_ 894 PARK_a009_s2_blocked "Parking assist sensors: a009 s2 blocked";
CM_ SG_ 894 PARK_a010_s2_crossTalk "Parking assist sensors: a010 s2 cross talk";
CM_ SG_ 894 PARK_a011_s3_overTemp "Parking assist sensors: a011 s3 over temp";
CM_ SG_ 894 PARK_a012_s3_internalFail "Parking assist sensors: a012 s3 internal fail";
CM_ SG_ 894 PARK_a013_s3_linCommError "Parking assist sensors: a013 s3 lin comm error";
CM_ SG_ 894 PARK_a014_s3_blocked "Parking assist sensors: a014 s3 blocked";
CM_ SG_ 894 PARK_a015_s3_crossTalk "Parking assist sensors: a015 s3 cross talk";
CM_ SG_ 894 PARK_a016_s4_overTemp "Parking assist sensors: a016 s4 over temp";
CM_ SG_ 894 PARK_a017_s4_internalFail "Parking assist sensors: a017 s4 internal fail";
CM_ SG_ 894 PARK_a018_s4_linCommError "Parking assist sensors: a018 s4 lin comm error";
CM_ SG_ 894 PARK_a019_s4_blocked "Parking assist sensors: a019 s4 blocked";
CM_ SG_ 894 PARK_a020_s4_crossTalk "Parking assist sensors: a020 s4 cross talk";
CM_ SG_ 894 PARK_a021_s5_overTemp "Parking assist sensors: a021 s5 over temp";
CM_ SG_ 894 PARK_a022_s5_internalFail "Parking assist sensors: a022 s5 internal fail";
CM_ SG_ 894 PARK_a023_s5_linCommError "Parking assist sensors: a023 s5 lin comm error";
CM_ SG_ 894 PARK_a024_s5_blocked "Parking assist sensors: a024 s5 blocked";
CM_ SG_ 894 PARK_a025_s5_crossTalk "Parking assist sensors: a025 s5 cross talk";
CM_ SG_ 894 PARK_a026_s6_overTemp "Parking assist sensors: a026 s6 over temp";
CM_ SG_ 894 PARK_a027_s6_internalFail "Parking assist sensors: a027 s6 internal fail";
CM_ SG_ 894 PARK_a028_s6_linCommError "Parking assist sensors: a028 s6 lin comm error";
CM_ SG_ 894 PARK_a029_s6_blocked "Parking assist sensors: a029 s6 blocked";
CM_ SG_ 894 PARK_a030_s6_crossTalk "Parking assist sensors: a030 s6 cross talk";
CM_ SG_ 894 PARK_a031_s7_overTemp "Parking assist sensors: a031 s7 over temp";
CM_ SG_ 894 PARK_a032_s7_internalFail "Parking assist sensors: a032 s7 internal fail";
CM_ SG_ 894 PARK_a033_s7_linCommError "Parking assist sensors: a033 s7 lin comm error";
CM_ SG_ 894 PARK_a034_s7_blocked "Parking assist sensors: a034 s7 blocked";
CM_ SG_ 894 PARK_a035_s7_crossTalk "Parking assist sensors: a035 s7 cross talk";
CM_ SG_ 894 PARK_a036_s8_overTemp "Parking assist sensors: a036 s8 over temp";
CM_ SG_ 894 PARK_a037_s8_internalFail "Parking assist sensors: a037 s8 internal fail";
CM_ SG_ 894 PARK_a038_s8_linCommError "Parking assist sensors: a038 s8 lin comm error";
CM_ SG_ 894 PARK_a039_s8_blocked "Parking assist sensors: a039 s8 blocked";
CM_ SG_ 894 PARK_a040_s8_crossTalk "Parking assist sensors: a040 s8 cross talk";
CM_ SG_ 894 PARK_a041_s9_overTemp "Parking assist sensors: a041 s9 over temp";
CM_ SG_ 894 PARK_a042_s9_internalFail "Parking assist sensors: a042 s9 internal fail";
CM_ SG_ 894 PARK_a043_s9_linCommError "Parking assist sensors: a043 s9 lin comm error";
CM_ SG_ 894 PARK_a044_s9_blocked "Parking assist sensors: a044 s9 blocked";
CM_ SG_ 894 PARK_a045_s9_crossTalk "Parking assist sensors: a045 s9 cross talk";
CM_ SG_ 894 PARK_a046_s10_overTemp "Parking assist sensors: a046 s10 over temp";
CM_ SG_ 894 PARK_a047_s10_internalFail "Parking assist sensors: a047 s10 internal fail";
CM_ SG_ 894 PARK_a048_s10_linCommError "Parking assist sensors: a048 s10 lin comm error";
CM_ SG_ 894 PARK_a049_s10_blocked "Parking assist sensors: a049 s10 blocked";
CM_ SG_ 894 PARK_a050_s10_crossTalk "Parking assist sensors: a050 s10 cross talk";
CM_ SG_ 894 PARK_a051_s11_overTemp "Parking assist sensors: a051 s11 over temp";
CM_ SG_ 894 PARK_a052_s11_internalFail "Parking assist sensors: a052 s11 internal fail";
CM_ SG_ 894 PARK_a053_s11_linCommError "Parking assist sensors: a053 s11 lin comm error";
CM_ SG_ 894 PARK_a054_s11_blocked "Parking assist sensors: a054 s11 blocked";
CM_ SG_ 894 PARK_a055_s11_crossTalk "Parking assist sensors: a055 s11 cross talk";
CM_ SG_ 894 PARK_a056_s12_overTemp "Parking assist sensors: a056 s12 over temp";
CM_ SG_ 894 PARK_a057_s12_internalFail "Parking assist sensors: a057 s12 internal fail";
CM_ SG_ 894 PARK_a058_s12_linCommError "Parking assist sensors: a058 s12 lin comm error";
CM_ SG_ 894 PARK_a059_s12_blocked "Parking assist sensors: a059 s12 blocked";
CM_ SG_ 894 PARK_a060_s12_crossTalk "Parking assist sensors: a060 s12 cross talk";
CM_ SG_ 894 PARK_a061_ecuUnderVoltage "Parking assist sensors: a061 ecu under voltage";
CM_ SG_ 894 PARK_a062_ecuOverVoltage "Parking assist sensors: a062 ecu over voltage";
CM_ SG_ 894 PARK_a063_sensorVoltage "Parking assist sensors: a063 sensor voltage";
CM_ SG_ 894 PARK_a064_ecuFault "Parking assist sensors: a064 ecu fault";
CM_ SG_ 894 PARK_a065_crcFault "Parking assist sensors: a065 crc fault";
CM_ SG_ 894 PARK_a066_calibrationMissing "Parking assist sensors: a066 calibration missing";
CM_ SG_ 894 PARK_a067_privateCANBusOff "Parking assist sensors: a067 private CAN bus off";
CM_ SG_ 894 PARK_a068_hardwareWatchDog "Parking assist sensors: a068 hardware watch dog";
CM_ SG_ 894 PARK_a069_dasMia "Parking assist sensors: a069 das mia";
CM_ SG_ 894 PARK_a070_sccmMia "Parking assist sensors: a070 sccm mia";
CM_ SG_ 894 PARK_a071_diMia "Parking assist sensors: a071 di mia";
CM_ SG_ 894 PARK_a072_epasMia "Parking assist sensors: a072 epas mia";
CM_ SG_ 894 PARK_a073_epbMia "Parking assist sensors: a073 epb mia";
CM_ SG_ 894 PARK_a074_espMia "Parking assist sensors: a074 esp mia";
CM_ SG_ 894 PARK_a075_rcmMia "Parking assist sensors: a075 rcm mia";
CM_ SG_ 894 PARK_a076_vcFrontMia "Parking assist sensors: a076 vc front mia";
CM_ SG_ 894 PARK_a077_dasError "Parking assist sensors: a077 das error";
CM_ SG_ 894 PARK_a078_diError "Parking assist sensors: a078 di error";
CM_ SG_ 894 PARK_a079_epasError "Parking assist sensors: a079 epas error";
CM_ SG_ 894 PARK_a080_epbError "Parking assist sensors: a080 epb error";
CM_ SG_ 894 PARK_a081_espError "Parking assist sensors: a081 esp error";
CM_ SG_ 894 PARK_a082_rcmError "Parking assist sensors: a082 rcm error";
CM_ SG_ 894 PARK_a083_vcFrontError "Parking assist sensors: a083 vc front error";
CM_ SG_ 894 PARK_a084_sccmError "Parking assist sensors: a084 sccm error";
CM_ SG_ 894 PARK_a085_watchdogReset "Parking assist sensors: a085 watchdog reset";
CM_ SG_ 894 PARK_a086_nvmFault "Parking assist sensors: a086 nvm fault";
CM_ SG_ 894 PARK_a087_sensorMismatchError "Parking assist sensors: a087 sensor mismatch error";
BA_DEF_ BO_ "GenMsgCycleTime" INT 0 3600000;
BA_DEF_ BO_ "GenMsgSendType" ENUM "Cyclic","NotUsed","NotUsed","NotUsed","NotUsed","NotUsed","NotUsed","IfActive","NoMsgSendType","NotUsed";
BA_DEF_ BO_ "VFrameFormat" ENUM "StandardCAN","ExtendedCAN","reserved","J1939PG","reserved","reserved","reserved","reserved","reserved","reserved","reserved","reserved","reserved","reserved","StandardCAN_FD","ExtendedCAN_FD";
BA_DEF_ BO_ "CANFD_BRS" ENUM "0","1";
BA_DEF_ SG_ "GenSigSNA" STRING;
BA_DEF_ SG_ "SystemSignalLongSymbol" STRING;
BA_DEF_ SG_ "Confidence" ENUM "validated","plausible","layout-only","contradicted";
BA_DEF_DEF_ "GenMsgCycleTime" 0;
BA_DEF_DEF_ "GenMsgSendType" "NoMsgSendType";
BA_DEF_DEF_ "VFrameFormat" "StandardCAN";
BA_DEF_DEF_ "CANFD_BRS" "1";
BA_DEF_DEF_ "GenSigSNA" "";
BA_DEF_DEF_ "SystemSignalLongSymbol" "";
BA_DEF_DEF_ "Confidence" "layout-only";
BA_ "GenMsgCycleTime" BO_ 983 1000;
BA_ "GenMsgSendType" BO_ 983 0;
BA_ "GenMsgCycleTime" BO_ 828 10000;
BA_ "GenMsgSendType" BO_ 828 0;
BA_ "GenMsgCycleTime" BO_ 806 1000;
BA_ "GenMsgSendType" BO_ 806 0;
BA_ "GenMsgCycleTime" BO_ 846 100;
BA_ "GenMsgSendType" BO_ 846 0;
BA_ "GenMsgCycleTime" BO_ 862 100;
BA_ "GenMsgSendType" BO_ 862 0;
BA_ "GenMsgCycleTime" BO_ 926 100;
BA_ "GenMsgSendType" BO_ 926 0;
BA_ "GenMsgCycleTime" BO_ 606 100;
BA_ "GenMsgSendType" BO_ 606 0;
BA_ "GenMsgCycleTime" BO_ 542 40;
BA_ "GenMsgSendType" BO_ 542 0;
BA_ "GenMsgCycleTime" BO_ 590 100;
BA_ "GenMsgSendType" BO_ 590 0;
BA_ "GenMsgCycleTime" BO_ 526 40;
BA_ "GenMsgSendType" BO_ 526 0;
BA_ "GenMsgCycleTime" BO_ 558 40;
BA_ "GenMsgSendType" BO_ 558 0;
BA_ "GenMsgCycleTime" BO_ 814 100;
BA_ "GenMsgSendType" BO_ 814 0;
BA_ "GenMsgCycleTime" BO_ 830 100;
BA_ "GenMsgSendType" BO_ 830 0;
BA_ "GenMsgCycleTime" BO_ 798 500;
BA_ "GenMsgSendType" BO_ 798 0;
BA_ "GenMsgCycleTime" BO_ 782 250;
BA_ "GenMsgSendType" BO_ 782 0;
BA_ "GenMsgCycleTime" BO_ 894 1000;
BA_ "GenMsgSendType" BO_ 894 0;
BA_ "Confidence" SG_ 1470 IDB_alertID 1;
BA_ "Confidence" SG_ 1470 IDB_alertState 1;
BA_ "Confidence" SG_ 1470 IDB_a014_wheelSpeedSensorFreq 1;
BA_ "Confidence" SG_ 1470 IDB_a014_wheelSpeedSensorPhase 1;
BA_ "Confidence" SG_ 1470 IDB_a014_wheelSpeedSensorMisinst 1;
BA_ "SystemSignalLongSymbol" SG_ 1470 IDB_a014_wheelSpeedSensorMisinst "IDB_a014_wheelSpeedSensorMisinstallation";
BA_ "Confidence" SG_ 1470 IDB_a014_wheelSpeedSensorWrongEx 1;
BA_ "SystemSignalLongSymbol" SG_ 1470 IDB_a014_wheelSpeedSensorWrongEx "IDB_a014_wheelSpeedSensorWrongExciter";
BA_ "Confidence" SG_ 1470 IDB_a014_wheelSpeedSensorSpeedJu 1;
BA_ "SystemSignalLongSymbol" SG_ 1470 IDB_a014_wheelSpeedSensorSpeedJu "IDB_a014_wheelSpeedSensorSpeedJumpMinus";
BA_ "Confidence" SG_ 1470 IDB_a014_wheelSpeedSensorSp_0001 1;
BA_ "SystemSignalLongSymbol" SG_ 1470 IDB_a014_wheelSpeedSensorSp_0001 "IDB_a014_wheelSpeedSensorSpeedJumpPlus";
BA_ "Confidence" SG_ 1470 IDB_a014_wheelSpeedSensorAirGap 1;
BA_ "Confidence" SG_ 1470 IDB_a014_wheelSpeedSensorBIST 1;
BA_ "Confidence" SG_ 1470 IDB_a014_wheelSpeedSensorLeakage 1;
BA_ "SystemSignalLongSymbol" SG_ 1470 IDB_a014_wheelSpeedSensorLeakage "IDB_a014_wheelSpeedSensorLeakageCur";
BA_ "Confidence" SG_ 1470 IDB_a014_wheelSpeedSensorOverTem 1;
BA_ "SystemSignalLongSymbol" SG_ 1470 IDB_a014_wheelSpeedSensorOverTem "IDB_a014_wheelSpeedSensorOverTemp";
BA_ "Confidence" SG_ 1470 IDB_a014_wheelSpeedSensorSh_0001 1;
BA_ "SystemSignalLongSymbol" SG_ 1470 IDB_a014_wheelSpeedSensorSh_0001 "IDB_a014_wheelSpeedSensorShortToGnd";
BA_ "Confidence" SG_ 1470 IDB_a014_wheelSpeedSensorShortTo 1;
BA_ "SystemSignalLongSymbol" SG_ 1470 IDB_a014_wheelSpeedSensorShortTo "IDB_a014_wheelSpeedSensorShortToBat";
BA_ "Confidence" SG_ 1470 IDB_a014_wheelSpeedSensorOpen 1;
BA_ "Confidence" SG_ 1470 IDB_a015_wheelSpeedSensorFreq 1;
BA_ "Confidence" SG_ 1470 IDB_a015_wheelSpeedSensorPhase 1;
BA_ "Confidence" SG_ 1470 IDB_a015_wheelSpeedSensorMisinst 1;
BA_ "SystemSignalLongSymbol" SG_ 1470 IDB_a015_wheelSpeedSensorMisinst "IDB_a015_wheelSpeedSensorMisinstallation";
BA_ "Confidence" SG_ 1470 IDB_a015_wheelSpeedSensorWrongEx 1;
BA_ "SystemSignalLongSymbol" SG_ 1470 IDB_a015_wheelSpeedSensorWrongEx "IDB_a015_wheelSpeedSensorWrongExciter";
BA_ "Confidence" SG_ 1470 IDB_a015_wheelSpeedSensorSpeedJu 1;
BA_ "SystemSignalLongSymbol" SG_ 1470 IDB_a015_wheelSpeedSensorSpeedJu "IDB_a015_wheelSpeedSensorSpeedJumpMinus";
BA_ "Confidence" SG_ 1470 IDB_a015_wheelSpeedSensorSp_0001 1;
BA_ "SystemSignalLongSymbol" SG_ 1470 IDB_a015_wheelSpeedSensorSp_0001 "IDB_a015_wheelSpeedSensorSpeedJumpPlus";
BA_ "Confidence" SG_ 1470 IDB_a015_wheelSpeedSensorAirGap 1;
BA_ "Confidence" SG_ 1470 IDB_a015_wheelSpeedSensorBIST 1;
BA_ "Confidence" SG_ 1470 IDB_a015_wheelSpeedSensorLeakage 1;
BA_ "SystemSignalLongSymbol" SG_ 1470 IDB_a015_wheelSpeedSensorLeakage "IDB_a015_wheelSpeedSensorLeakageCur";
BA_ "Confidence" SG_ 1470 IDB_a015_wheelSpeedSensorOverTem 1;
BA_ "SystemSignalLongSymbol" SG_ 1470 IDB_a015_wheelSpeedSensorOverTem "IDB_a015_wheelSpeedSensorOverTemp";
BA_ "Confidence" SG_ 1470 IDB_a015_wheelSpeedSensorSh_0001 1;
BA_ "SystemSignalLongSymbol" SG_ 1470 IDB_a015_wheelSpeedSensorSh_0001 "IDB_a015_wheelSpeedSensorShortToGnd";
BA_ "Confidence" SG_ 1470 IDB_a015_wheelSpeedSensorShortTo 1;
BA_ "SystemSignalLongSymbol" SG_ 1470 IDB_a015_wheelSpeedSensorShortTo "IDB_a015_wheelSpeedSensorShortToBat";
BA_ "Confidence" SG_ 1470 IDB_a015_wheelSpeedSensorOpen 1;
BA_ "Confidence" SG_ 1470 IDB_a016_wheelSpeedSensorFreq 1;
BA_ "Confidence" SG_ 1470 IDB_a016_wheelSpeedSensorPhase 1;
BA_ "Confidence" SG_ 1470 IDB_a016_wheelSpeedSensorMisinst 1;
BA_ "SystemSignalLongSymbol" SG_ 1470 IDB_a016_wheelSpeedSensorMisinst "IDB_a016_wheelSpeedSensorMisinstallation";
BA_ "Confidence" SG_ 1470 IDB_a016_wheelSpeedSensorWrongEx 1;
BA_ "SystemSignalLongSymbol" SG_ 1470 IDB_a016_wheelSpeedSensorWrongEx "IDB_a016_wheelSpeedSensorWrongExciter";
BA_ "Confidence" SG_ 1470 IDB_a016_wheelSpeedSensorSpeedJu 1;
BA_ "SystemSignalLongSymbol" SG_ 1470 IDB_a016_wheelSpeedSensorSpeedJu "IDB_a016_wheelSpeedSensorSpeedJumpMinus";
BA_ "Confidence" SG_ 1470 IDB_a016_wheelSpeedSensorSp_0001 1;
BA_ "SystemSignalLongSymbol" SG_ 1470 IDB_a016_wheelSpeedSensorSp_0001 "IDB_a016_wheelSpeedSensorSpeedJumpPlus";
BA_ "Confidence" SG_ 1470 IDB_a016_wheelSpeedSensorAirGap 1;
BA_ "Confidence" SG_ 1470 IDB_a016_wheelSpeedSensorBIST 1;
BA_ "Confidence" SG_ 1470 IDB_a016_wheelSpeedSensorLeakage 1;
BA_ "SystemSignalLongSymbol" SG_ 1470 IDB_a016_wheelSpeedSensorLeakage "IDB_a016_wheelSpeedSensorLeakageCur";
BA_ "Confidence" SG_ 1470 IDB_a016_wheelSpeedSensorOverTem 1;
BA_ "SystemSignalLongSymbol" SG_ 1470 IDB_a016_wheelSpeedSensorOverTem "IDB_a016_wheelSpeedSensorOverTemp";
BA_ "Confidence" SG_ 1470 IDB_a016_wheelSpeedSensorSh_0001 1;
BA_ "SystemSignalLongSymbol" SG_ 1470 IDB_a016_wheelSpeedSensorSh_0001 "IDB_a016_wheelSpeedSensorShortToGnd";
BA_ "Confidence" SG_ 1470 IDB_a016_wheelSpeedSensorShortTo 1;
BA_ "SystemSignalLongSymbol" SG_ 1470 IDB_a016_wheelSpeedSensorShortTo "IDB_a016_wheelSpeedSensorShortToBat";
BA_ "Confidence" SG_ 1470 IDB_a016_wheelSpeedSensorOpen 1;
BA_ "Confidence" SG_ 1470 IDB_a017_wheelSpeedSensorFreq 1;
BA_ "Confidence" SG_ 1470 IDB_a017_wheelSpeedSensorPhase 1;
BA_ "Confidence" SG_ 1470 IDB_a017_wheelSpeedSensorMisinst 1;
BA_ "SystemSignalLongSymbol" SG_ 1470 IDB_a017_wheelSpeedSensorMisinst "IDB_a017_wheelSpeedSensorMisinstallation";
BA_ "Confidence" SG_ 1470 IDB_a017_wheelSpeedSensorWrongEx 1;
BA_ "SystemSignalLongSymbol" SG_ 1470 IDB_a017_wheelSpeedSensorWrongEx "IDB_a017_wheelSpeedSensorWrongExciter";
BA_ "Confidence" SG_ 1470 IDB_a017_wheelSpeedSensorSpeedJu 1;
BA_ "SystemSignalLongSymbol" SG_ 1470 IDB_a017_wheelSpeedSensorSpeedJu "IDB_a017_wheelSpeedSensorSpeedJumpMinus";
BA_ "Confidence" SG_ 1470 IDB_a017_wheelSpeedSensorSp_0001 1;
BA_ "SystemSignalLongSymbol" SG_ 1470 IDB_a017_wheelSpeedSensorSp_0001 "IDB_a017_wheelSpeedSensorSpeedJumpPlus";
BA_ "Confidence" SG_ 1470 IDB_a017_wheelSpeedSensorAirGap 1;
BA_ "Confidence" SG_ 1470 IDB_a017_wheelSpeedSensorBIST 1;
BA_ "Confidence" SG_ 1470 IDB_a017_wheelSpeedSensorLeakage 1;
BA_ "SystemSignalLongSymbol" SG_ 1470 IDB_a017_wheelSpeedSensorLeakage "IDB_a017_wheelSpeedSensorLeakageCur";
BA_ "Confidence" SG_ 1470 IDB_a017_wheelSpeedSensorOverTem 1;
BA_ "SystemSignalLongSymbol" SG_ 1470 IDB_a017_wheelSpeedSensorOverTem "IDB_a017_wheelSpeedSensorOverTemp";
BA_ "Confidence" SG_ 1470 IDB_a017_wheelSpeedSensorSh_0001 1;
BA_ "SystemSignalLongSymbol" SG_ 1470 IDB_a017_wheelSpeedSensorSh_0001 "IDB_a017_wheelSpeedSensorShortToGnd";
BA_ "Confidence" SG_ 1470 IDB_a017_wheelSpeedSensorShortTo 1;
BA_ "SystemSignalLongSymbol" SG_ 1470 IDB_a017_wheelSpeedSensorShortTo "IDB_a017_wheelSpeedSensorShortToBat";
BA_ "Confidence" SG_ 1470 IDB_a017_wheelSpeedSensorOpen 1;
BA_ "Confidence" SG_ 1470 IDB_a020_canSignalValidity 1;
BA_ "Confidence" SG_ 1470 IDB_a020_signalValueCrosscheck 1;
BA_ "Confidence" SG_ 1470 IDB_a030_primaryExternalCircuitL 1;
BA_ "SystemSignalLongSymbol" SG_ 1470 IDB_a030_primaryExternalCircuitL "IDB_a030_primaryExternalCircuitLeakage";
BA_ "Confidence" SG_ 1470 IDB_a030_secondaryExternalCircui 1;
BA_ "SystemSignalLongSymbol" SG_ 1470 IDB_a030_secondaryExternalCircui "IDB_a030_secondaryExternalCircuitLeakage";
BA_ "Confidence" SG_ 1470 IDB_a030_primaryChamberInternalL 1;
BA_ "SystemSignalLongSymbol" SG_ 1470 IDB_a030_primaryChamberInternalL "IDB_a030_primaryChamberInternalLeakage";
BA_ "Confidence" SG_ 1470 IDB_a030_syncModeInternalLeakage 1;
BA_ "Confidence" SG_ 1470 IDB_a030_secondaryChamberInterna 1;
BA_ "SystemSignalLongSymbol" SG_ 1470 IDB_a030_secondaryChamberInterna "IDB_a030_secondaryChamberInternalLeakage";
BA_ "Confidence" SG_ 1470 IDB_a030_masterCylinderInternalL 1;
BA_ "SystemSignalLongSymbol" SG_ 1470 IDB_a030_masterCylinderInternalL "IDB_a030_masterCylinderInternalLeakage";
BA_ "Confidence" SG_ 1470 IDB_a060_validityOnChassisBus 1;
BA_ "Confidence" SG_ 1470 IDB_a060_validityOnPartyBus 1;
BA_ "Confidence" SG_ 1470 IDB_a061_validityOnChassisBus 1;
BA_ "Confidence" SG_ 1470 IDB_a061_validityOnPartyBus 1;
BA_ "Confidence" SG_ 1470 IDB_a063_validityOnChassisBus 1;
BA_ "Confidence" SG_ 1470 IDB_a063_validityOnPartyBus 1;
BA_ "Confidence" SG_ 1470 IDB_a064_validityOnChassisBus 1;
BA_ "Confidence" SG_ 1470 IDB_a064_validityOnPartyBus 1;
BA_ "Confidence" SG_ 1470 IDB_a065_validityOnChassisBus 1;
BA_ "Confidence" SG_ 1470 IDB_a065_validityOnPartyBus 1;
BA_ "Confidence" SG_ 1470 IDB_a106_qualifierValidity 1;
BA_ "Confidence" SG_ 1470 IDB_a106_signalNotAvailable 1;
BA_ "Confidence" SG_ 1470 IDB_a107_qualifierValidity 1;
BA_ "Confidence" SG_ 1470 IDB_a107_signalNotAvailable 1;
BA_ "Confidence" SG_ 1470 IDB_a112_qualifierValidity 1;
BA_ "Confidence" SG_ 1470 IDB_a112_signalNotAvailable 1;
BA_ "Confidence" SG_ 1470 IDB_a113_qualifierValidity 1;
BA_ "Confidence" SG_ 1470 IDB_a113_signalNotAvailable 1;
BA_ "Confidence" SG_ 1470 IDB_a114_qualifierValidity 1;
BA_ "Confidence" SG_ 1470 IDB_a114_signalNotAvailable 1;
BA_ "Confidence" SG_ 1470 IDB_a126_PMebrCmdStateValidity 1;
BA_ "Confidence" SG_ 1470 IDB_a126_PMstate2Validity 1;
BA_ "Confidence" SG_ 1470 IDB_a126_PMstate2Missing 1;
BA_ "Confidence" SG_ 1470 IDB_a126_DIchassisControlValidit 1;
BA_ "SystemSignalLongSymbol" SG_ 1470 IDB_a126_DIchassisControlValidit "IDB_a126_DIchassisControlValidity";
BA_ "Confidence" SG_ 1470 IDB_a126_DIchassisControlMissing 1;
BA_ "Confidence" SG_ 1470 IDB_a126_DIrequestActiveValidity 1;
BA_ "Confidence" SG_ 1470 IDB_a129_validityOnChassisBus 1;
BA_ "Confidence" SG_ 1470 IDB_a129_validityOnPartyBus 1;
BA_ "Confidence" SG_ 1470 IDB_a130_PMbrakePedalCmdQFValidi 1;
BA_ "SystemSignalLongSymbol" SG_ 1470 IDB_a130_PMbrakePedalCmdQFValidi "IDB_a130_PMbrakePedalCmdQFValidity";
BA_ "Confidence" SG_ 1470 IDB_a130_PMstate2Validity 1;
BA_ "Confidence" SG_ 1470 IDB_a130_PMstate2Missing 1;
BA_ "Confidence" SG_ 1470 IDB_a130_DIbrakeCommandValidity 1;
BA_ "Confidence" SG_ 1470 IDB_a130_DIbrakeCommandMissing 1;
BA_ "Confidence" SG_ 1470 IDB_a130_DIbrakeTorqueCommandFul 1;
BA_ "SystemSignalLongSymbol" SG_ 1470 IDB_a130_DIbrakeTorqueCommandFul "IDB_a130_DIbrakeTorqueCommandFullSNA";
BA_ "Confidence" SG_ 1470 IDB_a130_DIbrakeTorqueComma_0001 1;
BA_ "SystemSignalLongSymbol" SG_ 1470 IDB_a130_DIbrakeTorqueComma_0001 "IDB_a130_DIbrakeTorqueCommandFullTooLow";
BA_ "Confidence" SG_ 1470 IDB_a132_validityOnChassisBus 1;
BA_ "Confidence" SG_ 1470 IDB_a132_validityOnPartyBus 1;
BA_ "Confidence" SG_ 983 IDB_matrixIndex 1;
BA_ "SystemSignalLongSymbol" SG_ 983 IDB_a070_DIchassisControlChecksu "IDB_a070_DIchassisControlChecksum";
BA_ "SystemSignalLongSymbol" SG_ 983 IDB_a119_VCLEFTepbmStatusChecksu "IDB_a119_VCLEFTepbmStatusChecksum";
BA_ "SystemSignalLongSymbol" SG_ 983 IDB_a129_RCUinputRodStrokeInvali "IDB_a129_RCUinputRodStrokeInvalid";
BA_ "SystemSignalLongSymbol" SG_ 983 IDB_a130_DIfullTorqueRequestInva "IDB_a130_DIfullTorqueRequestInvalid";
BA_ "SystemSignalLongSymbol" SG_ 983 IDB_a132_RCUinputRodStrokeQFInva "IDB_a132_RCUinputRodStrokeQFInvalid";
BA_ "SystemSignalLongSymbol" SG_ 983 IDB_a138_DIbrakeTorqueCommandAnd "IDB_a138_DIbrakeTorqueCommandAndFlagMismatch";
BA_ "SystemSignalLongSymbol" SG_ 983 IDB_a139_DIbrakeTorqueCommandFul "IDB_a139_DIbrakeTorqueCommandFullSNA";
BA_ "SystemSignalLongSymbol" SG_ 983 IDB_a140_PMbrakePedalCmdQFInvali "IDB_a140_PMbrakePedalCmdQFInvalid";
BA_ "SystemSignalLongSymbol" SG_ 983 IDB_a141_DIbrakeTorqueCommandFul "IDB_a141_DIbrakeTorqueCommandFullTooLow";
BA_ "SystemSignalLongSymbol" SG_ 983 IDB_a144_hydraulicPushthroughAct "IDB_a144_hydraulicPushthroughActive";
BA_ "SystemSignalLongSymbol" SG_ 983 IDB_a145_DASredundantBrakingCont "IDB_a145_DASredundantBrakingControlDLC";
BA_ "SystemSignalLongSymbol" SG_ 983 IDB_a146_DASredundantBrakingCont "IDB_a146_DASredundantBrakingControlCounter";
BA_ "SystemSignalLongSymbol" SG_ 983 IDB_a147_DASredundantBrakingCont "IDB_a147_DASredundantBrakingControlChecksum";
BA_ "SystemSignalLongSymbol" SG_ 983 IDB_a148_DASbrakeTorqueCommandIn "IDB_a148_DASbrakeTorqueCommandInvalid";
BA_ "SystemSignalLongSymbol" SG_ 983 IDB_a149_DASmiaBrakeTorqueComman "IDB_a149_DASmiaBrakeTorqueCommandInvalid";
BA_ "Confidence" SG_ 828 IDB_infoIndex 1;
BA_ "Confidence" SG_ 828 IDB_infoPcbaID 0;
BA_ "Confidence" SG_ 828 IDB_infoAssemblyID 0;
BA_ "Confidence" SG_ 828 IDB_infoUsageID 0;
BA_ "Confidence" SG_ 828 IDB_infoSubUsageID 0;
BA_ "Confidence" SG_ 1486 PARK_alertID 1;
BA_ "Confidence" SG_ 1486 PARK_alertState 1;
BA_ "Confidence" SG_ 1486 PARK_sw001_sensorTemperature 1;
BA_ "SystemSignalLongSymbol" SG_ 1486 PARK_sw002_diagnosticTransferErr "PARK_sw002_diagnosticTransferError";
BA_ "Confidence" SG_ 1486 PARK_sw004_reverbPeriod 1;
BA_ "Confidence" SG_ 1486 PARK_sw004_reverbTime 1;
BA_ "Confidence" SG_ 1486 PARK_sw006_sensorTemperature 1;
BA_ "SystemSignalLongSymbol" SG_ 1486 PARK_sw007_diagnosticTransferErr "PARK_sw007_diagnosticTransferError";
BA_ "Confidence" SG_ 1486 PARK_sw009_reverbPeriod 1;
BA_ "Confidence" SG_ 1486 PARK_sw009_reverbTime 1;
BA_ "Confidence" SG_ 1486 PARK_sw011_sensorTemperature 1;
BA_ "SystemSignalLongSymbol" SG_ 1486 PARK_sw012_diagnosticTransferErr "PARK_sw012_diagnosticTransferError";
BA_ "Confidence" SG_ 1486 PARK_sw014_reverbPeriod 1;
BA_ "Confidence" SG_ 1486 PARK_sw014_reverbTime 1;
BA_ "Confidence" SG_ 1486 PARK_sw016_sensorTemperature 1;
BA_ "SystemSignalLongSymbol" SG_ 1486 PARK_sw017_diagnosticTransferErr "PARK_sw017_diagnosticTransferError";
BA_ "Confidence" SG_ 1486 PARK_sw019_reverbPeriod 1;
BA_ "Confidence" SG_ 1486 PARK_sw019_reverbTime 1;
BA_ "Confidence" SG_ 1486 PARK_sw021_sensorTemperature 1;
BA_ "SystemSignalLongSymbol" SG_ 1486 PARK_sw022_diagnosticTransferErr "PARK_sw022_diagnosticTransferError";
BA_ "Confidence" SG_ 1486 PARK_sw024_reverbPeriod 1;
BA_ "Confidence" SG_ 1486 PARK_sw024_reverbTime 1;
BA_ "Confidence" SG_ 1486 PARK_sw026_sensorTemperature 1;
BA_ "SystemSignalLongSymbol" SG_ 1486 PARK_sw027_diagnosticTransferErr "PARK_sw027_diagnosticTransferError";
BA_ "Confidence" SG_ 1486 PARK_sw029_reverbPeriod 1;
BA_ "Confidence" SG_ 1486 PARK_sw029_reverbTime 1;
BA_ "Confidence" SG_ 1486 PARK_sw031_sensorTemperature 1;
BA_ "SystemSignalLongSymbol" SG_ 1486 PARK_sw032_diagnosticTransferErr "PARK_sw032_diagnosticTransferError";
BA_ "Confidence" SG_ 1486 PARK_sw034_reverbPeriod 1;
BA_ "Confidence" SG_ 1486 PARK_sw034_reverbTime 1;
BA_ "Confidence" SG_ 1486 PARK_sw036_sensorTemperature 1;
BA_ "SystemSignalLongSymbol" SG_ 1486 PARK_sw037_diagnosticTransferErr "PARK_sw037_diagnosticTransferError";
BA_ "Confidence" SG_ 1486 PARK_sw039_reverbPeriod 1;
BA_ "Confidence" SG_ 1486 PARK_sw039_reverbTime 1;
BA_ "Confidence" SG_ 1486 PARK_sw041_sensorTemperature 1;
BA_ "SystemSignalLongSymbol" SG_ 1486 PARK_sw042_diagnosticTransferErr "PARK_sw042_diagnosticTransferError";
BA_ "Confidence" SG_ 1486 PARK_sw044_reverbPeriod 1;
BA_ "Confidence" SG_ 1486 PARK_sw044_reverbTime 1;
BA_ "Confidence" SG_ 1486 PARK_sw046_sensorTemperature 1;
BA_ "SystemSignalLongSymbol" SG_ 1486 PARK_sw047_diagnosticTransferErr "PARK_sw047_diagnosticTransferError";
BA_ "Confidence" SG_ 1486 PARK_sw049_reverbPeriod 1;
BA_ "Confidence" SG_ 1486 PARK_sw049_reverbTime 1;
BA_ "Confidence" SG_ 1486 PARK_sw051_sensorTemperature 1;
BA_ "SystemSignalLongSymbol" SG_ 1486 PARK_sw052_diagnosticTransferErr "PARK_sw052_diagnosticTransferError";
BA_ "Confidence" SG_ 1486 PARK_sw054_reverbPeriod 1;
BA_ "Confidence" SG_ 1486 PARK_sw054_reverbTime 1;
BA_ "Confidence" SG_ 1486 PARK_sw056_sensorTemperature 1;
BA_ "SystemSignalLongSymbol" SG_ 1486 PARK_sw057_diagnosticTransferErr "PARK_sw057_diagnosticTransferError";
BA_ "Confidence" SG_ 1486 PARK_sw059_reverbPeriod 1;
BA_ "Confidence" SG_ 1486 PARK_sw059_reverbTime 1;
BA_ "Confidence" SG_ 1486 PARK_sw061_voltage 1;
BA_ "Confidence" SG_ 1486 PARK_sw063_voltage 1;
BA_ "Confidence" SG_ 1486 PARK_sw077_errorType 1;
BA_ "Confidence" SG_ 1486 PARK_sw078_errorType 1;
BA_ "Confidence" SG_ 1486 PARK_sw079_errorType 1;
BA_ "Confidence" SG_ 1486 PARK_sw080_errorType 1;
BA_ "Confidence" SG_ 1486 PARK_sw081_errorType 1;
BA_ "Confidence" SG_ 1486 PARK_sw082_errorType 1;
BA_ "Confidence" SG_ 1486 PARK_sw083_errorType 1;
BA_ "Confidence" SG_ 1486 PARK_sw084_errorType 1;
BA_ "Confidence" SG_ 1486 PARK_sw087_s1_sensorType 1;
BA_ "GenSigSNA" SG_ 1486 PARK_sw087_s1_sensorType "3";
BA_ "Confidence" SG_ 1486 PARK_sw087_s2_sensorType 1;
BA_ "GenSigSNA" SG_ 1486 PARK_sw087_s2_sensorType "3";
BA_ "Confidence" SG_ 1486 PARK_sw087_s3_sensorType 1;
BA_ "GenSigSNA" SG_ 1486 PARK_sw087_s3_sensorType "3";
BA_ "Confidence" SG_ 1486 PARK_sw087_s4_sensorType 1;
BA_ "GenSigSNA" SG_ 1486 PARK_sw087_s4_sensorType "3";
BA_ "Confidence" SG_ 1486 PARK_sw087_s5_sensorType 1;
BA_ "GenSigSNA" SG_ 1486 PARK_sw087_s5_sensorType "3";
BA_ "Confidence" SG_ 1486 PARK_sw087_s6_sensorType 1;
BA_ "GenSigSNA" SG_ 1486 PARK_sw087_s6_sensorType "3";
BA_ "Confidence" SG_ 1486 PARK_sw087_s7_sensorType 1;
BA_ "GenSigSNA" SG_ 1486 PARK_sw087_s7_sensorType "3";
BA_ "Confidence" SG_ 1486 PARK_sw087_s8_sensorType 1;
BA_ "GenSigSNA" SG_ 1486 PARK_sw087_s8_sensorType "3";
BA_ "Confidence" SG_ 1486 PARK_sw087_s9_sensorType 1;
BA_ "GenSigSNA" SG_ 1486 PARK_sw087_s9_sensorType "3";
BA_ "Confidence" SG_ 1486 PARK_sw087_s10_sensorType 1;
BA_ "GenSigSNA" SG_ 1486 PARK_sw087_s10_sensorType "3";
BA_ "Confidence" SG_ 1486 PARK_sw087_s11_sensorType 1;
BA_ "GenSigSNA" SG_ 1486 PARK_sw087_s11_sensorType "3";
BA_ "Confidence" SG_ 1486 PARK_sw087_s12_sensorType 1;
BA_ "GenSigSNA" SG_ 1486 PARK_sw087_s12_sensorType "3";
BA_ "Confidence" SG_ 806 PARK_infoIndex 1;
BA_ "Confidence" SG_ 806 PARK_infoBuildType 0;
BA_ "Confidence" SG_ 806 PARK_infoComponentID 0;
BA_ "Confidence" SG_ 806 PARK_infoPcbaID 0;
BA_ "Confidence" SG_ 806 PARK_infoAssemblyID 0;
BA_ "Confidence" SG_ 806 PARK_infoUsageID 0;
BA_ "Confidence" SG_ 806 PARK_infoApplicationCRC 0;
BA_ "Confidence" SG_ 806 PARK_infoBootUdsProtoVersion 0;
BA_ "Confidence" SG_ 806 PARK_infoBootloaderCRC 0;
BA_ "Confidence" SG_ 846 PARK_frontLeftMiddleRawDistData 0;
BA_ "GenSigSNA" SG_ 846 PARK_frontLeftMiddleRawDistData "255";
BA_ "Confidence" SG_ 846 PARK_frontMiddleRawDistData 0;
BA_ "GenSigSNA" SG_ 846 PARK_frontMiddleRawDistData "255";
BA_ "Confidence" SG_ 846 PARK_frontRightMiddleRawDistData 0;
BA_ "GenSigSNA" SG_ 846 PARK_frontRightMiddleRawDistData "255";
BA_ "Confidence" SG_ 846 PARK_pasFrontMiddleCounter 0;
BA_ "Confidence" SG_ 846 PARK_pasFrontMiddleChecksum 0;
BA_ "Confidence" SG_ 862 PARK_rearLeftMiddleRawDistData 0;
BA_ "GenSigSNA" SG_ 862 PARK_rearLeftMiddleRawDistData "255";
BA_ "Confidence" SG_ 862 PARK_rearMiddleRawDistData 0;
BA_ "GenSigSNA" SG_ 862 PARK_rearMiddleRawDistData "255";
BA_ "Confidence" SG_ 862 PARK_rearRightMiddleRawDistData 0;
BA_ "GenSigSNA" SG_ 862 PARK_rearRightMiddleRawDistData "255";
BA_ "Confidence" SG_ 862 PARK_pasRearMiddleCounter 0;
BA_ "Confidence" SG_ 862 PARK_pasRearMiddleChecksum 0;
BA_ "Confidence" SG_ 926 PARK_rightSideFrontRawDistData 0;
BA_ "GenSigSNA" SG_ 926 PARK_rightSideFrontRawDistData "255";
BA_ "Confidence" SG_ 926 PARK_rightSideRearRawDistData 0;
BA_ "GenSigSNA" SG_ 926 PARK_rightSideRearRawDistData "255";
BA_ "Confidence" SG_ 926 PARK_leftSideFrontRawDistData 0;
BA_ "GenSigSNA" SG_ 926 PARK_leftSideFrontRawDistData "255";
BA_ "Confidence" SG_ 926 PARK_leftSideRearRawDistData 0;
BA_ "GenSigSNA" SG_ 926 PARK_leftSideRearRawDistData "255";
BA_ "Confidence" SG_ 926 PARK_pasSidesCounter 0;
BA_ "Confidence" SG_ 926 PARK_pasSidesChecksum 0;
BA_ "Confidence" SG_ 606 PARK_pscEnvSlotType 1;
BA_ "Confidence" SG_ 606 PARK_pscLeftParallelObj1X 0;
BA_ "GenSigSNA" SG_ 606 PARK_pscLeftParallelObj1X "2047";
BA_ "Confidence" SG_ 606 PARK_pscLeftParallelObj1Y 0;
BA_ "GenSigSNA" SG_ 606 PARK_pscLeftParallelObj1Y "2047";
BA_ "Confidence" SG_ 606 PARK_pscLeftParallelObj1Alpha 0;
BA_ "GenSigSNA" SG_ 606 PARK_pscLeftParallelObj1Alpha "127";
BA_ "Confidence" SG_ 606 PARK_pscLeftParallelObj2Y 0;
BA_ "GenSigSNA" SG_ 606 PARK_pscLeftParallelObj2Y "2047";
BA_ "Confidence" SG_ 606 PARK_pscLeftParallelObj2X 0;
BA_ "GenSigSNA" SG_ 606 PARK_pscLeftParallelObj2X "2047";
BA_ "Confidence" SG_ 606 PARK_pscLeftParallelObj2Alpha 0;
BA_ "GenSigSNA" SG_ 606 PARK_pscLeftParallelObj2Alpha "127";
BA_ "Confidence" SG_ 606 PARK_pscLeftCrossObj1X 0;
BA_ "GenSigSNA" SG_ 606 PARK_pscLeftCrossObj1X "2047";
BA_ "Confidence" SG_ 606 PARK_pscLeftCrossObj1Y 0;
BA_ "GenSigSNA" SG_ 606 PARK_pscLeftCrossObj1Y "2047";
BA_ "Confidence" SG_ 606 PARK_pscLeftCrossObj1Alpha 0;
BA_ "GenSigSNA" SG_ 606 PARK_pscLeftCrossObj1Alpha "127";
BA_ "Confidence" SG_ 606 PARK_pscLeftCrossObj2Y 0;
BA_ "GenSigSNA" SG_ 606 PARK_pscLeftCrossObj2Y "2047";
BA_ "Confidence" SG_ 606 PARK_pscLeftCrossObj2X 0;
BA_ "GenSigSNA" SG_ 606 PARK_pscLeftCrossObj2X "2047";
BA_ "Confidence" SG_ 606 PARK_pscLeftCrossObj2Alpha 0;
BA_ "GenSigSNA" SG_ 606 PARK_pscLeftCrossObj2Alpha "127";
BA_ "Confidence" SG_ 606 PARK_pscRightParallelObj1X 0;
BA_ "GenSigSNA" SG_ 606 PARK_pscRightParallelObj1X "2047";
BA_ "Confidence" SG_ 606 PARK_pscRightParallelObj1Y 0;
BA_ "GenSigSNA" SG_ 606 PARK_pscRightParallelObj1Y "2047";
BA_ "Confidence" SG_ 606 PARK_pscRightParallelObj1Alpha 0;
BA_ "GenSigSNA" SG_ 606 PARK_pscRightParallelObj1Alpha "127";
BA_ "Confidence" SG_ 606 PARK_pscRightParallelObj2Y 0;
BA_ "GenSigSNA" SG_ 606 PARK_pscRightParallelObj2Y "2047";
BA_ "Confidence" SG_ 606 PARK_pscRightParallelObj2X 0;
BA_ "GenSigSNA" SG_ 606 PARK_pscRightParallelObj2X "2047";
BA_ "Confidence" SG_ 606 PARK_pscRightParallelObj2Alpha 0;
BA_ "GenSigSNA" SG_ 606 PARK_pscRightParallelObj2Alpha "127";
BA_ "Confidence" SG_ 606 PARK_pscRightCrossObj1X 0;
BA_ "GenSigSNA" SG_ 606 PARK_pscRightCrossObj1X "2047";
BA_ "Confidence" SG_ 606 PARK_pscRightCrossObj1Y 0;
BA_ "GenSigSNA" SG_ 606 PARK_pscRightCrossObj1Y "2047";
BA_ "Confidence" SG_ 606 PARK_pscRightCrossObj1Alpha 0;
BA_ "GenSigSNA" SG_ 606 PARK_pscRightCrossObj1Alpha "127";
BA_ "Confidence" SG_ 606 PARK_pscRightCrossObj2Y 0;
BA_ "GenSigSNA" SG_ 606 PARK_pscRightCrossObj2Y "2047";
BA_ "Confidence" SG_ 606 PARK_pscRightCrossObj2X 0;
BA_ "GenSigSNA" SG_ 606 PARK_pscRightCrossObj2X "2047";
BA_ "Confidence" SG_ 606 PARK_pscRightCrossObj2Alpha 0;
BA_ "GenSigSNA" SG_ 606 PARK_pscRightCrossObj2Alpha "127";
BA_ "Confidence" SG_ 542 PARK_pscParkStatus 0;
BA_ "GenSigSNA" SG_ 542 PARK_pscParkStatus "7";
BA_ "Confidence" SG_ 542 PARK_pscParkAbortReason 0;
BA_ "GenSigSNA" SG_ 542 PARK_pscParkAbortReason "31";
BA_ "Confidence" SG_ 542 PARK_pscParallelSpace 0;
BA_ "Confidence" SG_ 542 PARK_pscCrossSpace 0;
BA_ "Confidence" SG_ 542 PARK_pscParallelRightParkable 0;
BA_ "GenSigSNA" SG_ 542 PARK_pscParallelRightParkable "3";
BA_ "Confidence" SG_ 542 PARK_pscParallelLeftParkable 0;
BA_ "GenSigSNA" SG_ 542 PARK_pscParallelLeftParkable "3";
BA_ "Confidence" SG_ 542 PARK_pscCrossRightParkable 0;
BA_ "GenSigSNA" SG_ 542 PARK_pscCrossRightParkable "3";
BA_ "Confidence" SG_ 542 PARK_pscMaxVelocity 0;
BA_ "GenSigSNA" SG_ 542 PARK_pscMaxVelocity "63";
BA_ "Confidence" SG_ 542 PARK_pscCrossLeftParkable 0;
BA_ "GenSigSNA" SG_ 542 PARK_pscCrossLeftParkable "3";
BA_ "Confidence" SG_ 542 PARK_pscParkInstruction 0;
BA_ "GenSigSNA" SG_ 542 PARK_pscParkInstruction "7";
BA_ "Confidence" SG_ 542 PARK_pscManeuverDistance 0;
BA_ "GenSigSNA" SG_ 542 PARK_pscManeuverDistance "2047";
BA_ "Confidence" SG_ 542 PARK_pscAngleActive 0;
BA_ "Confidence" SG_ 542 PARK_pscAngleRequest 0;
BA_ "Confidence" SG_ 542 PARK_pscStatusCounter 0;
BA_ "Confidence" SG_ 542 PARK_pscStatusChecksum 0;
BA_ "Confidence" SG_ 590 PARK_pscVehSlotType 1;
BA_ "Confidence" SG_ 590 PARK_pscLeftParallelVehX 0;
BA_ "GenSigSNA" SG_ 590 PARK_pscLeftParallelVehX "2047";
BA_ "Confidence" SG_ 590 PARK_pscLeftParallelVehY 0;
BA_ "GenSigSNA" SG_ 590 PARK_pscLeftParallelVehY "2047";
BA_ "Confidence" SG_ 590 PARK_pscLeftParallelPsi 0;
BA_ "GenSigSNA" SG_ 590 PARK_pscLeftParallelPsi "8191";
BA_ "Confidence" SG_ 590 PARK_pscLeftParallelSizeX 0;
BA_ "GenSigSNA" SG_ 590 PARK_pscLeftParallelSizeX "255";
BA_ "Confidence" SG_ 590 PARK_pscLeftParallelSizeY 0;
BA_ "GenSigSNA" SG_ 590 PARK_pscLeftParallelSizeY "255";
BA_ "Confidence" SG_ 590 PARK_pscLeftCrossVehX 0;
BA_ "GenSigSNA" SG_ 590 PARK_pscLeftCrossVehX "2047";
BA_ "Confidence" SG_ 590 PARK_pscLeftCrossVehY 0;
BA_ "GenSigSNA" SG_ 590 PARK_pscLeftCrossVehY "2047";
BA_ "Confidence" SG_ 590 PARK_pscLeftCrossPsi 0;
BA_ "GenSigSNA" SG_ 590 PARK_pscLeftCrossPsi "8191";
BA_ "Confidence" SG_ 590 PARK_pscLeftCrossSizeX 0;
BA_ "GenSigSNA" SG_ 590 PARK_pscLeftCrossSizeX "255";
BA_ "Confidence" SG_ 590 PARK_pscLeftCrossSizeY 0;
BA_ "GenSigSNA" SG_ 590 PARK_pscLeftCrossSizeY "255";
BA_ "Confidence" SG_ 590 PARK_pscRightParallelVehX 0;
BA_ "GenSigSNA" SG_ 590 PARK_pscRightParallelVehX "2047";
BA_ "Confidence" SG_ 590 PARK_pscRightParallelVehY 0;
BA_ "GenSigSNA" SG_ 590 PARK_pscRightParallelVehY "2047";
BA_ "Confidence" SG_ 590 PARK_pscRightParallelPsi 0;
BA_ "GenSigSNA" SG_ 590 PARK_pscRightParallelPsi "8191";
BA_ "Confidence" SG_ 590 PARK_pscRightParallelSizeX 0;
BA_ "GenSigSNA" SG_ 590 PARK_pscRightParallelSizeX "255";
BA_ "Confidence" SG_ 590 PARK_pscRightParallelSizeY 0;
BA_ "GenSigSNA" SG_ 590 PARK_pscRightParallelSizeY "255";
BA_ "Confidence" SG_ 590 PARK_pscRightCrossVehX 0;
BA_ "GenSigSNA" SG_ 590 PARK_pscRightCrossVehX "2047";
BA_ "Confidence" SG_ 590 PARK_pscRightCrossVehY 0;
BA_ "GenSigSNA" SG_ 590 PARK_pscRightCrossVehY "2047";
BA_ "Confidence" SG_ 590 PARK_pscRightCrossPsi 0;
BA_ "GenSigSNA" SG_ 590 PARK_pscRightCrossPsi "8191";
BA_ "Confidence" SG_ 590 PARK_pscRightCrossSizeX 0;
BA_ "GenSigSNA" SG_ 590 PARK_pscRightCrossSizeX "255";
BA_ "Confidence" SG_ 590 PARK_pscRightCrossSizeY 0;
BA_ "GenSigSNA" SG_ 590 PARK_pscRightCrossSizeY "255";
BA_ "Confidence" SG_ 526 PARK_sdiSensor1RawDistData 0;
BA_ "GenSigSNA" SG_ 526 PARK_sdiSensor1RawDistData "511";
BA_ "Confidence" SG_ 526 PARK_sdiSensor2RawDistData 0;
BA_ "GenSigSNA" SG_ 526 PARK_sdiSensor2RawDistData "511";
BA_ "Confidence" SG_ 526 PARK_sdiSensor3RawDistData 0;
BA_ "GenSigSNA" SG_ 526 PARK_sdiSensor3RawDistData "511";
BA_ "Confidence" SG_ 526 PARK_sdiSensor4RawDistData 0;
BA_ "GenSigSNA" SG_ 526 PARK_sdiSensor4RawDistData "511";
BA_ "Confidence" SG_ 526 PARK_sdiSensor5RawDistData 0;
BA_ "GenSigSNA" SG_ 526 PARK_sdiSensor5RawDistData "511";
BA_ "Confidence" SG_ 526 PARK_sdiSensor6RawDistData 0;
BA_ "GenSigSNA" SG_ 526 PARK_sdiSensor6RawDistData "511";
BA_ "Confidence" SG_ 526 PARK_sdiFrontCounter 0;
BA_ "Confidence" SG_ 526 PARK_sdiFrontChecksum 0;
BA_ "Confidence" SG_ 558 PARK_sdiSensor7RawDistData 0;
BA_ "GenSigSNA" SG_ 558 PARK_sdiSensor7RawDistData "511";
BA_ "Confidence" SG_ 558 PARK_sdiSensor8RawDistData 0;
BA_ "GenSigSNA" SG_ 558 PARK_sdiSensor8RawDistData "511";
BA_ "Confidence" SG_ 558 PARK_sdiSensor9RawDistData 0;
BA_ "GenSigSNA" SG_ 558 PARK_sdiSensor9RawDistData "511";
BA_ "Confidence" SG_ 558 PARK_sdiSensor10RawDistData 0;
BA_ "GenSigSNA" SG_ 558 PARK_sdiSensor10RawDistData "511";
BA_ "Confidence" SG_ 558 PARK_sdiSensor11RawDistData 0;
BA_ "GenSigSNA" SG_ 558 PARK_sdiSensor11RawDistData "511";
BA_ "Confidence" SG_ 558 PARK_sdiSensor12RawDistData 0;
BA_ "GenSigSNA" SG_ 558 PARK_sdiSensor12RawDistData "511";
BA_ "Confidence" SG_ 558 PARK_sdiRearCounter 0;
BA_ "Confidence" SG_ 558 PARK_sdiRearChecksum 0;
BA_ "Confidence" SG_ 814 PARK_frontRightSensorState 0;
BA_ "GenSigSNA" SG_ 814 PARK_frontRightSensorState "3";
BA_ "Confidence" SG_ 814 PARK_frontRightMiddleSensorState 0;
BA_ "GenSigSNA" SG_ 814 PARK_frontRightMiddleSensorState "3";
BA_ "Confidence" SG_ 814 PARK_frontLeftMiddleSensorState 0;
BA_ "GenSigSNA" SG_ 814 PARK_frontLeftMiddleSensorState "3";
BA_ "Confidence" SG_ 814 PARK_frontLeftSensorState 0;
BA_ "GenSigSNA" SG_ 814 PARK_frontLeftSensorState "3";
BA_ "Confidence" SG_ 814 PARK_frontLeftRawDistData 0;
BA_ "GenSigSNA" SG_ 814 PARK_frontLeftRawDistData "255";
BA_ "Confidence" SG_ 814 PARK_frontRightRawDistData 0;
BA_ "GenSigSNA" SG_ 814 PARK_frontRightRawDistData "255";
BA_ "Confidence" SG_ 814 PARK_systemStatusFront 0;
BA_ "GenSigSNA" SG_ 814 PARK_systemStatusFront "3";
BA_ "Confidence" SG_ 814 PARK_frontDtcPresent 0;
BA_ "GenSigSNA" SG_ 814 PARK_frontDtcPresent "3";
BA_ "Confidence" SG_ 814 PARK_sensorStatusFrontCounter 0;
BA_ "Confidence" SG_ 814 PARK_sensorStatusFrontChecksum 0;
BA_ "Confidence" SG_ 830 PARK_rearRightSensorState 0;
BA_ "GenSigSNA" SG_ 830 PARK_rearRightSensorState "3";
BA_ "Confidence" SG_ 830 PARK_rearRightMiddleSensorState 0;
BA_ "GenSigSNA" SG_ 830 PARK_rearRightMiddleSensorState "3";
BA_ "Confidence" SG_ 830 PARK_rearLeftMiddleSensorState 0;
BA_ "GenSigSNA" SG_ 830 PARK_rearLeftMiddleSensorState "3";
BA_ "Confidence" SG_ 830 PARK_rearLeftSensorState 0;
BA_ "GenSigSNA" SG_ 830 PARK_rearLeftSensorState "3";
BA_ "Confidence" SG_ 830 PARK_rearLeftRawDistData 0;
BA_ "GenSigSNA" SG_ 830 PARK_rearLeftRawDistData "255";
BA_ "Confidence" SG_ 830 PARK_rearRightRawDistData 0;
BA_ "GenSigSNA" SG_ 830 PARK_rearRightRawDistData "255";
BA_ "Confidence" SG_ 830 PARK_systemStatusRear 0;
BA_ "GenSigSNA" SG_ 830 PARK_systemStatusRear "3";
BA_ "Confidence" SG_ 830 PARK_rearDtcPresent 0;
BA_ "GenSigSNA" SG_ 830 PARK_rearDtcPresent "3";
BA_ "Confidence" SG_ 830 PARK_sensorStatusRearCounter 0;
BA_ "Confidence" SG_ 830 PARK_sensorStatusRearChecksum 0;
BA_ "Confidence" SG_ 798 PARK_status 0;
BA_ "GenSigSNA" SG_ 798 PARK_status "3";
BA_ "Confidence" SG_ 798 PARK_serviceRequest 0;
BA_ "GenSigSNA" SG_ 798 PARK_serviceRequest "3";
BA_ "Confidence" SG_ 798 PARK_systemDtcPresent 0;
BA_ "GenSigSNA" SG_ 798 PARK_systemDtcPresent "3";
BA_ "Confidence" SG_ 798 PARK_statusCounter 0;
BA_ "Confidence" SG_ 798 PARK_statusChecksum 0;
BA_ "Confidence" SG_ 798 PARK_majorVersion 0;
BA_ "GenSigSNA" SG_ 798 PARK_majorVersion "255";
BA_ "Confidence" SG_ 798 PARK_minorVersion 0;
BA_ "GenSigSNA" SG_ 798 PARK_minorVersion "255";
BA_ "Confidence" SG_ 798 PARK_subMinorVersion 0;
BA_ "GenSigSNA" SG_ 798 PARK_subMinorVersion "255";
BA_ "Confidence" SG_ 782 PARK_frontSVACharID 0;
BA_ "Confidence" SG_ 782 PARK_pscRightCurbType 0;
BA_ "Confidence" SG_ 782 PARK_rearSVACharID 0;
BA_ "Confidence" SG_ 782 PARK_pscLeftCurbType 0;
BA_ "Confidence" SG_ 782 PARK_autoCalComplete 0;
BA_ "Confidence" SG_ 782 PARK_geometryType 0;
BA_ "Confidence" SG_ 782 PARK_tireFitment 0;
BA_ "GenSigSNA" SG_ 782 PARK_tireFitment "3";
BA_ "Confidence" SG_ 782 PARK_rackDetected 0;
BA_ "GenSigSNA" SG_ 782 PARK_rackDetected "3";
BA_ "Confidence" SG_ 782 PARK_sdiActive 0;
BA_ "Confidence" SG_ 782 PARK_sdiNoise 0;
BA_ "GenSigSNA" SG_ 782 PARK_sdiNoise "3";
BA_ "Confidence" SG_ 782 PARK_sdiBlindSpotRight 0;
BA_ "GenSigSNA" SG_ 782 PARK_sdiBlindSpotRight "3";
BA_ "Confidence" SG_ 782 PARK_sdiBlindSpotLeft 0;
BA_ "GenSigSNA" SG_ 782 PARK_sdiBlindSpotLeft "3";
BA_ "Confidence" SG_ 782 PARK_sensorType 0;
BA_ "GenSigSNA" SG_ 782 PARK_sensorType "3";
BA_ "Confidence" SG_ 782 PARK_status2Counter 0;
BA_ "Confidence" SG_ 782 PARK_status2Checksum 0;
BA_ "Confidence" SG_ 1630 PARK_udsResponseData 1;
BA_ "Confidence" SG_ 894 PARK_matrixIndex 1;
VAL_ 1470 IDB_alertID 157 "a157_PMlocStateCounter" 156 "a156_PMlocStateChecksum" 155 "a155_PMlocStateDLC" 152 "a152_DIlocStatus2Checksum" 151 "a151_DIlocStatus2Counter" 150 "a150_DIlocStatus2DLC" 149 "a149_DASmiaBrakeTorqueCommandInvalid" 148 "a148_DASbrakeTorqueCommandInvalid" 147 "a147_DASredundantBrakingControlChecksum" 146 "a146_DASredundantBrakingControlCounter" 145 "a145_DASredundantBrakingControlDLC" 144 "a144_hydraulicPushthroughActive" 143 "a143_factoryModeActive" 142 "a142_PMebrCmdStateInvalid" 141 "a141_DIbrakeTorqueCommandFullTooLow" 140 "a140_PMbrakePedalCmdQFInvalid" 139 "a139_DIbrakeTorqueCommandFullSNA" 138 "a138_DIbrakeTorqueCommandAndFlagMismatch" 137 "a137_VCLEFTcdpRequestInvalid" 136 "a136_RCUptsCalMissing" 135 "a135_DIbrakeCommandChecksum" 134 "a134_DIbrakeCommandCounter" 133 "a133_DIbrakeCommandDLC" 132 "a132_RCUinputRodStrokeQFInvalid" 131 "a131_cbcFaulted" 130 "a130_DIfullTorqueRequestInvalid" 129 "a129_RCUinputRodStrokeInvalid" 128 "a128_largeAirVolume" 127 "a127_brakeFluidLevelInvalid" 126 "a126_DItorqueRequestInvalid" 125 "a125_PMvdcCmdStateInvalid" 124 "a124_VCFRONTtempInvalid" 123 "a123_DIRtorqueCommandInvalid" 122 "a122_DIFtorqueCommandInvalid" 121 "a121_dynoModeActive" 120 "a120_EPAS3Pinvalid" 119 "a119_VCLEFTepbmStatusChecksum" 118 "a118_VCLEFTepbmStatusCounter" 117 "a117_VCLEFTepbmStatusDLC" 116 "a116_VCFRONTsensorsDLC" 115 "a115_VCFRONTespLvStInvalid" 114 "a114_longAccelInvalid" 113 "a113_latAccelInvalid" 112 "a112_yawRateInvalid" 111 "a111_EPBstatusChecksum" 110 "a110_EPBstatusCounter" 109 "a109_BDWsignalInvalid" 108 "a108_EPBstatusDLC" 107 "a107_DIRtorqueInvalid" 106 "a106_DIFtorqueInvalid" 105 "a105_DIgearInvalid" 104 "a104_DIaccelPosInvalid" 103 "a103_DIfullTorquePathFaulted" 102 "a102_bdwRequestActiveInvalid" 101 "a101_RCMcollisionCounter" 100 "a100_RCMcollisionChecksum" 99 "a099_RCMcollisionDLC" 98 "a098_VCFRONTLVPwrStCounter" 97 "a097_VCFRONTLVPwrStChecksum" 96 "a096_VCFRONTLVPowerStateDLC" 95 "a095_RCMinertial2Counter" 94 "a094_RCMinertial2Checksum" 93 "a093_RCMinertial2DLC" 92 "a092_RCMinertial1Counter" 91 "a091_RCMinertial1Checksum" 90 "a090_RCMinertial1DLC" 89 "a089_PMstate2Counter" 88 "a088_PMstate2Checksum" 87 "a087_PMstate2DLC" 86 "a086_EPAS3PsysStatusCounter" 85 "a085_EPAS3PsysStatusChecksum" 84 "a084_EPAS3PsysStatusDLC" 83 "a083_DIvdcRightCounter" 82 "a082_DIvdcRightChecksum" 81 "a081_DIvdcRightDLC" 80 "a080_DIvdcLeftCounter" 79 "a079_DIvdcLeftChecksum" 78 "a078_DIvdcLeftDLC" 77 "a077_DIRtorqueCounter" 76 "a076_DIRtorqueChecksum" 75 "a075_DIRtorqueDLC" 74 "a074_DIsystemStatusCounter" 73 "a073_DIsystemStatusChecksum" 72 "a072_DIsystemStatusDLC" 71 "a071_DIchassisControlCounter" 70 "a070_DIchassisControlChecksum" 69 "a069_DIchassisControlDLC" 68 "a068_DIFtorqueCounter" 67 "a067_DIFtorqueChecksum" 66 "a066_DIFtorqueDLC" 65 "a065_RCUactuationCounter" 64 "a064_RCUactuationChecksum" 63 "a063_RCUactuationDLC" 62 "a062_RCUstatusCounter" 61 "a061_RCUstatusChecksum" 60 "a060_RCUstatusDLC" 59 "a059_cdpFaulted" 58 "a058_scmFaulted" 57 "a057_bdwRequestInvalid" 56 "a056_fadeCompensationFaulted" 55 "a055_panicBrakeAssistFaulted" 54 "a054_skidDetectionFaulted" 53 "a053_DItorquePathFaulted" 52 "a052_vdcFaulted" 51 "a051_ebdFaulted" 50 "a050_absFaulted" 49 "a049_cdpActive" 48 "a048_scmActive" 47 "a047_brakeDiscWipeActive" 46 "a046_fadeCompensationActive" 45 "a045_panicBrakeAssistActive" 44 "a044_standstillSkidDetected" 43 "a043_cbcActive" 42 "a042_btcActive" 41 "a041_vdcActive" 40 "a040_ebdActive" 39 "a039_absActive" 38 "a038_motorInitFault" 37 "a037_chassisBusOff" 36 "a036_partyBusOff" 35 "a035_motorStuck" 34 "a034_motorPositionSetFault" 33 "a033_motorHardOverheat" 32 "a032_motorSoftOverheat" 31 "a031_solenoidValveStuck" 30 "a030_fluidLeakDetected" 29 "a029_pressureSensNotCal" 28 "a028_simPresSensorFault" 27 "a027_circuitPresSensorFault" 26 "a026_axImplausible" 25 "a025_ayImplausible" 24 "a024_yawImplausible" 23 "a023_steeringImplausible" 22 "a022_brakeFluidLow" 21 "a021_pedalSensorNotCal" 20 "a020_RCUpedalTravelMismatch" 19 "a019_pedalSensorFault" 18 "a018_WSSGenericFault" 17 "a017_ReRWSSFault" 16 "a016_ReLWSSFault" 15 "a015_FrRWSSFault" 14 "a014_FrLWSSFault" 13 "a013_motorPosSensorFault" 12 "a012_motorGenericFault" 11 "a011_solenoidValveFault" 10 "a010_asicGenericFault" 9 "a009_asicBoostFault" 8 "a008_motorPowerOpen" 7 "a007_wakeLineOpen" 6 "a006_supplyHardUndervoltage" 5 "a005_supplyMidUndervoltage" 4 "a004_supplyUndervoltage" 3 "a003_supplyHardOvervoltage" 2 "a002_supplyOvervoltage" 1 "a001_mcuGenericFault" 0 "ALERT_DO_NOT_USE_ZERO" ;
VAL_ 1470 IDB_alertState 1 "SET" 0 "CLEARED" ;
VAL_ 1470 IDB_a014_wheelSpeedSensorFreq 1 "NOT_OK" 0 "OK" ;
VAL_ 1470 IDB_a014_wheelSpeedSensorPhase 1 "NOT_OK" 0 "OK" ;
VAL_ 1470 IDB_a014_wheelSpeedSensorMisinst 1 "NOT_OK" 0 "OK" ;
VAL_ 1470 IDB_a014_wheelSpeedSensorWrongEx 1 "NOT_OK" 0 "OK" ;
VAL_ 1470 IDB_a014_wheelSpeedSensorSpeedJu 1 "NOT_OK" 0 "OK" ;
VAL_ 1470 IDB_a014_wheelSpeedSensorSp_0001 1 "NOT_OK" 0 "OK" ;
VAL_ 1470 IDB_a014_wheelSpeedSensorAirGap 1 "NOT_OK" 0 "OK" ;
VAL_ 1470 IDB_a014_wheelSpeedSensorBIST 1 "NOT_OK" 0 "OK" ;
VAL_ 1470 IDB_a014_wheelSpeedSensorLeakage 1 "NOT_OK" 0 "OK" ;
VAL_ 1470 IDB_a014_wheelSpeedSensorOverTem 1 "NOT_OK" 0 "OK" ;
VAL_ 1470 IDB_a014_wheelSpeedSensorSh_0001 1 "NOT_OK" 0 "OK" ;
VAL_ 1470 IDB_a014_wheelSpeedSensorShortTo 1 "NOT_OK" 0 "OK" ;
VAL_ 1470 IDB_a014_wheelSpeedSensorOpen 1 "NOT_OK" 0 "OK" ;
VAL_ 1470 IDB_a015_wheelSpeedSensorFreq 1 "NOT_OK" 0 "OK" ;
VAL_ 1470 IDB_a015_wheelSpeedSensorPhase 1 "NOT_OK" 0 "OK" ;
VAL_ 1470 IDB_a015_wheelSpeedSensorMisinst 1 "NOT_OK" 0 "OK" ;
VAL_ 1470 IDB_a015_wheelSpeedSensorWrongEx 1 "NOT_OK" 0 "OK" ;
VAL_ 1470 IDB_a015_wheelSpeedSensorSpeedJu 1 "NOT_OK" 0 "OK" ;
VAL_ 1470 IDB_a015_wheelSpeedSensorSp_0001 1 "NOT_OK" 0 "OK" ;
VAL_ 1470 IDB_a015_wheelSpeedSensorAirGap 1 "NOT_OK" 0 "OK" ;
VAL_ 1470 IDB_a015_wheelSpeedSensorBIST 1 "NOT_OK" 0 "OK" ;
VAL_ 1470 IDB_a015_wheelSpeedSensorLeakage 1 "NOT_OK" 0 "OK" ;
VAL_ 1470 IDB_a015_wheelSpeedSensorOverTem 1 "NOT_OK" 0 "OK" ;
VAL_ 1470 IDB_a015_wheelSpeedSensorSh_0001 1 "NOT_OK" 0 "OK" ;
VAL_ 1470 IDB_a015_wheelSpeedSensorShortTo 1 "NOT_OK" 0 "OK" ;
VAL_ 1470 IDB_a015_wheelSpeedSensorOpen 1 "NOT_OK" 0 "OK" ;
VAL_ 1470 IDB_a016_wheelSpeedSensorFreq 1 "NOT_OK" 0 "OK" ;
VAL_ 1470 IDB_a016_wheelSpeedSensorPhase 1 "NOT_OK" 0 "OK" ;
VAL_ 1470 IDB_a016_wheelSpeedSensorMisinst 1 "NOT_OK" 0 "OK" ;
VAL_ 1470 IDB_a016_wheelSpeedSensorWrongEx 1 "NOT_OK" 0 "OK" ;
VAL_ 1470 IDB_a016_wheelSpeedSensorSpeedJu 1 "NOT_OK" 0 "OK" ;
VAL_ 1470 IDB_a016_wheelSpeedSensorSp_0001 1 "NOT_OK" 0 "OK" ;
VAL_ 1470 IDB_a016_wheelSpeedSensorAirGap 1 "NOT_OK" 0 "OK" ;
VAL_ 1470 IDB_a016_wheelSpeedSensorBIST 1 "NOT_OK" 0 "OK" ;
VAL_ 1470 IDB_a016_wheelSpeedSensorLeakage 1 "NOT_OK" 0 "OK" ;
VAL_ 1470 IDB_a016_wheelSpeedSensorOverTem 1 "NOT_OK" 0 "OK" ;
VAL_ 1470 IDB_a016_wheelSpeedSensorSh_0001 1 "NOT_OK" 0 "OK" ;
VAL_ 1470 IDB_a016_wheelSpeedSensorShortTo 1 "NOT_OK" 0 "OK" ;
VAL_ 1470 IDB_a016_wheelSpeedSensorOpen 1 "NOT_OK" 0 "OK" ;
VAL_ 1470 IDB_a017_wheelSpeedSensorFreq 1 "NOT_OK" 0 "OK" ;
VAL_ 1470 IDB_a017_wheelSpeedSensorPhase 1 "NOT_OK" 0 "OK" ;
VAL_ 1470 IDB_a017_wheelSpeedSensorMisinst 1 "NOT_OK" 0 "OK" ;
VAL_ 1470 IDB_a017_wheelSpeedSensorWrongEx 1 "NOT_OK" 0 "OK" ;
VAL_ 1470 IDB_a017_wheelSpeedSensorSpeedJu 1 "NOT_OK" 0 "OK" ;
VAL_ 1470 IDB_a017_wheelSpeedSensorSp_0001 1 "NOT_OK" 0 "OK" ;
VAL_ 1470 IDB_a017_wheelSpeedSensorAirGap 1 "NOT_OK" 0 "OK" ;
VAL_ 1470 IDB_a017_wheelSpeedSensorBIST 1 "NOT_OK" 0 "OK" ;
VAL_ 1470 IDB_a017_wheelSpeedSensorLeakage 1 "NOT_OK" 0 "OK" ;
VAL_ 1470 IDB_a017_wheelSpeedSensorOverTem 1 "NOT_OK" 0 "OK" ;
VAL_ 1470 IDB_a017_wheelSpeedSensorSh_0001 1 "NOT_OK" 0 "OK" ;
VAL_ 1470 IDB_a017_wheelSpeedSensorShortTo 1 "NOT_OK" 0 "OK" ;
VAL_ 1470 IDB_a017_wheelSpeedSensorOpen 1 "NOT_OK" 0 "OK" ;
VAL_ 1470 IDB_a020_canSignalValidity 1 "NOT_OK" 0 "OK" ;
VAL_ 1470 IDB_a020_signalValueCrosscheck 1 "NOT_OK" 0 "OK" ;
VAL_ 1470 IDB_a030_primaryExternalCircuitL 1 "NOT_OK" 0 "OK" ;
VAL_ 1470 IDB_a030_secondaryExternalCircui 1 "NOT_OK" 0 "OK" ;
VAL_ 1470 IDB_a030_primaryChamberInternalL 1 "NOT_OK" 0 "OK" ;
VAL_ 1470 IDB_a030_syncModeInternalLeakage 1 "NOT_OK" 0 "OK" ;
VAL_ 1470 IDB_a030_secondaryChamberInterna 1 "NOT_OK" 0 "OK" ;
VAL_ 1470 IDB_a030_masterCylinderInternalL 1 "NOT_OK" 0 "OK" ;
VAL_ 1470 IDB_a060_validityOnChassisBus 1 "NOT_OK" 0 "OK" ;
VAL_ 1470 IDB_a060_validityOnPartyBus 1 "NOT_OK" 0 "OK" ;
VAL_ 1470 IDB_a061_validityOnChassisBus 1 "NOT_OK" 0 "OK" ;
VAL_ 1470 IDB_a061_validityOnPartyBus 1 "NOT_OK" 0 "OK" ;
VAL_ 1470 IDB_a063_validityOnChassisBus 1 "NOT_OK" 0 "OK" ;
VAL_ 1470 IDB_a063_validityOnPartyBus 1 "NOT_OK" 0 "OK" ;
VAL_ 1470 IDB_a064_validityOnChassisBus 1 "NOT_OK" 0 "OK" ;
VAL_ 1470 IDB_a064_validityOnPartyBus 1 "NOT_OK" 0 "OK" ;
VAL_ 1470 IDB_a065_validityOnChassisBus 1 "NOT_OK" 0 "OK" ;
VAL_ 1470 IDB_a065_validityOnPartyBus 1 "NOT_OK" 0 "OK" ;
VAL_ 1470 IDB_a106_qualifierValidity 1 "NOT_OK" 0 "OK" ;
VAL_ 1470 IDB_a106_signalNotAvailable 1 "NOT_OK" 0 "OK" ;
VAL_ 1470 IDB_a107_qualifierValidity 1 "NOT_OK" 0 "OK" ;
VAL_ 1470 IDB_a107_signalNotAvailable 1 "NOT_OK" 0 "OK" ;
VAL_ 1470 IDB_a112_qualifierValidity 1 "NOT_OK" 0 "OK" ;
VAL_ 1470 IDB_a112_signalNotAvailable 1 "NOT_OK" 0 "OK" ;
VAL_ 1470 IDB_a113_qualifierValidity 1 "NOT_OK" 0 "OK" ;
VAL_ 1470 IDB_a113_signalNotAvailable 1 "NOT_OK" 0 "OK" ;
VAL_ 1470 IDB_a114_qualifierValidity 1 "NOT_OK" 0 "OK" ;
VAL_ 1470 IDB_a114_signalNotAvailable 1 "NOT_OK" 0 "OK" ;
VAL_ 1470 IDB_a126_PMebrCmdStateValidity 1 "NOT_OK" 0 "OK" ;
VAL_ 1470 IDB_a126_PMstate2Validity 1 "NOT_OK" 0 "OK" ;
VAL_ 1470 IDB_a126_PMstate2Missing 1 "NOT_OK" 0 "OK" ;
VAL_ 1470 IDB_a126_DIchassisControlValidit 1 "NOT_OK" 0 "OK" ;
VAL_ 1470 IDB_a126_DIchassisControlMissing 1 "NOT_OK" 0 "OK" ;
VAL_ 1470 IDB_a126_DIrequestActiveValidity 1 "NOT_OK" 0 "OK" ;
VAL_ 1470 IDB_a129_validityOnChassisBus 1 "NOT_OK" 0 "OK" ;
VAL_ 1470 IDB_a129_validityOnPartyBus 1 "NOT_OK" 0 "OK" ;
VAL_ 1470 IDB_a130_PMbrakePedalCmdQFValidi 1 "NOT_OK" 0 "OK" ;
VAL_ 1470 IDB_a130_PMstate2Validity 1 "NOT_OK" 0 "OK" ;
VAL_ 1470 IDB_a130_PMstate2Missing 1 "NOT_OK" 0 "OK" ;
VAL_ 1470 IDB_a130_DIbrakeCommandValidity 1 "NOT_OK" 0 "OK" ;
VAL_ 1470 IDB_a130_DIbrakeCommandMissing 1 "NOT_OK" 0 "OK" ;
VAL_ 1470 IDB_a130_DIbrakeTorqueCommandFul 1 "NOT_OK" 0 "OK" ;
VAL_ 1470 IDB_a130_DIbrakeTorqueComma_0001 1 "NOT_OK" 0 "OK" ;
VAL_ 1470 IDB_a132_validityOnChassisBus 1 "NOT_OK" 0 "OK" ;
VAL_ 1470 IDB_a132_validityOnPartyBus 1 "NOT_OK" 0 "OK" ;
VAL_ 983 IDB_matrixIndex 2 "AlertMatrix2" 1 "AlertMatrix1" 0 "AlertMatrix0" ;
VAL_ 828 IDB_infoIndex 255 "END" 31 "SUBCOMPONENT_GITHASH" 30 "PACKAGE_SN_8_14" 29 "PACKAGE_SN_1_7" 27 "PACKAGE_PN_15_20" 26 "PACKAGE_PN_8_14" 25 "PACKAGE_PN_1_7" 23 "SUBCOMPONENT2" 22 "VARIANTCRC" 20 "UDS_PROTOCOL_BOOTCRC" 19 "VERSION_DEPRECATED" 18 "BOOTLOADER_GITHASH" 17 "APP_GITHASH" 16 "SUBCOMPONENT" 15 "BOOTLOADER_CRC" 14 "BOOTLOADER_SVN" 13 "APP_CRC" 11 "PCBAID_ASSYID_USAGEID" 10 "BUILD_HWID_COMPONENTID" 9 "DEPRECATED_9" 8 "DEPRECATED_8" 7 "DEPRECATED_7" 6 "DEPRECATED_6" 5 "DEPRECATED_5" 4 "DEPRECATED_4" 3 "DEPRECATED_3" 2 "DEPRECATED_2" 1 "DEPRECATED_1" 0 "DEPRECATED_0" ;
VAL_ 1486 PARK_alertID 87 "a087_sensorMismatchError" 86 "a086_nvmFault" 85 "a085_watchdogReset" 84 "a084_sccmError" 83 "a083_vcFrontError" 82 "a082_rcmError" 81 "a081_espError" 80 "a080_epbError" 79 "a079_epasError" 78 "a078_diError" 77 "a077_dasError" 76 "a076_vcFrontMia" 75 "a075_rcmMia" 74 "a074_espMia" 73 "a073_epbMia" 72 "a072_epasMia" 71 "a071_diMia" 70 "a070_sccmMia" 69 "a069_dasMia" 68 "a068_hardwareWatchDog" 67 "a067_privateCANBusOff" 66 "a066_calibrationMissing" 65 "a065_crcFault" 64 "a064_ecuFault" 63 "a063_sensorVoltage" 62 "a062_ecuOverVoltage" 61 "a061_ecuUnderVoltage" 60 "a060_s12_crossTalk" 59 "a059_s12_blocked" 58 "a058_s12_linCommError" 57 "a057_s12_internalFail" 56 "a056_s12_overTemp" 55 "a055_s11_crossTalk" 54 "a054_s11_blocked" 53 "a053_s11_linCommError" 52 "a052_s11_internalFail" 51 "a051_s11_overTemp" 50 "a050_s10_crossTalk" 49 "a049_s10_blocked" 48 "a048_s10_linCommError" 47 "a047_s10_internalFail" 46 "a046_s10_overTemp" 45 "a045_s9_crossTalk" 44 "a044_s9_blocked" 43 "a043_s9_linCommError" 42 "a042_s9_internalFail" 41 "a041_s9_overTemp" 40 "a040_s8_crossTalk" 39 "a039_s8_blocked" 38 "a038_s8_linCommError" 37 "a037_s8_internalFail" 36 "a036_s8_overTemp" 35 "a035_s7_crossTalk" 34 "a034_s7_blocked" 33 "a033_s7_linCommError" 32 "a032_s7_internalFail" 31 "a031_s7_overTemp" 30 "a030_s6_crossTalk" 29 "a029_s6_blocked" 28 "a028_s6_linCommError" 27 "a027_s6_internalFail" 26 "a026_s6_overTemp" 25 "a025_s5_crossTalk" 24 "a024_s5_blocked" 23 "a023_s5_linCommError" 22 "a022_s5_internalFail" 21 "a021_s5_overTemp" 20 "a020_s4_crossTalk" 19 "a019_s4_blocked" 18 "a018_s4_linCommError" 17 "a017_s4_internalFail" 16 "a016_s4_overTemp" 15 "a015_s3_crossTalk" 14 "a014_s3_blocked" 13 "a013_s3_linCommError" 12 "a012_s3_internalFail" 11 "a011_s3_overTemp" 10 "a010_s2_crossTalk" 9 "a009_s2_blocked" 8 "a008_s2_linCommError" 7 "a007_s2_internalFail" 6 "a006_s2_overTemp" 5 "a005_s1_crossTalk" 4 "a004_s1_blocked" 3 "a003_s1_linCommError" 2 "a002_s1_internalFail" 1 "a001_s1_overTemp" 0 "ALERT_DO_NOT_USE_ZERO" ;
VAL_ 1486 PARK_alertState 1 "SET" 0 "CLEARED" ;
VAL_ 1486 PARK_sw077_errorType 5 "OVERRUN" 4 "INVALID_DATA" 3 "SEQUENCE" 2 "CHECKSUM" 1 "LENGTH" 0 "NONE" ;
VAL_ 1486 PARK_sw078_errorType 5 "OVERRUN" 4 "INVALID_DATA" 3 "SEQUENCE" 2 "CHECKSUM" 1 "LENGTH" 0 "NONE" ;
VAL_ 1486 PARK_sw079_errorType 5 "OVERRUN" 4 "INVALID_DATA" 3 "SEQUENCE" 2 "CHECKSUM" 1 "LENGTH" 0 "NONE" ;
VAL_ 1486 PARK_sw080_errorType 5 "OVERRUN" 4 "INVALID_DATA" 3 "SEQUENCE" 2 "CHECKSUM" 1 "LENGTH" 0 "NONE" ;
VAL_ 1486 PARK_sw081_errorType 5 "OVERRUN" 4 "INVALID_DATA" 3 "SEQUENCE" 2 "CHECKSUM" 1 "LENGTH" 0 "NONE" ;
VAL_ 1486 PARK_sw082_errorType 5 "OVERRUN" 4 "INVALID_DATA" 3 "SEQUENCE" 2 "CHECKSUM" 1 "LENGTH" 0 "NONE" ;
VAL_ 1486 PARK_sw083_errorType 5 "OVERRUN" 4 "INVALID_DATA" 3 "SEQUENCE" 2 "CHECKSUM" 1 "LENGTH" 0 "NONE" ;
VAL_ 1486 PARK_sw084_errorType 5 "OVERRUN" 4 "INVALID_DATA" 3 "SEQUENCE" 2 "CHECKSUM" 1 "LENGTH" 0 "NONE" ;
VAL_ 1486 PARK_sw087_s1_sensorType 3 "SNA" 2 "VALEO_HP" 1 "VALEO_HPFL" 0 "NONE" ;
VAL_ 1486 PARK_sw087_s2_sensorType 3 "SNA" 2 "VALEO_HP" 1 "VALEO_HPFL" 0 "NONE" ;
VAL_ 1486 PARK_sw087_s3_sensorType 3 "SNA" 2 "VALEO_HP" 1 "VALEO_HPFL" 0 "NONE" ;
VAL_ 1486 PARK_sw087_s4_sensorType 3 "SNA" 2 "VALEO_HP" 1 "VALEO_HPFL" 0 "NONE" ;
VAL_ 1486 PARK_sw087_s5_sensorType 3 "SNA" 2 "VALEO_HP" 1 "VALEO_HPFL" 0 "NONE" ;
VAL_ 1486 PARK_sw087_s6_sensorType 3 "SNA" 2 "VALEO_HP" 1 "VALEO_HPFL" 0 "NONE" ;
VAL_ 1486 PARK_sw087_s7_sensorType 3 "SNA" 2 "VALEO_HP" 1 "VALEO_HPFL" 0 "NONE" ;
VAL_ 1486 PARK_sw087_s8_sensorType 3 "SNA" 2 "VALEO_HP" 1 "VALEO_HPFL" 0 "NONE" ;
VAL_ 1486 PARK_sw087_s9_sensorType 3 "SNA" 2 "VALEO_HP" 1 "VALEO_HPFL" 0 "NONE" ;
VAL_ 1486 PARK_sw087_s10_sensorType 3 "SNA" 2 "VALEO_HP" 1 "VALEO_HPFL" 0 "NONE" ;
VAL_ 1486 PARK_sw087_s11_sensorType 3 "SNA" 2 "VALEO_HP" 1 "VALEO_HPFL" 0 "NONE" ;
VAL_ 1486 PARK_sw087_s12_sensorType 3 "SNA" 2 "VALEO_HP" 1 "VALEO_HPFL" 0 "NONE" ;
VAL_ 806 PARK_infoIndex 255 "END" 31 "SUBCOMPONENT_GITHASH" 30 "PACKAGE_SN_8_14" 29 "PACKAGE_SN_1_7" 27 "PACKAGE_PN_15_20" 26 "PACKAGE_PN_8_14" 25 "PACKAGE_PN_1_7" 23 "SUBCOMPONENT2" 22 "VARIANTCRC" 20 "UDS_PROTOCOL_BOOTCRC" 19 "VERSION_DEPRECATED" 18 "BOOTLOADER_GITHASH" 17 "APP_GITHASH" 16 "SUBCOMPONENT" 15 "BOOTLOADER_CRC" 14 "BOOTLOADER_SVN" 13 "APP_CRC" 11 "PCBAID_ASSYID_USAGEID" 10 "BUILD_HWID_COMPONENTID" 9 "DEPRECATED_9" 8 "DEPRECATED_8" 7 "DEPRECATED_7" 6 "DEPRECATED_6" 5 "DEPRECATED_5" 4 "DEPRECATED_4" 3 "DEPRECATED_3" 2 "DEPRECATED_2" 1 "DEPRECATED_1" 0 "DEPRECATED_0" ;
VAL_ 806 PARK_infoBuildType 4 "INFO_MFG_BUILD" 3 "INFO_TRACEABLE_CI_BUILD" 2 "INFO_LOCAL_BUILD" 1 "INFO_PLATFORM_BUILD" 0 "INFO_UNKNOWN_BUILD" ;
VAL_ 846 PARK_frontLeftMiddleRawDistData 255 "SNA" ;
VAL_ 846 PARK_frontMiddleRawDistData 255 "SNA" ;
VAL_ 846 PARK_frontRightMiddleRawDistData 255 "SNA" ;
VAL_ 862 PARK_rearLeftMiddleRawDistData 255 "SNA" ;
VAL_ 862 PARK_rearMiddleRawDistData 255 "SNA" ;
VAL_ 862 PARK_rearRightMiddleRawDistData 255 "SNA" ;
VAL_ 926 PARK_rightSideFrontRawDistData 255 "SNA" ;
VAL_ 926 PARK_rightSideRearRawDistData 255 "SNA" ;
VAL_ 926 PARK_leftSideFrontRawDistData 255 "SNA" ;
VAL_ 926 PARK_leftSideRearRawDistData 255 "SNA" ;
VAL_ 606 PARK_pscEnvSlotType 3 "RIGHT_CROSS" 2 "RIGHT_PARALLEL" 1 "LEFT_CROSS" 0 "LEFT_PARALLEL" ;
VAL_ 606 PARK_pscLeftParallelObj1X 2047 "SNA" 2046 "NO_SPACE" ;
VAL_ 606 PARK_pscLeftParallelObj1Y 2047 "SNA" 2046 "NO_SPACE" ;
VAL_ 606 PARK_pscLeftParallelObj1Alpha 127 "SNA" 126 "NO_SPACE" ;
VAL_ 606 PARK_pscLeftParallelObj2Y 2047 "SNA" 2046 "NO_SPACE" ;
VAL_ 606 PARK_pscLeftParallelObj2X 2047 "SNA" 2046 "NO_SPACE" ;
VAL_ 606 PARK_pscLeftParallelObj2Alpha 127 "SNA" 126 "NO_SPACE" ;
VAL_ 606 PARK_pscLeftCrossObj1X 2047 "SNA" 2046 "NO_SPACE" ;
VAL_ 606 PARK_pscLeftCrossObj1Y 2047 "SNA" 2046 "NO_SPACE" ;
VAL_ 606 PARK_pscLeftCrossObj1Alpha 127 "SNA" 126 "NO_SPACE" ;
VAL_ 606 PARK_pscLeftCrossObj2Y 2047 "SNA" 2046 "NO_SPACE" ;
VAL_ 606 PARK_pscLeftCrossObj2X 2047 "SNA" 2046 "NO_SPACE" ;
VAL_ 606 PARK_pscLeftCrossObj2Alpha 127 "SNA" 126 "NO_SPACE" ;
VAL_ 606 PARK_pscRightParallelObj1X 2047 "SNA" 2046 "NO_SPACE" ;
VAL_ 606 PARK_pscRightParallelObj1Y 2047 "SNA" 2046 "NO_SPACE" ;
VAL_ 606 PARK_pscRightParallelObj1Alpha 127 "SNA" 126 "NO_SPACE" ;
VAL_ 606 PARK_pscRightParallelObj2Y 2047 "SNA" 2046 "NO_SPACE" ;
VAL_ 606 PARK_pscRightParallelObj2X 2047 "SNA" 2046 "NO_SPACE" ;
VAL_ 606 PARK_pscRightParallelObj2Alpha 127 "SNA" 126 "NO_SPACE" ;
VAL_ 606 PARK_pscRightCrossObj1X 2047 "SNA" 2046 "NO_SPACE" ;
VAL_ 606 PARK_pscRightCrossObj1Y 2047 "SNA" 2046 "NO_SPACE" ;
VAL_ 606 PARK_pscRightCrossObj1Alpha 127 "SNA" 126 "NO_SPACE" ;
VAL_ 606 PARK_pscRightCrossObj2Y 2047 "SNA" 2046 "NO_SPACE" ;
VAL_ 606 PARK_pscRightCrossObj2X 2047 "SNA" 2046 "NO_SPACE" ;
VAL_ 606 PARK_pscRightCrossObj2Alpha 127 "SNA" 126 "NO_SPACE" ;
VAL_ 542 PARK_pscParkStatus 7 "SNA" 6 "FAULT" 5 "GUIDANCE_FINISHED" 4 "PRE_GUIDANCE" 3 "GUIDANCE_RIGHT" 2 "GUIDANCE_LEFT" 1 "SEARCHING" 0 "NOT_AVAILABLE" ;
VAL_ 542 PARK_pscParkAbortReason 31 "SNA" 25 "PSC_MOVEMENT_AT_ACTIVATION" 24 "PSC_MAX_WAY_BEHIND_HINT" 23 "PSC_PARK_STC_FAILED" 22 "PSC_PARK_PONR_NOT_REACHED" 21 "PSC_VCTL_GENERAL_ABORT" 20 "PSC_HIGH_TORQUE" 19 "PSC_ASYNC_CTRL_SYSTEM" 18 "ERROR" 17 "SYSTEM_SERVICE" 16 "SYSTEM_FAULT" 15 "ECU_INTERNAL_FAULT" 14 "DAS_ABORT" 13 "EPAS_FAULT" 12 "VEHICLE_DYNAMICS_INTERVENTION" 11 "HANDS_ON_DETECTED" 10 "FULL_WARNING_ON_BOTH_SIDES" 9 "PARK_SPACE_TOO_SMALL" 8 "OBSTACLE_ON_PATH" 7 "MAX_YAW_ANGLE_REACHED" 6 "MAX_SWA_DEV_EXCEEDED" 5 "OFF_TRACK" 4 "UNCONTROLLED_TRAVEL_DIST_REACHED" 3 "NO_VALID_PATH" 2 "MAX_NUM_OF_MOVES" 1 "VELOCITY_TOO_HIGH" 0 "NONE" ;
VAL_ 542 PARK_pscParallelSpace 3 "BOTH_AVAILABLE" 2 "LEFT_AVAILABLE" 1 "RIGHT_AVAILABLE" 0 "NONE_AVAILABLE" ;
VAL_ 542 PARK_pscCrossSpace 3 "BOTH_AVAILABLE" 2 "LEFT_AVAILABLE" 1 "RIGHT_AVAILABLE" 0 "NONE_AVAILABLE" ;
VAL_ 542 PARK_pscParallelRightParkable 3 "SNA" 2 "PARKING_SLOT_OK_POSITION_OK" 1 "PARKING_SLOT_OK" 0 "NONE" ;
VAL_ 542 PARK_pscParallelLeftParkable 3 "SNA" 2 "PARKING_SLOT_OK_POSITION_OK" 1 "PARKING_SLOT_OK" 0 "NONE" ;
VAL_ 542 PARK_pscCrossRightParkable 3 "SNA" 2 "PARKING_SLOT_OK_POSITION_OK" 1 "PARKING_SLOT_OK" 0 "NONE" ;
VAL_ 542 PARK_pscMaxVelocity 63 "SNA" ;
VAL_ 542 PARK_pscCrossLeftParkable 3 "SNA" 2 "PARKING_SLOT_OK_POSITION_OK" 1 "PARKING_SLOT_OK" 0 "NONE" ;
VAL_ 542 PARK_pscParkInstruction 7 "SNA" 5 "EXPLORATION" 4 "ABORTED" 3 "DRIVE_BACKWARD" 2 "DRIVE_FORWARD" 1 "STOP" 0 "NO_MESSAGE" ;
VAL_ 542 PARK_pscManeuverDistance 2047 "SNA" ;
VAL_ 542 PARK_pscAngleActive 1 "REQUEST_CONTROL" 0 "INACTIVE" ;
VAL_ 590 PARK_pscVehSlotType 3 "RIGHT_CROSS" 2 "RIGHT_PARALLEL" 1 "LEFT_CROSS" 0 "LEFT_PARALLEL" ;
VAL_ 590 PARK_pscLeftParallelVehX 2047 "SNA" 2046 "NO_SPACE" ;
VAL_ 590 PARK_pscLeftParallelVehY 2047 "SNA" 2046 "NO_SPACE" ;
VAL_ 590 PARK_pscLeftParallelPsi 8191 "SNA" 8190 "NO_SPACE" ;
VAL_ 590 PARK_pscLeftParallelSizeX 255 "SNA" 254 "NO_SPACE" ;
VAL_ 590 PARK_pscLeftParallelSizeY 255 "SNA" 254 "NO_SPACE" ;
VAL_ 590 PARK_pscLeftCrossVehX 2047 "SNA" 2046 "NO_SPACE" ;
VAL_ 590 PARK_pscLeftCrossVehY 2047 "SNA" 2046 "NO_SPACE" ;
VAL_ 590 PARK_pscLeftCrossPsi 8191 "SNA" 8190 "NO_SPACE" ;
VAL_ 590 PARK_pscLeftCrossSizeX 255 "SNA" 254 "NO_SPACE" ;
VAL_ 590 PARK_pscLeftCrossSizeY 255 "SNA" 254 "NO_SPACE" ;
VAL_ 590 PARK_pscRightParallelVehX 2047 "SNA" 2046 "NO_SPACE" ;
VAL_ 590 PARK_pscRightParallelVehY 2047 "SNA" 2046 "NO_SPACE" ;
VAL_ 590 PARK_pscRightParallelPsi 8191 "SNA" 8190 "NO_SPACE" ;
VAL_ 590 PARK_pscRightParallelSizeX 255 "SNA" 254 "NO_SPACE" ;
VAL_ 590 PARK_pscRightParallelSizeY 255 "SNA" 254 "NO_SPACE" ;
VAL_ 590 PARK_pscRightCrossVehX 2047 "SNA" 2046 "NO_SPACE" ;
VAL_ 590 PARK_pscRightCrossVehY 2047 "SNA" 2046 "NO_SPACE" ;
VAL_ 590 PARK_pscRightCrossPsi 8191 "SNA" 8190 "NO_SPACE" ;
VAL_ 590 PARK_pscRightCrossSizeX 255 "SNA" 254 "NO_SPACE" ;
VAL_ 590 PARK_pscRightCrossSizeY 255 "SNA" 254 "NO_SPACE" ;
VAL_ 526 PARK_sdiSensor1RawDistData 511 "SNA" 500 "NO_OBJECT_DETECTED" 1 "NEAR_DETECTION" 0 "BLOCKED" ;
VAL_ 526 PARK_sdiSensor2RawDistData 511 "SNA" 500 "NO_OBJECT_DETECTED" 1 "NEAR_DETECTION" 0 "BLOCKED" ;
VAL_ 526 PARK_sdiSensor3RawDistData 511 "SNA" 500 "NO_OBJECT_DETECTED" 1 "NEAR_DETECTION" 0 "BLOCKED" ;
VAL_ 526 PARK_sdiSensor4RawDistData 511 "SNA" 500 "NO_OBJECT_DETECTED" 1 "NEAR_DETECTION" 0 "BLOCKED" ;
VAL_ 526 PARK_sdiSensor5RawDistData 511 "SNA" 500 "NO_OBJECT_DETECTED" 1 "NEAR_DETECTION" 0 "BLOCKED" ;
VAL_ 526 PARK_sdiSensor6RawDistData 511 "SNA" 500 "NO_OBJECT_DETECTED" 1 "NEAR_DETECTION" 0 "BLOCKED" ;
VAL_ 558 PARK_sdiSensor7RawDistData 511 "SNA" 500 "NO_OBJECT_DETECTED" 1 "NEAR_DETECTION" 0 "BLOCKED" ;
VAL_ 558 PARK_sdiSensor8RawDistData 511 "SNA" 500 "NO_OBJECT_DETECTED" 1 "NEAR_DETECTION" 0 "BLOCKED" ;
VAL_ 558 PARK_sdiSensor9RawDistData 511 "SNA" 500 "NO_OBJECT_DETECTED" 1 "NEAR_DETECTION" 0 "BLOCKED" ;
VAL_ 558 PARK_sdiSensor10RawDistData 511 "SNA" 500 "NO_OBJECT_DETECTED" 1 "NEAR_DETECTION" 0 "BLOCKED" ;
VAL_ 558 PARK_sdiSensor11RawDistData 511 "SNA" 500 "NO_OBJECT_DETECTED" 1 "NEAR_DETECTION" 0 "BLOCKED" ;
VAL_ 558 PARK_sdiSensor12RawDistData 511 "SNA" 500 "NO_OBJECT_DETECTED" 1 "NEAR_DETECTION" 0 "BLOCKED" ;
VAL_ 814 PARK_frontRightSensorState 3 "SNA" 2 "TEMPORARY_FAILURE" 1 "PERMANENT_FAILURE" 0 "NO_FAILURE" ;
VAL_ 814 PARK_frontRightMiddleSensorState 3 "SNA" 2 "TEMPORARY_FAILURE" 1 "PERMANENT_FAILURE" 0 "NO_FAILURE" ;
VAL_ 814 PARK_frontLeftMiddleSensorState 3 "SNA" 2 "TEMPORARY_FAILURE" 1 "PERMANENT_FAILURE" 0 "NO_FAILURE" ;
VAL_ 814 PARK_frontLeftSensorState 3 "SNA" 2 "TEMPORARY_FAILURE" 1 "PERMANENT_FAILURE" 0 "NO_FAILURE" ;
VAL_ 814 PARK_frontLeftRawDistData 255 "SNA" ;
VAL_ 814 PARK_frontRightRawDistData 255 "SNA" ;
VAL_ 814 PARK_systemStatusFront 3 "SNA" 2 "UNUSED" 1 "ENABLED" 0 "DISABLED" ;
VAL_ 814 PARK_frontDtcPresent 3 "SNA" 2 "UNUSED" 1 "TRUE" 0 "FALSE" ;
VAL_ 830 PARK_rearRightSensorState 3 "SNA" 2 "TEMPORARY_FAILURE" 1 "PERMANENT_FAILURE" 0 "NO_FAILURE" ;
VAL_ 830 PARK_rearRightMiddleSensorState 3 "SNA" 2 "TEMPORARY_FAILURE" 1 "PERMANENT_FAILURE" 0 "NO_FAILURE" ;
VAL_ 830 PARK_rearLeftMiddleSensorState 3 "SNA" 2 "TEMPORARY_FAILURE" 1 "PERMANENT_FAILURE" 0 "NO_FAILURE" ;
VAL_ 830 PARK_rearLeftSensorState 3 "SNA" 2 "TEMPORARY_FAILURE" 1 "PERMANENT_FAILURE" 0 "NO_FAILURE" ;
VAL_ 830 PARK_rearLeftRawDistData 255 "SNA" ;
VAL_ 830 PARK_rearRightRawDistData 255 "SNA" ;
VAL_ 830 PARK_systemStatusRear 3 "SNA" 2 "UNUSED" 1 "ENABLED" 0 "DISABLED" ;
VAL_ 830 PARK_rearDtcPresent 3 "SNA" 2 "UNUSED" 1 "TRUE" 0 "FALSE" ;
VAL_ 798 PARK_status 3 "SNA" 2 "TEMPORARY_FAILURE" 1 "ENABLED" 0 "DISABLED" ;
VAL_ 798 PARK_serviceRequest 3 "SNA" 2 "UNUSED" 1 "FAILURE" 0 "NO_FAILURE" ;
VAL_ 798 PARK_systemDtcPresent 3 "SNA" 2 "UNUSED" 1 "TRUE" 0 "FALSE" ;
VAL_ 798 PARK_majorVersion 255 "SNA" ;
VAL_ 798 PARK_minorVersion 255 "SNA" ;
VAL_ 798 PARK_subMinorVersion 255 "SNA" ;
VAL_ 782 PARK_pscRightCurbType 2 "HIGH_CURB" 1 "LOW_CURB" 0 "VIRTUAL_CURB" ;
VAL_ 782 PARK_pscLeftCurbType 2 "HIGH_CURB" 1 "LOW_CURB" 0 "VIRTUAL_CURB" ;
VAL_ 782 PARK_autoCalComplete 1 "COMPLETE" 0 "INCOMPLETE" ;
VAL_ 782 PARK_geometryType 3 "MODELY" 2 "MODEL3" 1 "MODELX" 0 "MODELS" ;
VAL_ 782 PARK_tireFitment 3 "SNA" 2 "NOT_USED" 1 "STAGGERED" 0 "SQUARE" ;
VAL_ 782 PARK_rackDetected 3 "SNA" 2 "RACK_DETECTED" 1 "NO_RACK" 0 "UNKNOWN" ;
VAL_ 782 PARK_sdiActive 1 "SDI_ENABLED" 0 "SDI_DISABLED" ;
VAL_ 782 PARK_sdiNoise 3 "SDI_NOISE_SNA" 2 "SDI_NOISE_RAIN" 1 "SDI_NOISE_HIGH" 0 "SDI_NOISE_NOMINAL" ;
VAL_ 782 PARK_sdiBlindSpotRight 3 "SNA" 2 "UNUSED" 1 "WARNING" 0 "NO_WARNING" ;
VAL_ 782 PARK_sdiBlindSpotLeft 3 "SNA" 2 "UNUSED" 1 "WARNING" 0 "NO_WARNING" ;
VAL_ 782 PARK_sensorType 3 "SNA" 2 "VALEO_HP" 1 "VALEO_HPFL" 0 "NONE" ;
VAL_ 894 PARK_matrixIndex 1 "AlertMatrix1" 0 "AlertMatrix0" ;
